VERSION ""

NS_ :

BS_:

BU_: HMI PCU
VAL_TABLE_ uint16_data_max_fault 65535 "Unavailable" ;
VAL_TABLE_ uint8_data_value_fault 255 "Unavailable" ;
VAL_TABLE_ float_data_value_fault 32767 "Unavailable" ;
VAL_TABLE_ uint8_data_value_fault 254 "Invalid" 255 "Unavailable" ;
VAL_TABLE_ uint16_data_value_fault 65535 "Unavailable" 65534 "Invalid" ;
VAL_TABLE_ P00_PCU_S_ActiveNotActive 1 "Not active" 0 "Active" ;
VAL_TABLE_ P00_PCU_S_ready 5 "Ready" 0 "Not ready" ;
VAL_TABLE_ P00_PCU_S_NDR 5 "EV_ndr_fault" 4 "EV_ndr_s" 3 "EV_ndr_p" 2 "EV_ndr_r" 1 "EV_ndr_d" 0 "EV ndr n" ;
VAL_TABLE_ P00_PCU_S_evMode 5 "EV mode slow charge" 4 "EV mode fast charge" 3 "EV mode ready" 2 "EV mode change over" 1 "EV mode precharge" 0 "EV mode off" ;
VAL_TABLE_ P00_PCU_S_systemMode 9 "system_mode_sna_s" 8 "system_mode_safe_s" 7 "system_mode_secure_shutdown_s" 6 "system_mode_degraded_s" 5 "system_mode_obd_s" 4 "system_mode_operational_s" 3 "system_mode_pre_operational_s" 2 "system_mode_warmup_s" 1 "system_mode_configuration_s" 0 "system_mode_initialisation_s" ;

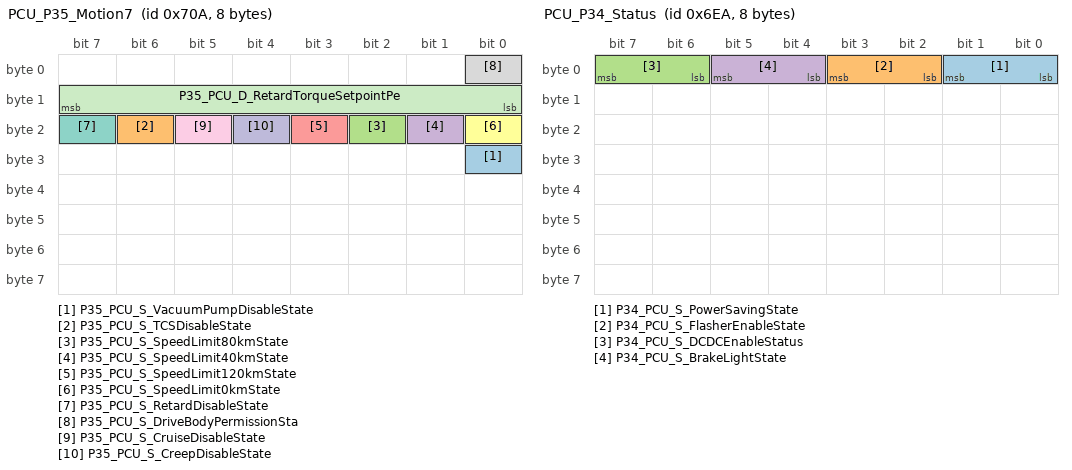
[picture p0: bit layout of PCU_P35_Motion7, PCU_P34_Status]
BO_ 1802 PCU_P35_Motion7: 8 PCU
 SG_ P35_PCU_S_VacuumPumpDisableState : 24|1@0+ (1,0) [0|1] ""  HMI
 SG_ P35_PCU_S_TCSDisableState : 22|1@0+ (1,0) [0|1] ""  HMI
 SG_ P35_PCU_S_SpeedLimit80kmState : 18|1@0+ (1,0) [0|1] ""  HMI
 SG_ P35_PCU_S_SpeedLimit40kmState : 17|1@0+ (1,0) [0|1] ""  HMI
 SG_ P35_PCU_S_SpeedLimit120kmState : 19|1@0+ (1,0) [0|1] ""  HMI
 SG_ P35_PCU_S_SpeedLimit0kmState : 16|1@0+ (1,0) [0|1] ""  HMI
 SG_ P35_PCU_S_RetardDisableState : 23|1@0+ (1,0) [0|1] ""  HMI
 SG_ P35_PCU_S_DriveBodyPermissionSta : 0|1@0+ (1,0) [0|1] ""  HMI
 SG_ P35_PCU_S_CruiseDisableState : 21|1@0+ (1,0) [0|1] ""  HMI
 SG_ P35_PCU_S_CreepDisableState : 20|1@0+ (1,0) [0|1] ""  HMI
 SG_ P35_PCU_D_RetardTorqueSetpointPe : 15|8@0+ (1,0) [0|100] "%"  HMI

BO_ 1770 PCU_P34_Status: 8 PCU
 SG_ P34_PCU_S_PowerSavingState : 1|2@0+ (1,0) [0|1] ""  HMI
 SG_ P34_PCU_S_FlasherEnableState : 3|2@0+ (1,0) [0|3] ""  HMI
 SG_ P34_PCU_S_DCDCEnableStatus : 7|2@0+ (1,0) [0|3] ""  HMI
 SG_ P34_PCU_S_BrakeLightState : 5|2@0+ (1,0) [0|3] ""  HMI

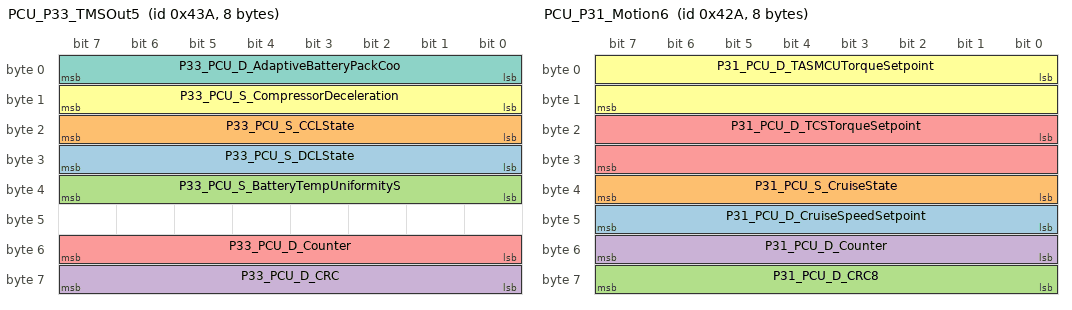
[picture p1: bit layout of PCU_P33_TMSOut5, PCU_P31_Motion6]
BO_ 1082 PCU_P33_TMSOut5: 8 PCU
 SG_ P33_PCU_S_DCLState : 31|8@0+ (1,0) [0|2] "" Vector__XXX
 SG_ P33_PCU_S_CCLState : 23|8@0+ (1,0) [0|2] "" Vector__XXX
 SG_ P33_PCU_S_BatteryTempUniformityS : 39|8@0+ (1,0) [0|2] "" Vector__XXX
 SG_ P33_PCU_D_CRC : 63|8@0+ (1,0) [0|255] ""  HMI
 SG_ P33_PCU_D_Counter : 55|8@0+ (1,0) [0|255] ""  HMI
 SG_ P33_PCU_S_CompressorDeceleration : 15|8@0+ (1,0) [0|1] ""  HMI
 SG_ P33_PCU_D_AdaptiveBatteryPackCoo : 7|8@0+ (1,0) [0|50] "�C"  HMI

BO_ 1066 PCU_P31_Motion6: 8 PCU
 SG_ P31_PCU_D_CruiseSpeedSetpoint : 40|8@1+ (100,0) [0|25300] "rpm"  HMI
 SG_ P31_PCU_S_CruiseState : 32|8@1+ (1,0) [0|2] ""  HMI
 SG_ P31_PCU_D_CRC8 : 63|8@0+ (1,0) [0|255] ""  HMI
 SG_ P31_PCU_D_Counter : 55|8@0+ (1,0) [0|255] ""  HMI
 SG_ P31_PCU_D_TCSTorqueSetpoint : 16|16@1+ (1,-300) [-210|210] "N.m"  HMI
 SG_ P31_PCU_D_TASMCUTorqueSetpoint : 0|16@1+ (1,-300) [-210|210] "N.m"  HMI

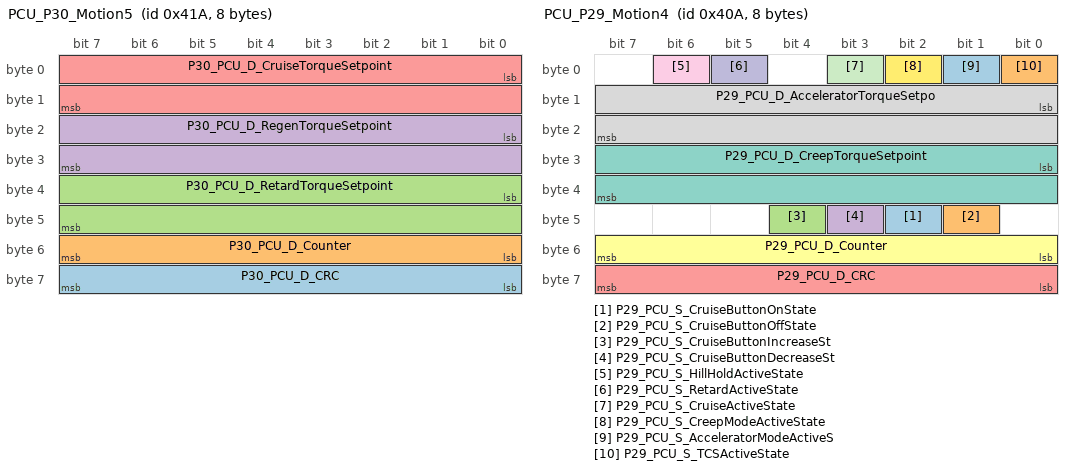
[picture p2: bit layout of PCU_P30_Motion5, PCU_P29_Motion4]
BO_ 1050 PCU_P30_Motion5: 8 PCU
 SG_ P30_PCU_D_CRC : 63|8@0+ (1,0) [0|255] ""  HMI
 SG_ P30_PCU_D_Counter : 55|8@0+ (1,0) [0|255] ""  HMI
 SG_ P30_PCU_D_RetardTorqueSetpoint : 32|16@1+ (1,-300) [0|210] "N.m"  HMI
 SG_ P30_PCU_D_RegenTorqueSetpoint : 16|16@1+ (1,-300) [0|210] "N.m"  HMI
 SG_ P30_PCU_D_CruiseTorqueSetpoint : 0|16@1+ (1,-300) [0|210] "N.m"  HMI

BO_ 1034 PCU_P29_Motion4: 8 PCU
 SG_ P29_PCU_S_CruiseButtonOnState : 42|1@0+ (1,0) [0|1] ""  HMI
 SG_ P29_PCU_S_CruiseButtonOffState : 41|1@0+ (1,0) [0|1] ""  HMI
 SG_ P29_PCU_S_CruiseButtonIncreaseSt : 44|1@0+ (1,0) [0|1] ""  HMI
 SG_ P29_PCU_S_CruiseButtonDecreaseSt : 43|1@0+ (1,0) [0|1] ""  HMI
 SG_ P29_PCU_D_CRC : 63|8@0+ (1,0) [0|255] ""  HMI
 SG_ P29_PCU_D_Counter : 55|8@0+ (1,0) [0|255] ""  HMI
 SG_ P29_PCU_D_CreepTorqueSetpoint : 24|16@1+ (1,-300) [0|210] "N.m"  HMI
 SG_ P29_PCU_D_AcceleratorTorqueSetpo : 8|16@1+ (1,-300) [0|210] "N.m"  HMI
 SG_ P29_PCU_S_HillHoldActiveState : 6|1@0+ (1,0) [0|1] ""  HMI
 SG_ P29_PCU_S_RetardActiveState : 5|1@0+ (1,0) [0|1] ""  HMI
 SG_ P29_PCU_S_CruiseActiveState : 3|1@0+ (1,0) [0|1] ""  HMI
 SG_ P29_PCU_S_CreepModeActiveState : 2|1@0+ (1,0) [0|1] ""  HMI
 SG_ P29_PCU_S_AcceleratorModeActiveS : 1|1@0+ (1,0) [0|1] ""  HMI
 SG_ P29_PCU_S_TCSActiveState : 0|1@0+ (1,0) [0|1] ""  HMI

BO_ 1578 PCU_P32_Fault: 8 PCU
 SG_ P32_PCU_F_EEPROMCellCycleTimeout : 36|1@0+ (1,0) [0|1] "" Vector__XXX
 SG_ P32_PCU_F_EEPROMMCUIDTimeoutFaul : 35|1@0+ (1,0) [0|1] "" Vector__XXX
 SG_ P32_PCU_F_DOLFault : 34|1@0+ (1,0) [0|1] "" Vector__XXX
 SG_ P32_PCU_F_FanLowSpeedAbnormalFau : 23|1@0+ (1,0) [0|1] ""  HMI
 SG_ P32_PCU_F_FanHighSpeedAbnormalFa : 22|1@0+ (1,0) [0|1] ""  HMI
 SG_ P32_PCU_F_CabinCoolerValveOpenWi : 29|1@0+ (1,0) [0|1] ""  HMI
 SG_ P32_PCU_F_BatteryChillerValveOpe : 27|1@0+ (1,0) [0|1] ""  HMI
 SG_ P32_PCU_F_FanHighSpeedAbnormalPr : 21|1@0+ (1,0) [0|1] ""  HMI
 SG_ P32_PCU_F_PressureSwitchAbnormal : 33|1@0+ (1,0) [0|1] ""  HMI
 SG_ P32_PCU_F_PressureSwitchHardware : 32|1@0+ (1,0) [0|1] ""  HMI
 SG_ P32_PCU_F_CabinCoolerValveShortC : 18|1@0+ (1,0) [0|1] ""  HMI
 SG_ P32_PCU_F_BatteryChillerValveSho : 16|1@0+ (1,0) [0|1] ""  HMI
 SG_ P32_PCU_F_FlashTimeoutFault : 12|1@0+ (1,0) [0|1] ""  HMI
 SG_ P32_PCU_F_EEPROMODOTimeoutFault : 11|1@0+ (1,0) [0|1] ""  HMI
 SG_ P32_PCU_F_CANFDTxFIFOFullFault : 10|1@0+ (1,0) [0|1] ""  HMI
 SG_ P32_PCU_F_CANFDTxBusOffFault : 9|1@0+ (1,0) [0|1] ""  HMI
 SG_ P32_PCU_F_CANFDTxBusPassiveFault : 8|1@0+ (1,0) [0|1] ""  HMI
 SG_ P32_PCU_F_CANFDRxBusPassiveFault : 7|1@0+ (1,0) [0|1] ""  HMI
 SG_ P32_PCU_F_DiSpiTemperatureShutDo : 6|1@0+ (1,0) [0|1] ""  HMI
 SG_ P32_PCU_F_DiSpiCheckFault : 2|1@0+ (1,0) [0|1] ""  HMI
 SG_ P32_PCU_F_DiSpiTemperatureWarnin : 5|1@0+ (1,0) [0|1] ""  HMI
 SG_ P32_PCU_F_DiSpiOverVoltageFault : 4|1@0+ (1,0) [0|1] ""  HMI
 SG_ P32_PCU_F_DiSpiUnderVoltageFault : 3|1@0+ (1,0) [0|1] ""  HMI
 SG_ P32_PCU_F_DiSpiParityFault : 1|1@0+ (1,0) [0|1] ""  HMI
 SG_ P32_PCU_F_DiSpiFault : 0|1@0+ (1,0) [0|1] ""  HMI
 SG_ P32_PCU_D_Counter : 55|8@0+ (1,0) [0|255] ""  HMI
 SG_ P32_PCU_D_CRC : 63|8@0+ (1,0) [0|255] ""  HMI

BO_ 1514 PCU_P26_Motion1: 8 PCU
 SG_ P26_PCU_S_RegenState : 9|1@0+ (1,0) [0|1] ""  HMI
 SG_ P26_PCU_S_RegenSOCDerateState : 20|1@0+ (1,0) [0|1] ""  HMI
 SG_ P26_PCU_S_RegenMotorDerateState : 18|1@0+ (1,0) [0|1] ""  HMI
 SG_ P26_PCU_S_RegenMCUDerateState : 17|1@0+ (1,0) [0|1] ""  HMI
 SG_ P26_PCU_S_RegenBatteryDerateStat : 19|1@0+ (1,0) [0|1] ""  HMI
 SG_ P26_PCU_S_HillholdPermissionStat : 8|1@0+ (1,0) [0|1] ""  HMI
 SG_ P26_PCU_D_ESCTorqueLimit : 32|16@1+ (1,0) [0|210] "N.m"  HMI
 SG_ P26_PCU_S_ESCTorqueLimitActiveSt : 10|1@0+ (1,0) [0|1] ""  HMI
 SG_ P26_PCU_S_DriveProcessorTempDera : 12|1@0+ (1,0) [0|1] ""  HMI
 SG_ P26_PCU_S_DriveMotorDerateState : 14|1@0+ (1,0) [0|1] ""  HMI
 SG_ P26_PCU_S_DriveMCUDerateState : 13|1@0+ (1,0) [0|1] ""  HMI
 SG_ P26_PCU_S_DriveLVVoltageDerateSt : 11|1@0+ (1,0) [0|1] ""  HMI
 SG_ P26_PCU_S_DriveBatteryDerateStat : 15|1@0+ (1,0) [0|1] ""  HMI
 SG_ P26_PCU_S_DriveSOCDerateState : 16|1@0+ (1,0) [0|1] ""  HMI
 SG_ P26_PCU_S_TCSPermissionState : 0|1@0+ (1,0) [0|1] ""  HMI
 SG_ P26_PCU_S_DrivePermissionState : 1|1@0+ (1,0) [0|1] ""  HMI
 SG_ P26_PCU_S_CreepPermissionState : 2|1@0+ (1,0) [0|1] ""  HMI
 SG_ P26_PCU_S_CruisePermissionState : 3|1@0+ (1,0) [0|1] ""  HMI
 SG_ P26_PCU_S_RetardPermissionState : 5|1@0+ (1,0) [0|1] ""  HMI
 SG_ P26_PCU_S_DriveDerateState : 6|1@0+ (1,0) [0|1] ""  HMI
 SG_ P26_PCU_S_RegenDerateState : 7|1@0+ (1,0) [0|1] ""  HMI
 SG_ P26_PCU_D_MotorMaxPower : 31|8@0+ (1,0) [0|125] "kW"  HMI
 SG_ P26_PCU_D_Counter : 55|8@0+ (1,0) [0|255] ""  HMI
 SG_ P26_PCU_D_CRC : 63|8@0+ (1,0) [0|255] ""  HMI

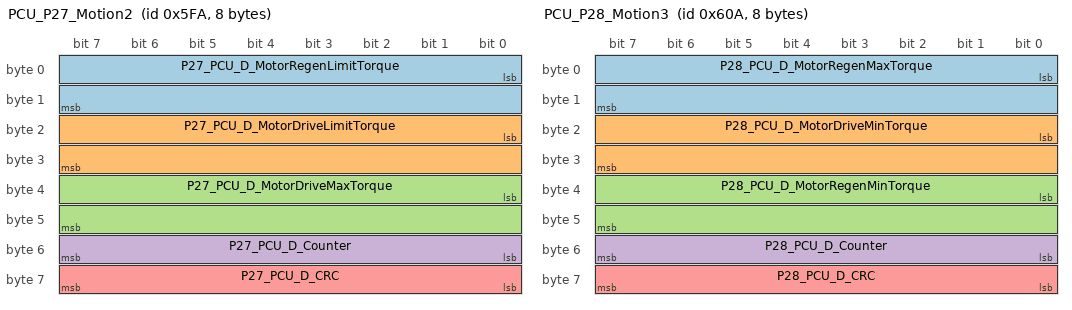
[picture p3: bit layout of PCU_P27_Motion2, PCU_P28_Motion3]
BO_ 1530 PCU_P27_Motion2: 8 PCU
 SG_ P27_PCU_D_MotorRegenLimitTorque : 0|16@1+ (1,0) [0|150] "N.m"  HMI
 SG_ P27_PCU_D_MotorDriveLimitTorque : 16|16@1+ (1,0) [0|210] "N.m"  HMI
 SG_ P27_PCU_D_MotorDriveMaxTorque : 32|16@1+ (1,0) [0|210] "N.m"  HMI
 SG_ P27_PCU_D_Counter : 55|8@0+ (1,0) [0|255] ""  HMI
 SG_ P27_PCU_D_CRC : 63|8@0+ (1,0) [0|255] ""  HMI

BO_ 1546 PCU_P28_Motion3: 8 PCU
 SG_ P28_PCU_D_MotorRegenMaxTorque : 0|16@1+ (1,0) [0|150] "N.m"  HMI
 SG_ P28_PCU_D_MotorDriveMinTorque : 16|16@1+ (1,0) [0|210] "N.m"  HMI
 SG_ P28_PCU_D_MotorRegenMinTorque : 32|16@1+ (1,0) [0|150] "N.m"  HMI
 SG_ P28_PCU_D_Counter : 55|8@0+ (1,0) [0|255] ""  HMI
 SG_ P28_PCU_D_CRC : 63|8@0+ (1,0) [0|255] ""  HMI

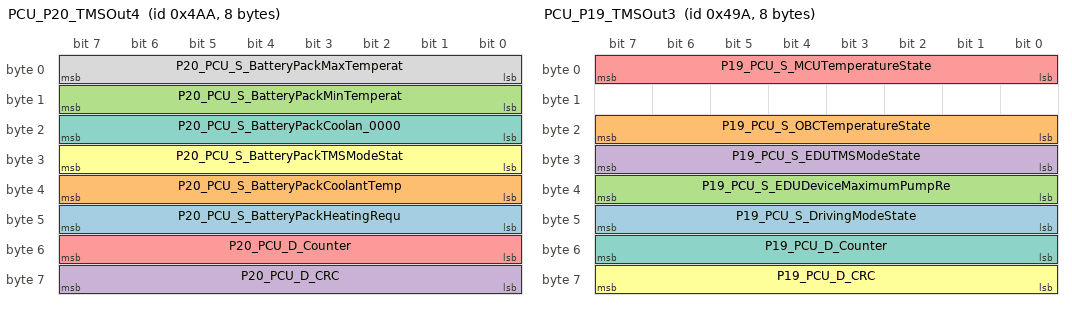
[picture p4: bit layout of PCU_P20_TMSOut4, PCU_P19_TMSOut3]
BO_ 1194 PCU_P20_TMSOut4: 8 PCU
 SG_ P20_PCU_S_BatteryPackHeatingRequ : 47|8@0+ (1,0) [0|1] ""  HMI
 SG_ P20_PCU_S_BatteryPackCoolantTemp : 39|8@0+ (1,0) [0|2] ""  HMI
 SG_ P20_PCU_S_BatteryPackMinTemperat : 15|8@0+ (1,0) [0|11] ""  HMI
 SG_ P20_PCU_D_CRC : 63|8@0+ (1,0) [0|255] ""  HMI
 SG_ P20_PCU_D_Counter : 55|8@0+ (1,0) [0|255] ""  HMI
 SG_ P20_PCU_S_BatteryPackTMSModeStat : 31|8@0+ (1,0) [0|14] ""  HMI
 SG_ P20_PCU_S_BatteryPackCoolan_0000 : 23|8@0+ (1,0) [0|11] ""  HMI
 SG_ P20_PCU_S_BatteryPackMaxTemperat : 7|8@0+ (1,0) [0|11] ""  HMI

BO_ 1178 PCU_P19_TMSOut3: 8 PCU
 SG_ P19_PCU_S_DrivingModeState : 47|8@0+ (1,0) [0|1] ""  HMI
 SG_ P19_PCU_S_OBCTemperatureState : 23|8@0+ (1,0) [0|11] ""  HMI
 SG_ P19_PCU_S_EDUDeviceMaximumPumpRe : 39|8@0+ (1,0) [0|5] ""  HMI
 SG_ P19_PCU_S_EDUTMSModeState : 31|8@0+ (1,0) [0|14] ""  HMI
 SG_ P19_PCU_S_MCUTemperatureState : 7|8@0+ (1,0) [0|11] ""  HMI
 SG_ P19_PCU_D_CRC : 63|8@0+ (1,0) [0|255] ""  HMI
 SG_ P19_PCU_D_Counter : 55|8@0+ (1,0) [0|255] ""  HMI

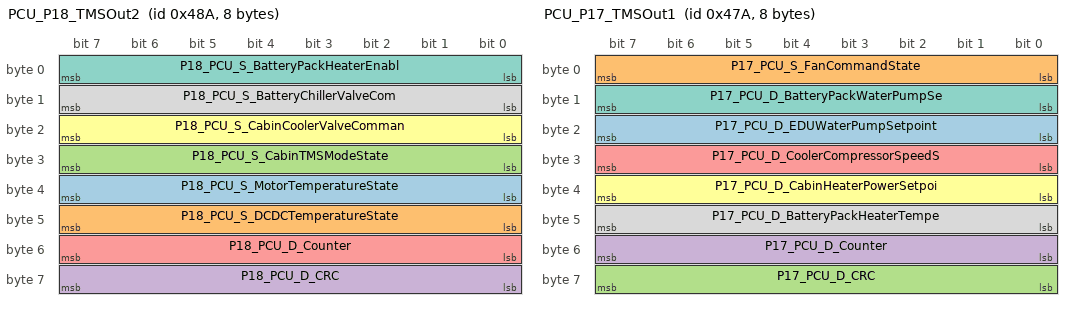
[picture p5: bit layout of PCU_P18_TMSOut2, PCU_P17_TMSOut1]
BO_ 1162 PCU_P18_TMSOut2: 8 PCU
 SG_ P18_PCU_S_MotorTemperatureState : 39|8@0+ (1,0) [0|11] ""  HMI
 SG_ P18_PCU_S_DCDCTemperatureState : 47|8@0+ (1,0) [0|11] ""  HMI
 SG_ P18_PCU_S_CabinTMSModeState : 31|8@0+ (1,0) [0|8] ""  HMI
 SG_ P18_PCU_D_CRC : 63|8@0+ (1,0) [0|255] ""  HMI
 SG_ P18_PCU_D_Counter : 55|8@0+ (1,0) [0|255] ""  HMI
 SG_ P18_PCU_S_CabinCoolerValveComman : 23|8@0+ (1,0) [0|1] ""  HMI
 SG_ P18_PCU_S_BatteryPackHeaterEnabl : 7|8@0+ (1,0) [0|1] ""  HMI
 SG_ P18_PCU_S_BatteryChillerValveCom : 15|8@0+ (1,0) [0|1] ""  HMI

BO_ 1146 PCU_P17_TMSOut1: 8 PCU
 SG_ P17_PCU_D_EDUWaterPumpSetpoint : 23|8@0+ (1,0) [0|100] "%"  HMI
 SG_ P17_PCU_S_FanCommandState : 7|8@0+ (1,0) [0|2] ""  HMI
 SG_ P17_PCU_D_CRC : 63|8@0+ (1,0) [0|255] ""  HMI
 SG_ P17_PCU_D_Counter : 55|8@0+ (1,0) [0|255] ""  HMI
 SG_ P17_PCU_D_CoolerCompressorSpeedS : 31|8@0+ (1,0) [0|100] "%"  HMI
 SG_ P17_PCU_D_CabinHeaterPowerSetpoi : 39|8@0+ (1,0) [0|100] "%"  HMI
 SG_ P17_PCU_D_BatteryPackWaterPumpSe : 15|8@0+ (1,0) [0|100] "%"  HMI
 SG_ P17_PCU_D_BatteryPackHeaterTempe : 47|8@0+ (1,0) [0|80] "�C"  HMI

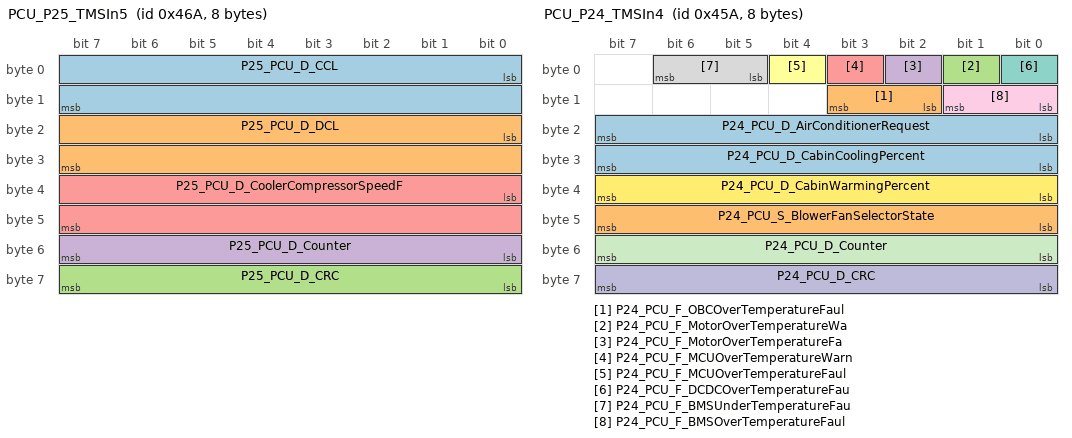
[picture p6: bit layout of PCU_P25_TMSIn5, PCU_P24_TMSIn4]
BO_ 1130 PCU_P25_TMSIn5: 8 PCU
 SG_ P25_PCU_D_CCL : 0|16@1+ (1,0) [0|650] "A"  HMI
 SG_ P25_PCU_D_DCL : 16|16@1+ (1,0) [0|650] "A"  HMI
 SG_ P25_PCU_D_CRC : 63|8@0+ (1,0) [0|255] ""  HMI
 SG_ P25_PCU_D_Counter : 55|8@0+ (1,0) [0|255] ""  HMI
 SG_ P25_PCU_D_CoolerCompressorSpeedF : 32|16@1+ (1,0) [0|16000] "rpm"  HMI

BO_ 1114 PCU_P24_TMSIn4: 8 PCU
 SG_ P24_PCU_D_AirConditionerRequest : 23|8@0+ (1,0) [0|1] ""  HMI
 SG_ P24_PCU_F_OBCOverTemperatureFaul : 11|2@0+ (1,0) [0|3] ""  HMI
 SG_ P24_PCU_F_MotorOverTemperatureWa : 1|1@0+ (1,0) [0|1] ""  HMI
 SG_ P24_PCU_F_MotorOverTemperatureFa : 2|1@0+ (1,0) [0|1] ""  HMI
 SG_ P24_PCU_F_MCUOverTemperatureWarn : 3|1@0+ (1,0) [0|1] ""  HMI
 SG_ P24_PCU_F_MCUOverTemperatureFaul : 4|1@0+ (1,0) [0|1] ""  HMI
 SG_ P24_PCU_F_DCDCOverTemperatureFau : 0|1@0+ (1,0) [0|1] ""  HMI
 SG_ P24_PCU_F_BMSUnderTemperatureFau : 6|2@0+ (1,0) [0|3] ""  HMI
 SG_ P24_PCU_F_BMSOverTemperatureFaul : 9|2@0+ (1,0) [0|3] ""  HMI
 SG_ P24_PCU_D_CRC : 63|8@0+ (1,0) [0|255] ""  HMI
 SG_ P24_PCU_D_Counter : 55|8@0+ (1,0) [0|255] ""  HMI
 SG_ P24_PCU_D_CabinWarmingPercent : 39|8@0+ (1,0) [0|100] "%"  HMI
 SG_ P24_PCU_D_CabinCoolingPercent : 31|8@0+ (1,0) [0|100] "%"  HMI
 SG_ P24_PCU_S_BlowerFanSelectorState : 47|8@0+ (1,0) [0|1] ""  HMI

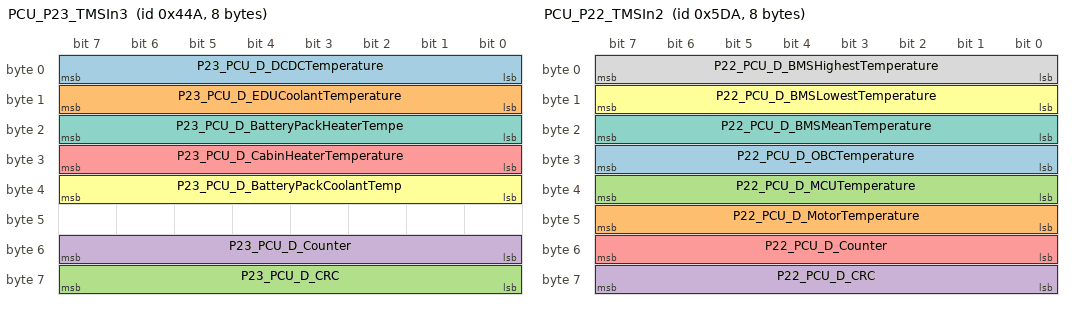
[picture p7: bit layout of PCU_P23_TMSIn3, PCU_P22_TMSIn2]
BO_ 1098 PCU_P23_TMSIn3: 8 PCU
 SG_ P23_PCU_D_DCDCTemperature : 7|8@0+ (1,-40) [-40|210] "�C"  HMI
 SG_ P23_PCU_D_EDUCoolantTemperature : 15|8@0+ (1,-40) [-11|110] "�C"  HMI
 SG_ P23_PCU_D_CRC : 63|8@0+ (1,0) [0|255] ""  HMI
 SG_ P23_PCU_D_Counter : 55|8@0+ (1,0) [0|255] ""  HMI
 SG_ P23_PCU_D_CabinHeaterTemperature : 31|8@0+ (1,-40) [-40|190] "�C"  HMI
 SG_ P23_PCU_D_BatteryPackCoolantTemp : 39|8@0+ (1,-40) [-28|85] "�C"  HMI
 SG_ P23_PCU_D_BatteryPackHeaterTempe : 23|8@0+ (1,-40) [-40|180] "�C"  HMI

BO_ 1498 PCU_P22_TMSIn2: 8 PCU
 SG_ P22_PCU_D_OBCTemperature : 31|8@0+ (1,-40) [-40|210] "�C"  HMI
 SG_ P22_PCU_D_MotorTemperature : 47|8@0+ (1,-40) [-40|210] "�C"  HMI
 SG_ P22_PCU_D_MCUTemperature : 39|8@0+ (1,-40) [-40|210] "�C"  HMI
 SG_ P22_PCU_D_CRC : 63|8@0+ (1,0) [0|255] ""  HMI
 SG_ P22_PCU_D_Counter : 55|8@0+ (1,0) [0|255] ""  HMI
 SG_ P22_PCU_D_BMSLowestTemperature : 15|8@0+ (1,-40) [-40|125] "�C"  HMI
 SG_ P22_PCU_D_BMSMeanTemperature : 23|8@0+ (1,-40) [-40|125] "�C"  HMI
 SG_ P22_PCU_D_BMSHighestTemperature : 7|8@0+ (1,-40) [-40|125] "�C"  HMI

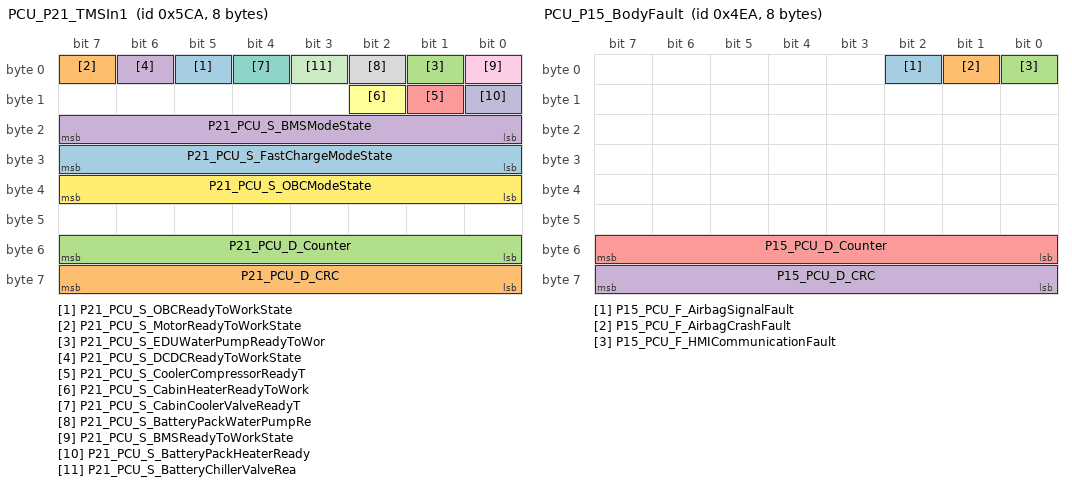
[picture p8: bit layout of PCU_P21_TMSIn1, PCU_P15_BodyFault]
BO_ 1482 PCU_P21_TMSIn1: 8 PCU
 SG_ P21_PCU_S_OBCReadyToWorkState : 5|1@0+ (1,0) [0|1] ""  HMI
 SG_ P21_PCU_S_MotorReadyToWorkState : 7|1@0+ (1,0) [0|1] ""  HMI
 SG_ P21_PCU_S_EDUWaterPumpReadyToWor : 1|1@0+ (1,0) [0|1] ""  HMI
 SG_ P21_PCU_S_DCDCReadyToWorkState : 6|1@0+ (1,0) [0|1] ""  HMI
 SG_ P21_PCU_S_CoolerCompressorReadyT : 9|1@0+ (1,0) [0|1] ""  HMI
 SG_ P21_PCU_S_CabinHeaterReadyToWork : 10|1@0+ (1,0) [0|1] ""  HMI
 SG_ P21_PCU_S_CabinCoolerValveReadyT : 4|1@0+ (1,0) [0|1] ""  HMI
 SG_ P21_PCU_S_BatteryPackWaterPumpRe : 2|1@0+ (1,0) [0|1] ""  HMI
 SG_ P21_PCU_S_BMSReadyToWorkState : 0|1@0+ (1,0) [0|1] ""  HMI
 SG_ P21_PCU_S_BatteryPackHeaterReady : 8|1@0+ (1,0) [0|1] ""  HMI
 SG_ P21_PCU_S_BatteryChillerValveRea : 3|1@0+ (1,0) [0|1] ""  HMI
 SG_ P21_PCU_S_OBCModeState : 39|8@0+ (1,0) [0|5] ""  HMI
 SG_ P21_PCU_S_FastChargeModeState : 31|8@0+ (1,0) [0|7] ""  HMI
 SG_ P21_PCU_D_CRC : 63|8@0+ (1,0) [0|255] ""  HMI
 SG_ P21_PCU_D_Counter : 55|8@0+ (1,0) [0|255] ""  HMI
 SG_ P21_PCU_S_BMSModeState : 23|8@0+ (1,0) [0|7] ""  HMI

BO_ 1274 PCU_P16_TMSFault: 8 PCU
 SG_ P16_PCU_F_TMSBatteryPackTemperat : 36|1@0+ (1,0) [0|1] "" Vector__XXX
 SG_ P16_PCU_F_EDUWaterPumpNoLoadingF : 24|1@0+ (1,0) [0|1] "" Vector__XXX
 SG_ P16_PCU_F_BatteryPackWaterPumpNo : 28|1@0+ (1,0) [0|1] "" Vector__XXX
 SG_ P16_PCU_F_TMSCoolingActuatorPowe : 41|1@0+ (1,0) [0|1] ""  HMI
 SG_ P16_PCU_F_CoolerCompressorHVILFa : 39|1@0+ (1,0) [0|1] ""  HMI
 SG_ P16_PCU_F_BatteryPackHeaterHVILF : 40|1@0+ (1,0) [0|1] ""  HMI
 SG_ P16_PCU_F_BothPumpCommunicationF : 38|1@0+ (1,0) [0|1] ""  HMI
 SG_ P16_PCU_F_BatteryPackHeaterOverC : 37|1@0+ (1,0) [0|1] ""  HMI
 SG_ P16_PCU_F_TMSOBCShutdownFault : 32|1@0+ (1,0) [0|1] ""  HMI
 SG_ P16_PCU_F_TMSMotorShutdownFault : 35|1@0+ (1,0) [0|1] ""  HMI
 SG_ P16_PCU_F_TMSMCUShutdownFault : 34|1@0+ (1,0) [0|1] ""  HMI
 SG_ P16_PCU_F_TMSDCDCShutdownFault : 33|1@0+ (1,0) [0|1] ""  HMI
 SG_ P16_PCU_F_CoolerCompressorOverCu : 6|1@0+ (1,0) [0|1] ""  HMI
 SG_ P16_PCU_F_AirConditionerKeyMisma : 31|1@0+ (1,0) [0|1] ""  HMI
 SG_ P16_PCU_F_EDUCoolantTemperatureS : 30|1@0+ (1,0) [0|1] ""  HMI
 SG_ P16_PCU_F_BatteryPackCoolantTemp : 29|1@0+ (1,0) [0|1] ""  HMI
 SG_ P16_PCU_F_EDUWaterPumpUpdatePara : 23|1@0+ (1,0) [0|1] ""  HMI
 SG_ P16_PCU_F_BatteryPackWaterPumpUp : 27|1@0+ (1,0) [0|1] ""  HMI
 SG_ P16_PCU_F_BatteryPackHeaterHighV : 18|1@0+ (1,0) [0|1] ""  HMI
 SG_ P16_PCU_F_BatteryPackHeaterPower : 17|1@0+ (1,0) [0|1] ""  HMI
 SG_ P16_PCU_F_BatteryPackHeaterShort : 16|1@0+ (1,0) [0|1] ""  HMI
 SG_ P16_PCU_F_CabinHeaterHighVoltage : 12|1@0+ (1,0) [0|1] ""  HMI
 SG_ P16_PCU_F_CabinHeaterPowerUpFaul : 11|1@0+ (1,0) [0|1] ""  HMI
 SG_ P16_PCU_F_CabinHeaterShortCircui : 10|1@0+ (1,0) [0|1] ""  HMI
 SG_ P16_PCU_F_CoolerCompressorHighVo : 5|1@0+ (1,0) [0|1] ""  HMI
 SG_ P16_PCU_F_EDUWaterPumpInternalFa : 22|1@0+ (1,0) [0|1] ""  HMI
 SG_ P16_PCU_F_EDUWaterPumpCommunicat : 21|1@0+ (1,0) [0|1] ""  HMI
 SG_ P16_PCU_F_CoolerCompressorUpdate : 2|1@0+ (1,0) [0|1] ""  HMI
 SG_ P16_PCU_F_CoolerCompressorSpeedF : 4|1@0+ (1,0) [0|1] ""  HMI
 SG_ P16_PCU_F_CoolerCompressorShortC : 3|1@0+ (1,0) [0|1] ""  HMI
 SG_ P16_PCU_F_CoolerCompressorIntern : 0|1@0+ (1,0) [0|1] ""  HMI
 SG_ P16_PCU_F_CoolerCompressorCommun : 1|1@0+ (1,0) [0|1] ""  HMI
 SG_ P16_PCU_F_CabinCoolerValveFault : 19|1@0+ (1,0) [0|1] ""  HMI
 SG_ P16_PCU_F_BatteryPackWaterPumpIn : 26|1@0+ (1,0) [0|1] ""  HMI
 SG_ P16_PCU_F_BatteryPackWaterPumpCo : 25|1@0+ (1,0) [0|1] ""  HMI
 SG_ P16_PCU_F_BatteryPackHeaterUpdat : 15|1@0+ (1,0) [0|1] ""  HMI
 SG_ P16_PCU_F_BatteryPackHeaterInter : 13|1@0+ (1,0) [0|1] ""  HMI
 SG_ P16_PCU_F_BatteryPackHeaterCommu : 14|1@0+ (1,0) [0|1] ""  HMI
 SG_ P16_PCU_F_BatteryChillerValveFau : 20|1@0+ (1,0) [0|1] ""  HMI
 SG_ P16_PCU_F_CabinHeaterUpdateParam : 9|1@0+ (1,0) [0|1] ""  HMI
 SG_ P16_PCU_F_CabinHeaterInternalFau : 7|1@0+ (1,0) [0|1] ""  HMI
 SG_ P16_PCU_F_CabinHeaterCommunicati : 8|1@0+ (1,0) [0|1] ""  HMI
 SG_ P16_PCU_D_CRC : 63|8@0+ (1,0) [0|255] ""  HMI
 SG_ P16_PCU_D_Counter : 55|8@0+ (1,0) [0|255] ""  HMI

BO_ 1258 PCU_P15_BodyFault: 8 PCU
 SG_ P15_PCU_F_AirbagSignalFault : 2|1@0+ (1,0) [0|1] "" Vector__XXX
 SG_ P15_PCU_F_AirbagCrashFault : 1|1@0+ (1,0) [0|1] ""  HMI
 SG_ P15_PCU_F_HMICommunicationFault : 0|1@0+ (1,0) [0|1] ""  HMI
 SG_ P15_PCU_D_CRC : 63|8@0+ (1,0) [0|255] ""  HMI
 SG_ P15_PCU_D_Counter : 55|8@0+ (1,0) [0|255] ""  HMI

BO_ 1242 PCU_P14_EVFault: 8 PCU
 SG_ P14_PCU_F_PCUCANTimeoutFault : 26|1@0+ (1,0) [0|1] "" Vector__XXX
 SG_ P14_PCU_F_EVSOCSlowOverLimitFaul : 22|1@0+ (1,0) [0|1] "" Vector__XXX
 SG_ P14_PCU_F_EVSOCFastOverLimitFaul : 23|1@0+ (1,0) [0|1] "" Vector__XXX
 SG_ P14_PCU_F_EVPluggingFault : 6|1@0+ (1,0) [0|1] ""  HMI
 SG_ P14_PCU_F_EVHVOpenFault : 27|1@0+ (1,0) [0|1] ""  HMI
 SG_ P14_PCU_F_MCUVINMismatchFault : 25|1@0+ (1,0) [0|1] ""  HMI
 SG_ P14_PCU_F_EVAirbagCrashDetectedF : 24|1@0+ (1,0) [0|1] ""  HMI
 SG_ P14_PCU_F_EVInPluggedFault : 21|1@0+ (1,0) [0|1] ""  HMI
 SG_ P14_PCU_F_ProcessorMissingClockD : 5|1@0+ (1,0) [0|1] ""  HMI
 SG_ P14_PCU_F_ProcessorOverTemperatu : 4|1@0+ (1,0) [0|1] ""  HMI
 SG_ P14_PCU_F_5VSupplyUnderVoltageFa : 1|1@0+ (1,0) [0|1] ""  HMI
 SG_ P14_PCU_F_5VSupplyOverVoltageFau : 0|1@0+ (1,0) [0|1] ""  HMI
 SG_ P14_PCU_F_InputUnderVoltageFault : 3|1@0+ (1,0) [0|1] ""  HMI
 SG_ P14_PCU_F_InputOverVoltageFault : 2|1@0+ (1,0) [0|1] ""  HMI
 SG_ P14_PCU_F_EVStartSwitchFault : 17|1@0+ (1,0) [0|1] ""  HMI
 SG_ P14_PCU_F_EVSOCLowFault : 11|1@0+ (1,0) [0|1] ""  HMI
 SG_ P14_PCU_F_EVSOCLimitFault : 12|1@0+ (1,0) [0|1] ""  HMI
 SG_ P14_PCU_F_EVPrechargeTimeoutFaul : 14|1@0+ (1,0) [0|1] ""  HMI
 SG_ P14_PCU_F_EVDCUNotReadyFault : 9|1@0+ (1,0) [0|1] ""  HMI
 SG_ P14_PCU_F_EVDCDCNotReadyFault : 10|1@0+ (1,0) [0|1] ""  HMI
 SG_ P14_PCU_F_EVBMSOpenContactorFaul : 18|1@0+ (1,0) [0|1] ""  HMI
 SG_ P14_PCU_F_EVChargeStopFault : 16|1@0+ (1,0) [0|1] ""  HMI
 SG_ P14_PCU_F_EVBMSNotReadyFault : 8|1@0+ (1,0) [0|1] ""  HMI
 SG_ P14_PCU_D_CRC : 63|8@0+ (1,0) [0|255] ""  HMI
 SG_ P14_PCU_D_Counter : 55|8@0+ (1,0) [0|255] ""  HMI

BO_ 1226 PCU_P13_HVLVFault: 8 PCU
 SG_ P13_PCU_F_OBCOverCurrentFault : 28|1@0+ (1,0) [0|1] ""  HMI
 SG_ P13_PCU_F_BMSModeFault : 27|1@0+ (1,0) [0|1] ""  HMI
 SG_ P13_PCU_F_OBCHighVoltageFault : 26|1@0+ (1,0) [0|1] ""  HMI
 SG_ P13_PCU_F_OBCShortCircuitFault : 25|1@0+ (1,0) [0|1] ""  HMI
 SG_ P13_PCU_F_MCUHighVoltageFault : 21|1@0+ (1,0) [0|1] ""  HMI
 SG_ P13_PCU_F_OBCUpdateParameterFaul : 24|1@0+ (1,0) [0|1] ""  HMI
 SG_ P13_PCU_F_OBCInternalFault : 22|1@0+ (1,0) [0|1] ""  HMI
 SG_ P13_PCU_F_OBCCommunicationFault : 23|1@0+ (1,0) [0|1] ""  HMI
 SG_ P13_PCU_F_MCUUpdateParameterFaul : 20|1@0+ (1,0) [0|1] ""  HMI
 SG_ P13_PCU_F_MCUInternalFault : 18|1@0+ (1,0) [0|1] ""  HMI
 SG_ P13_PCU_F_MCUCommunicationFault : 19|1@0+ (1,0) [0|1] ""  HMI
 SG_ P13_PCU_F_DCDCUpdateParameterFau : 14|1@0+ (1,0) [0|1] ""  HMI
 SG_ P13_PCU_F_DCDCOverTemperatureFau : 16|1@0+ (1,0) [0|1] ""  HMI
 SG_ P13_PCU_F_DCDCLVUnderVoltageFaul : 17|1@0+ (1,0) [0|1] ""  HMI
 SG_ P13_PCU_F_DCDCInternalFault : 12|1@0+ (1,0) [0|1] ""  HMI
 SG_ P13_PCU_F_DCDCHighVoltageFault : 15|1@0+ (1,0) [0|1] ""  HMI
 SG_ P13_PCU_F_DCDCCommunicationFault : 13|1@0+ (1,0) [0|1] ""  HMI
 SG_ P13_PCU_F_BMSUpdateParameterFaul : 2|1@0+ (1,0) [0|1] ""  HMI
 SG_ P13_PCU_F_BMSInternalFault : 0|1@0+ (1,0) [0|1] ""  HMI
 SG_ P13_PCU_F_BMSCommunicationFault : 1|1@0+ (1,0) [0|1] ""  HMI
 SG_ P13_PCU_D_CRC : 63|8@0+ (1,0) [0|255] ""  HMI
 SG_ P13_PCU_D_Counter : 55|8@0+ (1,0) [0|255] ""  HMI
 SG_ P13_PCU_F_NegativeContactorWeldi : 11|1@0+ (1,0) [0|1] ""  HMI
 SG_ P13_PCU_F_NegativeContactorMatch : 9|1@0+ (1,0) [0|1] ""  HMI
 SG_ P13_PCU_F_PositiveContactorWeldi : 8|1@0+ (1,0) [0|1] ""  HMI
 SG_ P13_PCU_F_PositiveContactorMatch : 6|1@0+ (1,0) [0|1] ""  HMI
 SG_ P13_PCU_F_PrechargeContactorWeld : 5|1@0+ (1,0) [0|1] ""  HMI
 SG_ P13_PCU_F_PrechargeContactorMatc : 3|1@0+ (1,0) [0|1] ""  HMI

BO_ 1210 PCU_P12_MotionFault: 8 PCU
 SG_ P12_PCU_F_VacuumPumpPowerFault : 39|1@0+ (1,0) [0|1] ""  HMI
 SG_ P12_PCU_F_EPSInternalFault : 38|1@0+ (1,0) [0|1] ""  HMI
 SG_ P12_PCU_F_BrakePressureInvalidFa : 34|1@0+ (1,0) [0|1] ""  HMI
 SG_ P12_PCU_F_AcceleratorPedalPositi : 33|1@0+ (1,0) [0|1] ""  HMI
 SG_ P12_PCU_F_ESCCommunicationFault : 36|1@0+ (1,0) [0|1] ""  HMI
 SG_ P12_PCU_F_EPSCommunicationFault : 37|1@0+ (1,0) [0|1] ""  HMI
 SG_ P12_PCU_F_BrakeStopLightFault : 35|1@0+ (1,0) [0|1] ""  HMI
 SG_ P12_PCU_F_SASUpdateParameterFaul : 31|1@0+ (1,0) [0|1] ""  HMI
 SG_ P12_PCU_F_SASInternalFault : 29|1@0+ (1,0) [0|1] ""  HMI
 SG_ P12_PCU_F_SASCommunicationFault : 30|1@0+ (1,0) [0|1] ""  HMI
 SG_ P12_PCU_F_CruiseKeyOpenWireFault : 32|1@0+ (1,0) [0|1] ""  HMI
 SG_ P12_PCU_F_ABSRearRightSpeedFault : 28|1@0+ (1,0) [0|1] ""  HMI
 SG_ P12_PCU_F_ABSRearLeftSpeedFault : 27|1@0+ (1,0) [0|1] ""  HMI
 SG_ P12_PCU_F_ABSFrontRightSpeedFaul : 26|1@0+ (1,0) [0|1] ""  HMI
 SG_ P12_PCU_F_ABSFrontLeftSpeedFault : 25|1@0+ (1,0) [0|1] ""  HMI
 SG_ P12_PCU_F_ABSCommunicationFault : 24|1@0+ (1,0) [0|1] ""  HMI
 SG_ P12_PCU_F_BrakePedalMicroSwitchF : 16|1@0+ (1,0) [0|1] ""  HMI
 SG_ P12_PCU_F_AcceleratorPedalP_0000 : 5|1@0+ (1,0) [0|1] ""  HMI
 SG_ P12_PCU_F_AcceleratorPedalP_0001 : 4|1@0+ (1,0) [0|1] ""  HMI
 SG_ P12_PCU_F_AcceleratorPedalP_0002 : 6|1@0+ (1,0) [0|1] ""  HMI
 SG_ P12_PCU_F_AcceleratorPedalP_0003 : 3|1@0+ (1,0) [0|1] ""  HMI
 SG_ P12_PCU_F_AcceleratorPedalP_0004 : 1|1@0+ (1,0) [0|1] ""  HMI
 SG_ P12_PCU_F_VacuumPumpSensorMalfun : 21|1@0+ (1,0) [0|1] ""  HMI
 SG_ P12_PCU_F_VacuumPumpCurrentAbnor : 22|1@0+ (1,0) [0|1] ""  HMI
 SG_ P12_PCU_F_VacuumPumpPowerAbnorma : 23|1@0+ (1,0) [0|1] ""  HMI
 SG_ P12_PCU_F_VacuumPumpMajorFault : 20|1@0+ (1,0) [0|1] ""  HMI
 SG_ P12_PCU_F_AcceleratorPedalP_0005 : 7|1@0+ (1,0) [0|1] ""  HMI
 SG_ P12_PCU_F_AcceleratorPedalP_0006 : 2|1@0+ (1,0) [0|1] ""  HMI
 SG_ P12_PCU_F_AcceleratorPedalP_0007 : 0|1@0+ (1,0) [0|1] ""  HMI
 SG_ P12_PCU_F_NDRUpdateParameterFaul : 18|1@0+ (1,0) [0|1] ""  HMI
 SG_ P12_PCU_F_NDRInternalFault : 17|1@0+ (1,0) [0|1] ""  HMI
 SG_ P12_PCU_F_NDRCommunicationFault : 19|1@0+ (1,0) [0|1] ""  HMI
 SG_ P12_PCU_D_CRC : 63|8@0+ (1,0) [0|255] ""  HMI
 SG_ P12_PCU_D_Counter : 55|8@0+ (1,0) [0|255] ""  HMI

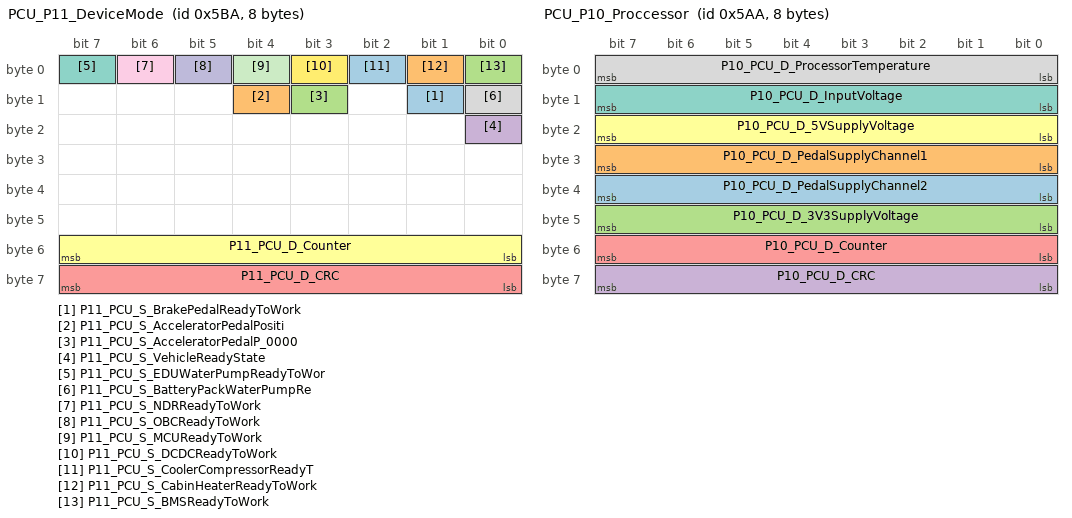
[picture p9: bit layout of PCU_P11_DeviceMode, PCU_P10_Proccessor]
BO_ 1466 PCU_P11_DeviceMode: 8 PCU
 SG_ P11_PCU_S_BrakePedalReadyToWork : 9|1@0+ (1,0) [0|1] ""  HMI
 SG_ P11_PCU_S_AcceleratorPedalPositi : 12|1@0+ (1,0) [0|1] ""  HMI
 SG_ P11_PCU_S_AcceleratorPedalP_0000 : 11|1@0+ (1,0) [0|1] ""  HMI
 SG_ P11_PCU_S_VehicleReadyState : 16|1@0+ (1,0) [0|1] ""  HMI
 SG_ P11_PCU_D_CRC : 63|8@0+ (1,0) [0|255] ""  HMI
 SG_ P11_PCU_D_Counter : 55|8@0+ (1,0) [0|255] ""  HMI
 SG_ P11_PCU_S_EDUWaterPumpReadyToWor : 7|1@0+ (1,0) [0|1] ""  HMI
 SG_ P11_PCU_S_BatteryPackWaterPumpRe : 8|1@0+ (1,0) [0|1] ""  HMI
 SG_ P11_PCU_S_NDRReadyToWork : 6|1@0+ (1,0) [0|1] ""  HMI
 SG_ P11_PCU_S_OBCReadyToWork : 5|1@0+ (1,0) [0|1] ""  HMI
 SG_ P11_PCU_S_MCUReadyToWork : 4|1@0+ (1,0) [0|1] ""  HMI
 SG_ P11_PCU_S_DCDCReadyToWork : 3|1@0+ (1,0) [0|1] ""  HMI
 SG_ P11_PCU_S_CoolerCompressorReadyT : 2|1@0+ (1,0) [0|1] ""  HMI
 SG_ P11_PCU_S_CabinHeaterReadyToWork : 1|1@0+ (1,0) [0|1] ""  HMI
 SG_ P11_PCU_S_BMSReadyToWork : 0|1@0+ (1,0) [0|1] ""  HMI

BO_ 1450 PCU_P10_Proccessor: 8 PCU
 SG_ P10_PCU_D_PedalSupplyChannel2 : 32|8@1+ (0.1,0) [0|7.2] "V"  HMI
 SG_ P10_PCU_D_PedalSupplyChannel1 : 24|8@1+ (0.1,0) [0|7.2] "V"  HMI
 SG_ P10_PCU_D_3V3SupplyVoltage : 40|8@1+ (0.1,0) [0|4.9] "V"  HMI
 SG_ P10_PCU_D_CRC : 63|8@0+ (1,0) [0|255] ""  HMI
 SG_ P10_PCU_D_Counter : 55|8@0+ (1,0) [0|255] ""  HMI
 SG_ P10_PCU_D_5VSupplyVoltage : 16|8@1+ (0.1,0) [0|7.7] "V"  HMI
 SG_ P10_PCU_D_InputVoltage : 8|8@1+ (0.1,0) [0|19.3] "V"  HMI
 SG_ P10_PCU_D_ProcessorTemperature : 0|8@1+ (1,-40) [-40|175] "�C"  HMI

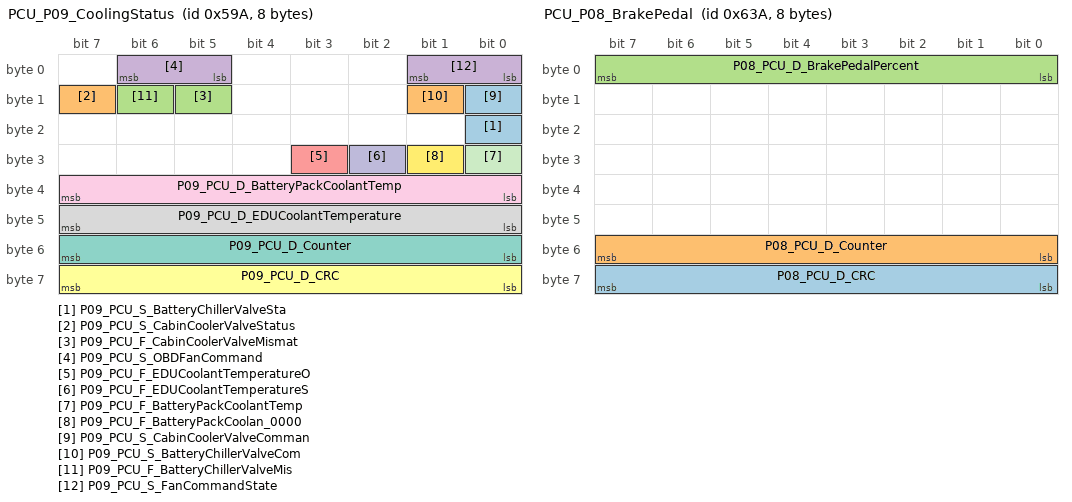
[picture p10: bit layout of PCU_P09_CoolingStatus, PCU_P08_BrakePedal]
BO_ 1434 PCU_P09_CoolingStatus: 8 PCU
 SG_ P09_PCU_S_BatteryChillerValveSta : 16|1@0+ (1,0) [0|1] "" Vector__XXX
 SG_ P09_PCU_S_CabinCoolerValveStatus : 15|1@0+ (1,0) [0|1] "" Vector__XXX
 SG_ P09_PCU_F_CabinCoolerValveMismat : 13|1@0+ (1,0) [0|1] "" Vector__XXX
 SG_ P09_PCU_S_OBDFanCommand : 6|2@0+ (1,0) [0|3] "" Vector__XXX
 SG_ P09_PCU_F_EDUCoolantTemperatureO : 27|1@0+ (1,0) [0|1] ""  HMI
 SG_ P09_PCU_D_CRC : 63|8@0+ (1,0) [0|255] ""  HMI
 SG_ P09_PCU_D_Counter : 55|8@0+ (1,0) [0|255] ""  HMI
 SG_ P09_PCU_D_EDUCoolantTemperature : 40|8@1+ (1,-40) [-11|110] "�C"  HMI
 SG_ P09_PCU_D_BatteryPackCoolantTemp : 32|8@1+ (1,-40) [-28|85] "�C"  HMI
 SG_ P09_PCU_F_EDUCoolantTemperatureS : 26|1@0+ (1,0) [0|1] ""  HMI
 SG_ P09_PCU_F_BatteryPackCoolantTemp : 24|1@0+ (1,0) [0|1] ""  HMI
 SG_ P09_PCU_F_BatteryPackCoolan_0000 : 25|1@0+ (1,0) [0|1] ""  HMI
 SG_ P09_PCU_S_CabinCoolerValveComman : 8|1@0+ (1,0) [0|1] ""  HMI
 SG_ P09_PCU_S_BatteryChillerValveCom : 9|1@0+ (1,0) [0|1] ""  HMI
 SG_ P09_PCU_F_BatteryChillerValveMis : 14|1@0+ (1,0) [0|1] ""  HMI
 SG_ P09_PCU_S_FanCommandState : 1|2@0+ (1,0) [0|3] ""  HMI

BO_ 1594 PCU_P08_BrakePedal: 8 PCU
 SG_ P08_PCU_D_CRC : 63|8@0+ (1,0) [0|255] ""  HMI
 SG_ P08_PCU_D_Counter : 55|8@0+ (1,0) [0|255] ""  HMI
 SG_ P08_PCU_D_BrakePedalPercent : 0|8@1+ (1,0) [0|100] "%"  HMI

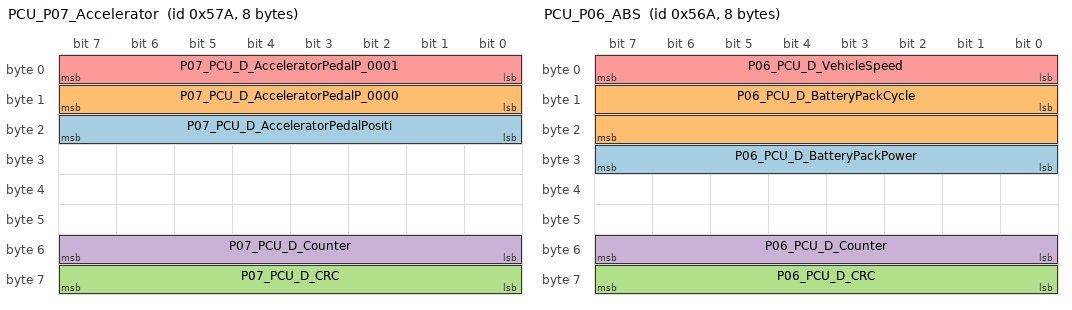
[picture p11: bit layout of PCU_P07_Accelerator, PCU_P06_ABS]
BO_ 1402 PCU_P07_Accelerator: 8 PCU
 SG_ P07_PCU_D_AcceleratorPedalPositi : 16|8@1+ (1,0) [0|100] "%"  HMI
 SG_ P07_PCU_D_AcceleratorPedalP_0000 : 8|8@1+ (1,0) [0|100] "%"  HMI
 SG_ P07_PCU_D_CRC : 63|8@0+ (1,0) [0|255] ""  HMI
 SG_ P07_PCU_D_Counter : 55|8@0+ (1,0) [0|255] ""  HMI
 SG_ P07_PCU_D_AcceleratorPedalP_0001 : 0|8@1+ (1,0) [0|100] "%"  HMI

BO_ 1386 PCU_P06_ABS: 8 PCU
 SG_ P06_PCU_D_BatteryPackPower : 24|8@1+ (1,-100) [-40|153] "kW" Vector__XXX
 SG_ P06_PCU_D_BatteryPackCycle : 8|16@1+ (1,0) [0|65533] "cycles" Vector__XXX
 SG_ P06_PCU_D_CRC : 63|8@0+ (1,0) [0|255] ""  HMI
 SG_ P06_PCU_D_Counter : 55|8@0+ (1,0) [0|255] ""  HMI
 SG_ P06_PCU_D_VehicleSpeed : 0|8@1+ (1,0) [0|253] "km/h"  HMI

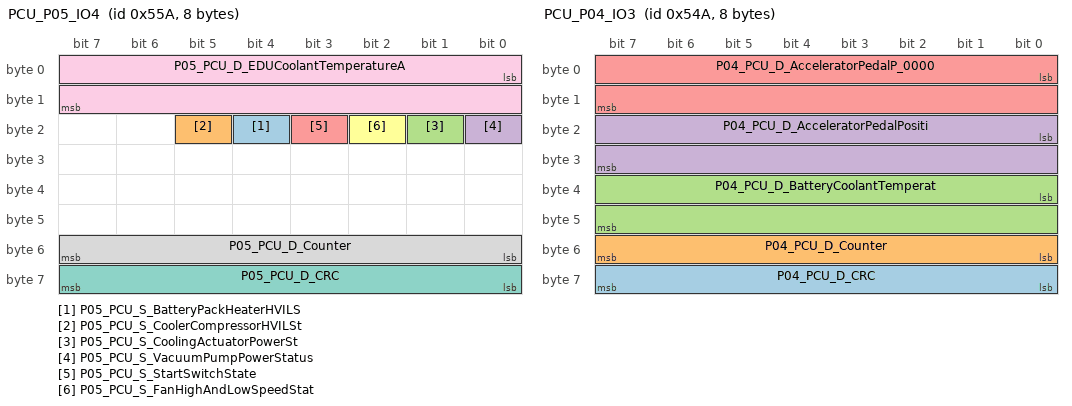
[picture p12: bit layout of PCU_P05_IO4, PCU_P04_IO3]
BO_ 1370 PCU_P05_IO4: 8 PCU
 SG_ P05_PCU_S_BatteryPackHeaterHVILS : 20|1@1+ (1,0) [0|1] ""  HMI
 SG_ P05_PCU_S_CoolerCompressorHVILSt : 21|1@1+ (1,0) [0|1] ""  HMI
 SG_ P05_PCU_S_CoolingActuatorPowerSt : 17|1@1+ (1,0) [0|1] ""  HMI
 SG_ P05_PCU_S_VacuumPumpPowerStatus : 16|1@1+ (1,0) [0|1] ""  HMI
 SG_ P05_PCU_S_StartSwitchState : 19|1@1+ (1,0) [0|1] ""  HMI
 SG_ P05_PCU_S_FanHighAndLowSpeedStat : 18|1@1+ (1,0) [0|1] ""  HMI
 SG_ P05_PCU_D_CRC : 63|8@0+ (1,0) [0|255] ""  HMI
 SG_ P05_PCU_D_Counter : 55|8@0+ (1,0) [0|255] ""  HMI
 SG_ P05_PCU_D_EDUCoolantTemperatureA : 0|16@1+ (1,0) [0|4095] ""  HMI

BO_ 1354 PCU_P04_IO3: 8 PCU
 SG_ P04_PCU_D_CRC : 63|8@0+ (1,0) [0|255] ""  HMI
 SG_ P04_PCU_D_Counter : 55|8@0+ (1,0) [0|255] ""  HMI
 SG_ P04_PCU_D_BatteryCoolantTemperat : 32|16@1+ (1,0) [0|4095] ""  HMI
 SG_ P04_PCU_D_AcceleratorPedalPositi : 16|16@1+ (1,0) [0|4095] ""  HMI
 SG_ P04_PCU_D_AcceleratorPedalP_0000 : 0|16@1+ (1,0) [0|4095] ""  HMI

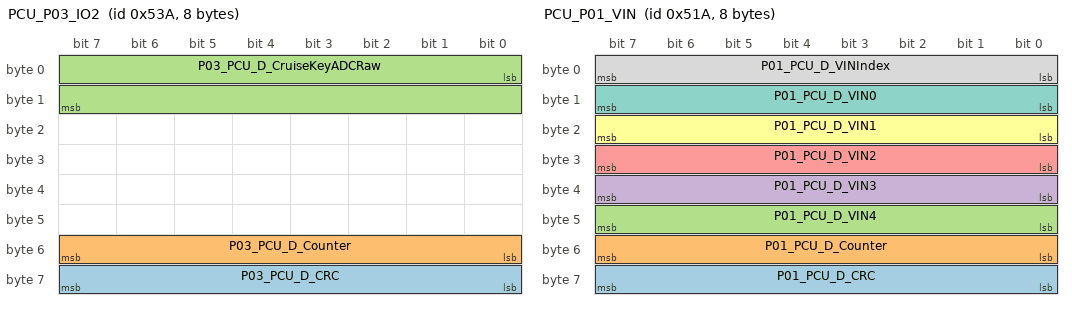
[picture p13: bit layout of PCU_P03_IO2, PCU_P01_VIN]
BO_ 1338 PCU_P03_IO2: 8 PCU
 SG_ P03_PCU_D_CRC : 63|8@0+ (1,0) [0|255] ""  HMI
 SG_ P03_PCU_D_Counter : 55|8@0+ (1,0) [0|255] ""  HMI
 SG_ P03_PCU_D_CruiseKeyADCRaw : 0|16@1+ (1,0) [0|4095] ""  HMI

BO_ 1322 PCU_P02_IO1: 8 PCU
 SG_ P02_PCU_S_PressureSwitchFanHighS : 31|1@0+ (1,0) [0|1] ""  HMI
 SG_ P02_PCU_S_VehiclePowerUpRelaySta : 30|1@0+ (1,0) [0|1] ""  HMI
 SG_ P02_PCU_D_CRC : 63|8@0+ (1,0) [0|255] ""  HMI
 SG_ P02_PCU_D_Counter : 55|8@0+ (1,0) [0|255] ""  HMI
 SG_ P02_PCU_D_AirConditionerTemperat : 32|16@1+ (1,0) [0|4095] ""  HMI
 SG_ P02_PCU_S_VacuumPumpPWMState : 17|1@0+ (1,0) [0|1] ""  HMI
 SG_ P02_PCU_S_BlowerFanSelectorState : 18|1@0+ (1,0) [0|1] ""  HMI
 SG_ P02_PCU_S_FastChargeRelayStatus : 19|1@0+ (1,0) [0|1] ""  HMI
 SG_ P02_PCU_S_ESCKeyState : 20|1@0+ (1,0) [0|1] ""  HMI
 SG_ P02_PCU_S_BrakeMicroSwitchState : 21|1@0+ (1,0) [0|1] ""  HMI
 SG_ P02_PCU_S_BrakeStopPedalState : 22|1@0+ (1,0) [0|1] ""  HMI
 SG_ P02_PCU_S_ACCState : 23|1@0+ (1,0) [0|1] ""  HMI
 SG_ P02_PCU_S_IgnitionState : 24|1@0+ (1,0) [0|1] ""  HMI
 SG_ P02_PCU_S_OBCPlugState : 25|1@0+ (1,0) [0|1] ""  HMI
 SG_ P02_PCU_S_CabinCoolerValveStatus : 26|1@0+ (1,0) [0|1] ""  HMI
 SG_ P02_PCU_S_BatteryChillerValveSta : 27|1@0+ (1,0) [0|1] ""  HMI
 SG_ P02_PCU_S_PressureSwitchState : 28|1@0+ (1,0) [0|1] ""  HMI
 SG_ P02_PCU_S_AirConditionerKeyState : 16|1@0+ (1,0) [0|1] ""  HMI
 SG_ P02_PCU_S_BatteryPackSlowChargeW : 15|1@0+ (1,0) [0|1] ""  HMI
 SG_ P02_PCU_S_BatteryPackQuickCharge : 14|1@0+ (1,0) [0|1] ""  HMI
 SG_ P02_PCU_S_BatteryPackKeyOnStatus : 13|1@0+ (1,0) [0|1] ""  HMI
 SG_ P02_PCU_S_ReverseLightCommand : 12|1@0+ (1,0) [0|1] ""  HMI
 SG_ P02_PCU_S_BatteryChillerValveCom : 11|1@0+ (1,0) [0|1] ""  HMI
 SG_ P02_PCU_S_BlowerFanRelayPowerCom : 10|1@0+ (1,0) [0|1] ""  HMI
 SG_ P02_PCU_S_FanHighSpeedRelayComma : 9|1@0+ (1,0) [0|1] ""  HMI
 SG_ P02_PCU_S_HMIPowerCommand : 8|1@0+ (1,0) [0|1] ""  HMI
 SG_ P02_PCU_S_CabinCoolerValvePowerC : 7|1@0+ (1,0) [0|1] ""  HMI
 SG_ P02_PCU_S_EDUPumpCommand : 6|1@0+ (1,0) [0|1] ""  HMI
 SG_ P02_PCU_S_BatteryPackWaterPumpPo : 5|1@0+ (1,0) [0|1] ""  HMI
 SG_ P02_PCU_S_VacuumPumpCommand : 4|1@0+ (1,0) [0|1] ""  HMI
 SG_ P02_PCU_S_FanLowSpeedRelayComman : 3|1@0+ (1,0) [0|1] ""  HMI
 SG_ P02_PCU_S_KL15DCDCCommand : 2|1@0+ (1,0) [0|1] ""  HMI
 SG_ P02_PCU_S_KL15FastChargeCommand : 1|1@0+ (1,0) [0|1] ""  HMI
 SG_ P02_PCU_S_KL15MCUCommand : 0|1@0+ (1,0) [0|1] ""  HMI

BO_ 1306 PCU_P01_VIN: 8 PCU
 SG_ P01_PCU_D_CRC : 63|8@0+ (1,0) [0|255] ""  HMI
 SG_ P01_PCU_D_Counter : 55|8@0+ (1,0) [0|255] ""  HMI
 SG_ P01_PCU_D_VIN4 : 47|8@0+ (1,0) [0|255] ""  HMI
 SG_ P01_PCU_D_VIN3 : 39|8@0+ (1,0) [0|255] ""  HMI
 SG_ P01_PCU_D_VIN2 : 31|8@0+ (1,0) [0|255] ""  HMI
 SG_ P01_PCU_D_VIN1 : 23|8@0+ (1,0) [0|255] ""  HMI
 SG_ P01_PCU_D_VIN0 : 15|8@0+ (1,0) [0|255] ""  HMI
 SG_ P01_PCU_D_VINIndex : 7|8@0+ (1,0) [0|255] ""  HMI

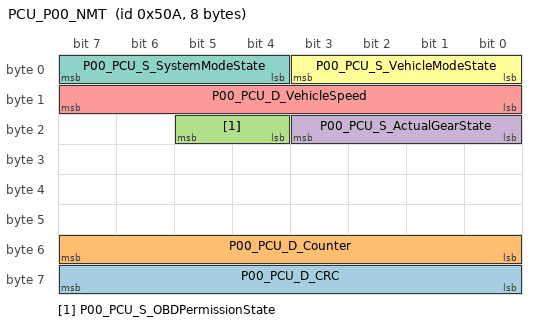
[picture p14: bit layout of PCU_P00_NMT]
BO_ 1290 PCU_P00_NMT: 8 PCU
 SG_ P00_PCU_D_CRC : 63|8@0+ (1,0) [0|255] ""  HMI
 SG_ P00_PCU_D_Counter : 55|8@0+ (1,0) [0|255] ""  HMI
 SG_ P00_PCU_S_OBDPermissionState : 21|2@0+ (1,0) [0|3] ""  HMI
 SG_ P00_PCU_S_ActualGearState : 19|4@0+ (1,0) [0|15] ""  HMI
 SG_ P00_PCU_D_VehicleSpeed : 15|8@0+ (1,0) [0|253] "km/h"  HMI
 SG_ P00_PCU_S_VehicleModeState : 3|4@0+ (1,0) [0|5] ""  HMI
 SG_ P00_PCU_S_SystemModeState : 7|4@0+ (1,0) [0|9] ""  HMI

CM_ SG_ 1802 P35_PCU_S_VacuumPumpDisableState "Vacuum pump disable state (input to motion module)";
CM_ SG_ 1802 P35_PCU_S_TCSDisableState "Traction Control System (TCS) disable state (input to motion module)";
CM_ SG_ 1802 P35_PCU_S_SpeedLimit80kmState "Speed limit state (80 km/h) (input to motion module)";
CM_ SG_ 1802 P35_PCU_S_SpeedLimit40kmState "Speed limit state (40 km/h) (input to motion module)";
CM_ SG_ 1802 P35_PCU_S_SpeedLimit120kmState "Speed limit state (120 km/h) (input to motion module)";
CM_ SG_ 1802 P35_PCU_S_SpeedLimit0kmState "Speed limit state (0 km/h) (input to motion module)";
CM_ SG_ 1802 P35_PCU_S_RetardDisableState "Retard disable state (input to motion module)";
CM_ SG_ 1802 P35_PCU_S_DriveBodyPermissionSta "Drive permission with body fault state (input to motion module)";
CM_ SG_ 1802 P35_PCU_S_CruiseDisableState "Cruise disable state (input to motion module)";
CM_ SG_ 1802 P35_PCU_S_CreepDisableState "Creep disable state (input to motion module)";
CM_ SG_ 1802 P35_PCU_D_RetardTorqueSetpointPe "Retard torque set point percent (input to motion module)";
CM_ SG_ 1770 P34_PCU_S_PowerSavingState "Power saving state";
CM_ SG_ 1770 P34_PCU_S_FlasherEnableState "Flasher enable state";
CM_ SG_ 1770 P34_PCU_S_DCDCEnableStatus "DCDC enable status";
CM_ SG_ 1770 P34_PCU_S_BrakeLightState "Brake light state";
CM_ SG_ 1082 P33_PCU_S_DCLState "Discharge current limit (DCL) state";
CM_ SG_ 1082 P33_PCU_S_CCLState "Charge current limit (CCL) state";
CM_ SG_ 1082 P33_PCU_S_BatteryTempUniformityS "Battery temperature uniformity state";
CM_ SG_ 1082 P33_PCU_D_CRC "8 bit CRC";
CM_ SG_ 1082 P33_PCU_D_Counter "8 bit up counter";
CM_ SG_ 1082 P33_PCU_S_CompressorDeceleration "Compressor deceleration request state";
CM_ SG_ 1082 P33_PCU_D_AdaptiveBatteryPackCoo "Adaptive battery pack coolant warm threshold temperature";
CM_ SG_ 1066 P31_PCU_D_CruiseSpeedSetpoint "Cruise speed set point used in control system";
CM_ SG_ 1066 P31_PCU_S_CruiseState "Cruise state";
CM_ SG_ 1066 P31_PCU_D_CRC8 "CRC8";
CM_ SG_ 1066 P31_PCU_D_Counter "8 bit up counter";
CM_ SG_ 1066 P31_PCU_D_TCSTorqueSetpoint "Traction Control System (TCS) torque set point for Motor Control Unit (MCU)";
CM_ SG_ 1066 P31_PCU_D_TASMCUTorqueSetpoint "Torque Allocation System (TAS) torque set point for Motor Control Unit (MCU)";
CM_ SG_ 1050 P30_PCU_D_CRC "8 bit CRC";
CM_ SG_ 1050 P30_PCU_D_Counter "8 bit up counter";
CM_ SG_ 1050 P30_PCU_D_RetardTorqueSetpoint "Retard torque set point";
CM_ SG_ 1050 P30_PCU_D_RegenTorqueSetpoint "Regenerative braking torque set point";
CM_ SG_ 1050 P30_PCU_D_CruiseTorqueSetpoint "Cruise torque set point";
CM_ SG_ 1034 P29_PCU_S_CruiseButtonOnState "Cruise on button state";
CM_ SG_ 1034 P29_PCU_S_CruiseButtonOffState "Cruise off button state";
CM_ SG_ 1034 P29_PCU_S_CruiseButtonIncreaseSt "Cruise speed increase button state";
CM_ SG_ 1034 P29_PCU_S_CruiseButtonDecreaseSt "Cruise speed decrease button state";
CM_ SG_ 1034 P29_PCU_D_CRC "8 bit CRC";
CM_ SG_ 1034 P29_PCU_D_Counter "8 bit up counter";
CM_ SG_ 1034 P29_PCU_D_CreepTorqueSetpoint "Creep torque set point";
CM_ SG_ 1034 P29_PCU_D_AcceleratorTorqueSetpo "Calculated torque set point";
CM_ SG_ 1034 P29_PCU_S_HillHoldActiveState "Hillhold activation state";
CM_ SG_ 1034 P29_PCU_S_RetardActiveState "Retard activation state";
CM_ SG_ 1034 P29_PCU_S_CruiseActiveState "Cruise activation state";
CM_ SG_ 1034 P29_PCU_S_CreepModeActiveState "Creep mode activation state";
CM_ SG_ 1034 P29_PCU_S_AcceleratorModeActiveS "Accelerator mode activation state";
CM_ SG_ 1034 P29_PCU_S_TCSActiveState "Traction Control System (TCS) activation state";
CM_ SG_ 1578 P32_PCU_F_EEPROMCellCycleTimeout "EEPROM timeout fault";
CM_ SG_ 1578 P32_PCU_F_EEPROMMCUIDTimeoutFaul "EEPROM timeout fault";
CM_ SG_ 1578 P32_PCU_F_DOLFault "Digital output low side (DOL) fault";
CM_ SG_ 1578 P32_PCU_F_FanLowSpeedAbnormalFau "Low speed cooling fan operation fault";
CM_ SG_ 1578 P32_PCU_F_FanHighSpeedAbnormalFa "High speed cooling fan operation fault";
CM_ SG_ 1578 P32_PCU_F_CabinCoolerValveOpenWi "Cabin cooler valve open wire fault";
CM_ SG_ 1578 P32_PCU_F_BatteryChillerValveOpe "Battery chiller valve open wire fault";
CM_ SG_ 1578 P32_PCU_F_FanHighSpeedAbnormalPr "High speed cooling fan operation fault (pressure switch triggered)";
CM_ SG_ 1578 P32_PCU_F_PressureSwitchAbnormal "Pressure switch abnormal fault";
CM_ SG_ 1578 P32_PCU_F_PressureSwitchHardware "Pressure switch hardware fault";
CM_ SG_ 1578 P32_PCU_F_CabinCoolerValveShortC "Cabin cooler valve short circuit fault";
CM_ SG_ 1578 P32_PCU_F_BatteryChillerValveSho "Battery chiller valve short circuit fault";
CM_ SG_ 1578 P32_PCU_F_FlashTimeoutFault "Flash timeout fault";
CM_ SG_ 1578 P32_PCU_F_EEPROMODOTimeoutFault "EEPROM timeout fault";
CM_ SG_ 1578 P32_PCU_F_CANFDTxFIFOFullFault "CAN FD Tx FIFO full fault";
CM_ SG_ 1578 P32_PCU_F_CANFDTxBusOffFault "CAN FD bus off fault";
CM_ SG_ 1578 P32_PCU_F_CANFDTxBusPassiveFault "CAN FD Tx passive fault";
CM_ SG_ 1578 P32_PCU_F_CANFDRxBusPassiveFault "CAN FD Rx passive fault";
CM_ SG_ 1578 P32_PCU_F_DiSpiTemperatureShutDo "Digital Input (DI) SPI temperature shut down fault";
CM_ SG_ 1578 P32_PCU_F_DiSpiCheckFault "Digital Input (DI) SPI check fault";
CM_ SG_ 1578 P32_PCU_F_DiSpiTemperatureWarnin "Digital Input (DI) SPI over temperature warning";
CM_ SG_ 1578 P32_PCU_F_DiSpiOverVoltageFault "Digital Input (DI) SPI over voltage fault";
CM_ SG_ 1578 P32_PCU_F_DiSpiUnderVoltageFault "Digital Input (DI) SPI under voltage fault";
CM_ SG_ 1578 P32_PCU_F_DiSpiParityFault "Digital Input (DI) SPI parity fault";
CM_ SG_ 1578 P32_PCU_F_DiSpiFault "Digital Input (DI) SPI sends data fault";
CM_ SG_ 1578 P32_PCU_D_Counter "8 bit up counter";
CM_ SG_ 1578 P32_PCU_D_CRC "8 bit CRC";
CM_ SG_ 1514 P26_PCU_S_RegenState "Regenerative braking state";
CM_ SG_ 1514 P26_PCU_S_RegenSOCDerateState "Regenerative brake derating state (due to SOC limitation)";
CM_ SG_ 1514 P26_PCU_S_RegenMotorDerateState "Regenerative brake derating state (due to motor limitation)";
CM_ SG_ 1514 P26_PCU_S_RegenMCUDerateState "Regenerative brake derating state (due to Motor Control Unit (MCU) limitation)";
CM_ SG_ 1514 P26_PCU_S_RegenBatteryDerateStat "Regenerative brake derating state (due to battery pack limitation)";
CM_ SG_ 1514 P26_PCU_S_HillholdPermissionStat "Hillhold permission state";
CM_ SG_ 1514 P26_PCU_D_ESCTorqueLimit "Electronic Stability Control (ESC) torque limit";
CM_ SG_ 1514 P26_PCU_S_ESCTorqueLimitActiveSt "Electronic Stability Control (ESC) torque limit activation state";
CM_ SG_ 1514 P26_PCU_S_DriveProcessorTempDera "Driving torque derating state (due to processor temperature limitation)";
CM_ SG_ 1514 P26_PCU_S_DriveMotorDerateState "Driving torque derating state (due to motor limitation)";
CM_ SG_ 1514 P26_PCU_S_DriveMCUDerateState "Driving torque derating state (due to Motor Control Unit (MCU) limitation)";
CM_ SG_ 1514 P26_PCU_S_DriveLVVoltageDerateSt "Driving torque derating state (due to 12V battery limitation)";
CM_ SG_ 1514 P26_PCU_S_DriveBatteryDerateStat "Driving torque derating state (due to battery pack limitation)";
CM_ SG_ 1514 P26_PCU_S_DriveSOCDerateState "Driving torque derating state (due to State of Charge (SOC) limitation)";
CM_ SG_ 1514 P26_PCU_S_TCSPermissionState "Traction Control System (TCS) permission state";
CM_ SG_ 1514 P26_PCU_S_DrivePermissionState "Drive permission state";
CM_ SG_ 1514 P26_PCU_S_CreepPermissionState "Creep permission state";
CM_ SG_ 1514 P26_PCU_S_CruisePermissionState "Cruise control permission state";
CM_ SG_ 1514 P26_PCU_S_RetardPermissionState "Retardation permission state";
CM_ SG_ 1514 P26_PCU_S_DriveDerateState "Driving torque derating state";
CM_ SG_ 1514 P26_PCU_S_RegenDerateState "Regenerative brake derating state";
CM_ SG_ 1514 P26_PCU_D_MotorMaxPower "Motor maximum power";
CM_ SG_ 1514 P26_PCU_D_Counter "8 bit up counter";
CM_ SG_ 1514 P26_PCU_D_CRC "8 bit CRC";
CM_ SG_ 1530 P27_PCU_D_MotorRegenLimitTorque "Motor torque limit in regenerative brake mode";
CM_ SG_ 1530 P27_PCU_D_MotorDriveLimitTorque "Motor Torque limit in drive mode";
CM_ SG_ 1530 P27_PCU_D_MotorDriveMaxTorque "Maximum motor torque in drive mode";
CM_ SG_ 1530 P27_PCU_D_Counter "8 bit up counter";
CM_ SG_ 1530 P27_PCU_D_CRC "8 bit CRC";
CM_ SG_ 1546 P28_PCU_D_MotorRegenMaxTorque "Maximum motor torque in regenerative brake mode";
CM_ SG_ 1546 P28_PCU_D_MotorDriveMinTorque "Minimum motor torque in drive mode";
CM_ SG_ 1546 P28_PCU_D_MotorRegenMinTorque "Minimum motor torque in regenerative brake mode";
CM_ SG_ 1546 P28_PCU_D_Counter "8 bit up counter";
CM_ SG_ 1546 P28_PCU_D_CRC "8 bit CRC";
CM_ SG_ 1194 P20_PCU_S_BatteryPackHeatingRequ "Battery pack heating request state";
CM_ SG_ 1194 P20_PCU_S_BatteryPackCoolantTemp "Battery pack coolant temperature sensor select state";
CM_ SG_ 1194 P20_PCU_S_BatteryPackMinTemperat "Battery pack minimum cell temperature state";
CM_ SG_ 1194 P20_PCU_D_CRC "8 bit CRC";
CM_ SG_ 1194 P20_PCU_D_Counter "8 bit up counter";
CM_ SG_ 1194 P20_PCU_S_BatteryPackTMSModeStat "Battery pack Thermal Management System (TMS) mode state";
CM_ SG_ 1194 P20_PCU_S_BatteryPackCoolan_0000 "Battery pack coolant temperature state";
CM_ SG_ 1194 P20_PCU_S_BatteryPackMaxTemperat "Battery pack maximum cell temperature state";
CM_ SG_ 1178 P19_PCU_S_DrivingModeState "Driving mode state";
CM_ SG_ 1178 P19_PCU_S_OBCTemperatureState "On Board Charger (OBC) temperature state";
CM_ SG_ 1178 P19_PCU_S_EDUDeviceMaximumPumpRe "Electric Drive Unit (EDU) device with maximum pump request";
CM_ SG_ 1178 P19_PCU_S_EDUTMSModeState "Electric Drive Unit (EDU) Thermal Management System (TMS) mode state";
CM_ SG_ 1178 P19_PCU_S_MCUTemperatureState "Motor Control Unit (MCU) temperature state";
CM_ SG_ 1178 P19_PCU_D_CRC "8 bit CRC";
CM_ SG_ 1178 P19_PCU_D_Counter "8 bit up counter";
CM_ SG_ 1162 P18_PCU_S_MotorTemperatureState "Motor temperature state";
CM_ SG_ 1162 P18_PCU_S_DCDCTemperatureState "DC-DC temperature state";
CM_ SG_ 1162 P18_PCU_S_CabinTMSModeState "Cabin Thermal Management System (TMS) mode state";
CM_ SG_ 1162 P18_PCU_D_CRC "8 bit CRC";
CM_ SG_ 1162 P18_PCU_D_Counter "8 bit up counter";
CM_ SG_ 1162 P18_PCU_S_CabinCoolerValveComman "Cabin cooler valve command";
CM_ SG_ 1162 P18_PCU_S_BatteryPackHeaterEnabl "Battery pack heater enable command";
CM_ SG_ 1162 P18_PCU_S_BatteryChillerValveCom "Battery chiller valve command";
CM_ SG_ 1146 P17_PCU_D_EDUWaterPumpSetpoint "Electric Drive Unit (EDU) water pump speed set point";
CM_ SG_ 1146 P17_PCU_S_FanCommandState "Cooling fan command state";
CM_ SG_ 1146 P17_PCU_D_CRC "8 bit CRC";
CM_ SG_ 1146 P17_PCU_D_Counter "8 bit up counter";
CM_ SG_ 1146 P17_PCU_D_CoolerCompressorSpeedS "Cooler compressor speed set point";
CM_ SG_ 1146 P17_PCU_D_CabinHeaterPowerSetpoi "Cabin heater power set point";
CM_ SG_ 1146 P17_PCU_D_BatteryPackWaterPumpSe "Battery pack water pump speed set point";
CM_ SG_ 1146 P17_PCU_D_BatteryPackHeaterTempe "Battery pack heater temperature set point";
CM_ SG_ 1130 P25_PCU_D_CCL "Charge Current Limit (CCL)";
CM_ SG_ 1130 P25_PCU_D_DCL "Discharge Current Limit (DCL)";
CM_ SG_ 1130 P25_PCU_D_CRC "8 bit CRC";
CM_ SG_ 1130 P25_PCU_D_Counter "8 bit up counter";
CM_ SG_ 1130 P25_PCU_D_CoolerCompressorSpeedF "Cooler compressor speed feedback";
CM_ SG_ 1114 P24_PCU_D_AirConditionerRequest "Air condition request level (knob)";
CM_ SG_ 1114 P24_PCU_F_OBCOverTemperatureFaul "On Board Charger (OBC) over temperature fault";
CM_ SG_ 1114 P24_PCU_F_MotorOverTemperatureWa "Motor over temperature warning";
CM_ SG_ 1114 P24_PCU_F_MotorOverTemperatureFa "Motor over temperature fault";
CM_ SG_ 1114 P24_PCU_F_MCUOverTemperatureWarn "Motor Control Unit (MCU) over temperature warning";
CM_ SG_ 1114 P24_PCU_F_MCUOverTemperatureFaul "Motor Control Unit (MCU) over temperature fault";
CM_ SG_ 1114 P24_PCU_F_DCDCOverTemperatureFau "DC-DC over temperature fault";
CM_ SG_ 1114 P24_PCU_F_BMSUnderTemperatureFau "Battery Management System (BMS) under temperature fault";
CM_ SG_ 1114 P24_PCU_F_BMSOverTemperatureFaul "Battery Management System (BMS) over temperature fault";
CM_ SG_ 1114 P24_PCU_D_CRC "8 bit CRC";
CM_ SG_ 1114 P24_PCU_D_Counter "8 bit up counter";
CM_ SG_ 1114 P24_PCU_D_CabinWarmingPercent "Cabin warming request percent level (knob)";
CM_ SG_ 1114 P24_PCU_D_CabinCoolingPercent "Cabin cooling request percent level (knob)";
CM_ SG_ 1114 P24_PCU_S_BlowerFanSelectorState "Blower fan selector state";
CM_ SG_ 1098 P23_PCU_D_DCDCTemperature "DC-DC temperature";
CM_ SG_ 1098 P23_PCU_D_EDUCoolantTemperature "Electric Drive Unit (EDU) coolant temperature";
CM_ SG_ 1098 P23_PCU_D_CRC "8 bit CRC";
CM_ SG_ 1098 P23_PCU_D_Counter "8 bit up counter";
CM_ SG_ 1098 P23_PCU_D_CabinHeaterTemperature "Cabin heater temperature";
CM_ SG_ 1098 P23_PCU_D_BatteryPackCoolantTemp "Battery pack coolant temperature";
CM_ SG_ 1098 P23_PCU_D_BatteryPackHeaterTempe "Battery pack heater temperature";
CM_ SG_ 1498 P22_PCU_D_OBCTemperature "On Board Charger (OBC) temperature";
CM_ SG_ 1498 P22_PCU_D_MotorTemperature "Motor temperature";
CM_ SG_ 1498 P22_PCU_D_MCUTemperature "Motor Control Unit (MCU) temperature";
CM_ SG_ 1498 P22_PCU_D_CRC "8 bit CRC";
CM_ SG_ 1498 P22_PCU_D_Counter "8 bit up counter";
CM_ SG_ 1498 P22_PCU_D_BMSLowestTemperature "Battery Management System (BMS) lowest temperature";
CM_ SG_ 1498 P22_PCU_D_BMSMeanTemperature "Battery Management System (BMS) mean temperature";
CM_ SG_ 1498 P22_PCU_D_BMSHighestTemperature "Battery Management System (BMS) highest temperature";
CM_ SG_ 1482 P21_PCU_S_OBCReadyToWorkState "On Board Charger (OBC) ready to work state";
CM_ SG_ 1482 P21_PCU_S_MotorReadyToWorkState "Motor ready to work state";
CM_ SG_ 1482 P21_PCU_S_EDUWaterPumpReadyToWor "Electric Drive Unit (EDU) water pump ready to work state";
CM_ SG_ 1482 P21_PCU_S_DCDCReadyToWorkState "DC-DC ready to work state";
CM_ SG_ 1482 P21_PCU_S_CoolerCompressorReadyT "Cooler compressor ready to work state";
CM_ SG_ 1482 P21_PCU_S_CabinHeaterReadyToWork "Cabin heater ready to work state";
CM_ SG_ 1482 P21_PCU_S_CabinCoolerValveReadyT "Cabin cooler valve ready to work state";
CM_ SG_ 1482 P21_PCU_S_BatteryPackWaterPumpRe "Battery pack water pump ready to work state";
CM_ SG_ 1482 P21_PCU_S_BMSReadyToWorkState "Battery Management System (BMS) ready to work state";
CM_ SG_ 1482 P21_PCU_S_BatteryPackHeaterReady "Battery pack heater ready to work state";
CM_ SG_ 1482 P21_PCU_S_BatteryChillerValveRea "Battery chiller valve ready to work state";
CM_ SG_ 1482 P21_PCU_S_OBCModeState "On Board Charger (OBC) mode state";
CM_ SG_ 1482 P21_PCU_S_FastChargeModeState "Fast charge mode state";
CM_ SG_ 1482 P21_PCU_D_CRC "8 bit CRC";
CM_ SG_ 1482 P21_PCU_D_Counter "8 bit up counter";
CM_ SG_ 1482 P21_PCU_S_BMSModeState "Battery Management System (BMS) operating mode state";
CM_ SG_ 1274 P16_PCU_F_TMSBatteryPackTemperat "Battery pack temperature sensor fault";
CM_ SG_ 1274 P16_PCU_F_EDUWaterPumpNoLoadingF "Electric Drive Unit (EDU) water pump no loading fault";
CM_ SG_ 1274 P16_PCU_F_BatteryPackWaterPumpNo "Battery pack water pump no loading fault";
CM_ SG_ 1274 P16_PCU_F_TMSCoolingActuatorPowe "Cooling actuator (fan and pump) power fault";
CM_ SG_ 1274 P16_PCU_F_CoolerCompressorHVILFa "Cooler compressor HV Interlock (HVIL) fault";
CM_ SG_ 1274 P16_PCU_F_BatteryPackHeaterHVILF "Battery Pack heater HV Interlock (HVIL) fault";
CM_ SG_ 1274 P16_PCU_F_BothPumpCommunicationF "Both pump communication fault (battery pack and Electric Drive Unit (EDU))";
CM_ SG_ 1274 P16_PCU_F_BatteryPackHeaterOverC "Battery pack heater over current fault";
CM_ SG_ 1274 P16_PCU_F_TMSOBCShutdownFault "On Board Charger (OBC) shutdown due to over temperature fault";
CM_ SG_ 1274 P16_PCU_F_TMSMotorShutdownFault "Motor shutdown due to over temperature fault";
CM_ SG_ 1274 P16_PCU_F_TMSMCUShutdownFault "Motor Control Unit (MCU) shutdown due to over temperature fault";
CM_ SG_ 1274 P16_PCU_F_TMSDCDCShutdownFault "DC-DC shutdown due to over temperature fault";
CM_ SG_ 1274 P16_PCU_F_CoolerCompressorOverCu "Cooler compressor over current fault";
CM_ SG_ 1274 P16_PCU_F_AirConditionerKeyMisma "Air conditioner key mismatch fault (HVAC key panel)";
CM_ SG_ 1274 P16_PCU_F_EDUCoolantTemperatureS "EDU coolant temperature sensor fault (Open or short circuited)";
CM_ SG_ 1274 P16_PCU_F_BatteryPackCoolantTemp "Battery pack coolant temperature sensor fault (Open or short circuited)";
CM_ SG_ 1274 P16_PCU_F_EDUWaterPumpUpdatePara "Electric Drive Unit (EDU) water pump invalid parameter fault";
CM_ SG_ 1274 P16_PCU_F_BatteryPackWaterPumpUp "Battery pack water pump invalid parameter fault";
CM_ SG_ 1274 P16_PCU_F_BatteryPackHeaterHighV "Battery pack heater and battery pack high voltage difference fault";
CM_ SG_ 1274 P16_PCU_F_BatteryPackHeaterPower "Battery pack heater power up Fault";
CM_ SG_ 1274 P16_PCU_F_BatteryPackHeaterShort "Battery pack heater short circuit fault";
CM_ SG_ 1274 P16_PCU_F_CabinHeaterHighVoltage "Cabin heater and battery pack high voltage difference fault";
CM_ SG_ 1274 P16_PCU_F_CabinHeaterPowerUpFaul "Cabin heater power up fault";
CM_ SG_ 1274 P16_PCU_F_CabinHeaterShortCircui "Cabin heater short circuit fault";
CM_ SG_ 1274 P16_PCU_F_CoolerCompressorHighVo "Cooler compressor and battery pack high voltage difference fault";
CM_ SG_ 1274 P16_PCU_F_EDUWaterPumpInternalFa "Electric Drive Unit (EDU) water pump internal fault";
CM_ SG_ 1274 P16_PCU_F_EDUWaterPumpCommunicat "Electric Drive Unit (EDU) water pump communication fault";
CM_ SG_ 1274 P16_PCU_F_CoolerCompressorUpdate "Cooler compressor invalid parameter fault";
CM_ SG_ 1274 P16_PCU_F_CoolerCompressorSpeedF "Cooler compressor speed fault";
CM_ SG_ 1274 P16_PCU_F_CoolerCompressorShortC "Cooler compressor short circuit fault";
CM_ SG_ 1274 P16_PCU_F_CoolerCompressorIntern "Cooler compressor internal fault";
CM_ SG_ 1274 P16_PCU_F_CoolerCompressorCommun "Cooler compressor communication fault";
CM_ SG_ 1274 P16_PCU_F_CabinCoolerValveFault "Cabin cooler valve fault";
CM_ SG_ 1274 P16_PCU_F_BatteryPackWaterPumpIn "Battery pack water pump internal fault";
CM_ SG_ 1274 P16_PCU_F_BatteryPackWaterPumpCo "Battery pack water pump communication fault";
CM_ SG_ 1274 P16_PCU_F_BatteryPackHeaterUpdat "Battery pack heater invalid parameter fault";
CM_ SG_ 1274 P16_PCU_F_BatteryPackHeaterInter "Battery pack heater internal fault";
CM_ SG_ 1274 P16_PCU_F_BatteryPackHeaterCommu "Battery pack heater communication fault";
CM_ SG_ 1274 P16_PCU_F_BatteryChillerValveFau "Battery chiller valve fault";
CM_ SG_ 1274 P16_PCU_F_CabinHeaterUpdateParam "Cabin heater invalid parameter fault";
CM_ SG_ 1274 P16_PCU_F_CabinHeaterInternalFau "Cabin heater internal fault";
CM_ SG_ 1274 P16_PCU_F_CabinHeaterCommunicati "Cabin heater communication fault";
CM_ SG_ 1274 P16_PCU_D_CRC "8 bit CRC";
CM_ SG_ 1274 P16_PCU_D_Counter "8 bit up counter";
CM_ SG_ 1258 P15_PCU_F_AirbagSignalFault "Airbag signal fault (signal invalid)";
CM_ SG_ 1258 P15_PCU_F_AirbagCrashFault "Airbag crash fault (crash detected)";
CM_ SG_ 1258 P15_PCU_F_HMICommunicationFault "Human Machine Interface (HMI) communication fault";
CM_ SG_ 1258 P15_PCU_D_CRC "8 bit CRC";
CM_ SG_ 1258 P15_PCU_D_Counter "8 bit up counter";
CM_ SG_ 1242 P14_PCU_F_PCUCANTimeoutFault "Proportional Control Unit (PCU) CAN timeout fault (CAN bus disabled)";
CM_ SG_ 1242 P14_PCU_F_EVSOCSlowOverLimitFaul "State Of Charge (SOC) over limit fault (slow charge) (don�t charge vehicle)";
CM_ SG_ 1242 P14_PCU_F_EVSOCFastOverLimitFaul "State Of Charge (SOC) over limit fault (fast charge) (don�t charge vehicle)";
CM_ SG_ 1242 P14_PCU_F_EVPluggingFault "Charge plug fault (don�t  power up vehicle)";
CM_ SG_ 1242 P14_PCU_F_EVHVOpenFault "High voltage open fault (don�t  power up vehicle)";
CM_ SG_ 1242 P14_PCU_F_MCUVINMismatchFault "Motor Control Unit (MCU) VIN mismatch fault";
CM_ SG_ 1242 P14_PCU_F_EVAirbagCrashDetectedF "Airbag crash detected fault (the car is powered off)";
CM_ SG_ 1242 P14_PCU_F_EVInPluggedFault "Charge plug fault (don�t  power up vehicle)";
CM_ SG_ 1242 P14_PCU_F_ProcessorMissingClockD "Propulsion Control Unit (PCU) processor Missing Clock Detection (MCD) fault";
CM_ SG_ 1242 P14_PCU_F_ProcessorOverTemperatu "Propulsion Control Unit (PCU) processor over temperature fault";
CM_ SG_ 1242 P14_PCU_F_5VSupplyUnderVoltageFa "5V supply under voltage fault";
CM_ SG_ 1242 P14_PCU_F_5VSupplyOverVoltageFau "5V supply over voltage fault";
CM_ SG_ 1242 P14_PCU_F_InputUnderVoltageFault "Input battery 12V under voltage fault";
CM_ SG_ 1242 P14_PCU_F_InputOverVoltageFault "Input battery 12V over voltage fault";
CM_ SG_ 1242 P14_PCU_F_EVStartSwitchFault "Start switch fault (don�t  power up vehicle)";
CM_ SG_ 1242 P14_PCU_F_EVSOCLowFault "State Of Charge (SOC) min fault (under 2%) (don�t  power up vehicle)";
CM_ SG_ 1242 P14_PCU_F_EVSOCLimitFault "State Of Charge (SOC) exceeds set value fault (don�t charge vehicle)";
CM_ SG_ 1242 P14_PCU_F_EVPrechargeTimeoutFaul "Precharge timeout fault (don�t  power up vehicle)";
CM_ SG_ 1242 P14_PCU_F_EVDCUNotReadyFault "Differential Control Unit (DCU) not ready fault (don�t  power up vehicle)";
CM_ SG_ 1242 P14_PCU_F_EVDCDCNotReadyFault "DC-DC not ready fault (don�t  power up vehicle)";
CM_ SG_ 1242 P14_PCU_F_EVBMSOpenContactorFaul "Battery Management System (BMS) contactor fault";
CM_ SG_ 1242 P14_PCU_F_EVChargeStopFault "Charge stop fault (charging stopped)";
CM_ SG_ 1242 P14_PCU_F_EVBMSNotReadyFault "Battery Management System (BMS) not ready fault (don�t  power up vehicle)";
CM_ SG_ 1242 P14_PCU_D_CRC "8 bit CRC";
CM_ SG_ 1242 P14_PCU_D_Counter "8 bit up counter";
CM_ SG_ 1226 P13_PCU_F_OBCOverCurrentFault "On Board Charger (OBC) over current fault";
CM_ SG_ 1226 P13_PCU_F_BMSModeFault "Propulsion Control Unit (PCU) mode command not executed by Battery Management System (BMS)";
CM_ SG_ 1226 P13_PCU_F_OBCHighVoltageFault "On Board Charger (OBC) output and battery pack high voltage difference fault";
CM_ SG_ 1226 P13_PCU_F_OBCShortCircuitFault "On Board Charger (OBC) short circuit fault";
CM_ SG_ 1226 P13_PCU_F_MCUHighVoltageFault "Motor Control Unit (MCU) and battery pack high voltage difference fault";
CM_ SG_ 1226 P13_PCU_F_OBCUpdateParameterFaul "On Board Charger (OBC) invalid parameter fault";
CM_ SG_ 1226 P13_PCU_F_OBCInternalFault "On Board Charger (OBC) internal fault";
CM_ SG_ 1226 P13_PCU_F_OBCCommunicationFault "On Board Charger (OBC) communication fault";
CM_ SG_ 1226 P13_PCU_F_MCUUpdateParameterFaul "Motor Control Unit (MCU) invalid parameter fault";
CM_ SG_ 1226 P13_PCU_F_MCUInternalFault "Motor Control Unit (MCU) internal fault";
CM_ SG_ 1226 P13_PCU_F_MCUCommunicationFault "Motor Control Unit (MCU) communication fault";
CM_ SG_ 1226 P13_PCU_F_DCDCUpdateParameterFau "DC-DC invalid parameter fault";
CM_ SG_ 1226 P13_PCU_F_DCDCOverTemperatureFau "DC-DC over temperature fault";
CM_ SG_ 1226 P13_PCU_F_DCDCLVUnderVoltageFaul "DC-DC output under voltage fault";
CM_ SG_ 1226 P13_PCU_F_DCDCInternalFault "DC-DC Internal fault";
CM_ SG_ 1226 P13_PCU_F_DCDCHighVoltageFault "DC-DC and battery pack high voltage difference fault";
CM_ SG_ 1226 P13_PCU_F_DCDCCommunicationFault "DC-DC communication fault";
CM_ SG_ 1226 P13_PCU_F_BMSUpdateParameterFaul "Battery Management System (BMS) invalid Parameter fault";
CM_ SG_ 1226 P13_PCU_F_BMSInternalFault "Battery Management System (BMS) internal fault";
CM_ SG_ 1226 P13_PCU_F_BMSCommunicationFault "Battery Management System (BMS) communication fault";
CM_ SG_ 1226 P13_PCU_D_CRC "8 bit CRC";
CM_ SG_ 1226 P13_PCU_D_Counter "Counter";
CM_ SG_ 1226 P13_PCU_F_NegativeContactorWeldi "Battery pack negative contactor welding fault";
CM_ SG_ 1226 P13_PCU_F_NegativeContactorMatch "Battery pack negative contactor command-status mismatch fault";
CM_ SG_ 1226 P13_PCU_F_PositiveContactorWeldi "Battery pack positive contactor welding fault";
CM_ SG_ 1226 P13_PCU_F_PositiveContactorMatch "Battery pack positive contactor command-status mismatch fault";
CM_ SG_ 1226 P13_PCU_F_PrechargeContactorWeld "Battery pack precharge contactor welding fault";
CM_ SG_ 1226 P13_PCU_F_PrechargeContactorMatc "Battery pack precharge contactor command-status mismatch fault";
CM_ SG_ 1210 P12_PCU_F_VacuumPumpPowerFault "Vacuum pump power relay fault";
CM_ SG_ 1210 P12_PCU_F_EPSInternalFault "Electric Power Steering (EPS) Internal fault";
CM_ SG_ 1210 P12_PCU_F_BrakePressureInvalidFa "Brake pressure invalid fault";
CM_ SG_ 1210 P12_PCU_F_AcceleratorPedalPositi "Accelerator pedal position both channels fault (Max, Min, short circuit or mismatch)";
CM_ SG_ 1210 P12_PCU_F_ESCCommunicationFault "Electronic Stability Control (ESC) communication fault";
CM_ SG_ 1210 P12_PCU_F_EPSCommunicationFault "Electric Power Steering (EPS) communication fault";
CM_ SG_ 1210 P12_PCU_F_BrakeStopLightFault "Brake stop light operation fault";
CM_ SG_ 1210 P12_PCU_F_SASUpdateParameterFaul "Steering Angle Sensor (SAS) invalid Parameter fault";
CM_ SG_ 1210 P12_PCU_F_SASInternalFault "Steering Angle Sensor (SAS) internal fault";
CM_ SG_ 1210 P12_PCU_F_SASCommunicationFault "Steering Angle Sensor (SAS) communication fault";
CM_ SG_ 1210 P12_PCU_F_CruiseKeyOpenWireFault "Cruise key open wire fault";
CM_ SG_ 1210 P12_PCU_F_ABSRearRightSpeedFault "Anti lock Braking System (ABS) rear right wheel speed fault";
CM_ SG_ 1210 P12_PCU_F_ABSRearLeftSpeedFault "Anti lock Braking System (ABS) rear left wheel speed fault";
CM_ SG_ 1210 P12_PCU_F_ABSFrontRightSpeedFaul "Anti lock Braking System (ABS) front right wheel speed fault";
CM_ SG_ 1210 P12_PCU_F_ABSFrontLeftSpeedFault "Anti lock Braking System (ABS) front left wheel speed fault";
CM_ SG_ 1210 P12_PCU_F_ABSCommunicationFault "Anti lock Braking System (ABS) communication fault";
CM_ SG_ 1210 P12_PCU_F_BrakePedalMicroSwitchF "Brake pedal micro switch fault";
CM_ SG_ 1210 P12_PCU_F_AcceleratorPedalP_0000 "Accelerator pedal position supply (VCC2) out of range";
CM_ SG_ 1210 P12_PCU_F_AcceleratorPedalP_0001 "Accelerator pedal position supply (VCC1) out of range";
CM_ SG_ 1210 P12_PCU_F_AcceleratorPedalP_0002 "Accelerator pedal position channel 1 and channel 2 shorted together fault";
CM_ SG_ 1210 P12_PCU_F_AcceleratorPedalP_0003 "Accelerator pedal position channel 2 over range fault";
CM_ SG_ 1210 P12_PCU_F_AcceleratorPedalP_0004 "Accelerator pedal position channel 1 over range fault";
CM_ SG_ 1210 P12_PCU_F_VacuumPumpSensorMalfun "Vacuum pump sensor malfunction fault";
CM_ SG_ 1210 P12_PCU_F_VacuumPumpCurrentAbnor "Vacuum pump current abnormal fault";
CM_ SG_ 1210 P12_PCU_F_VacuumPumpPowerAbnorma "Vacuum pump power supply abnormal fault";
CM_ SG_ 1210 P12_PCU_F_VacuumPumpMajorFault "Vacuum pump major fault";
CM_ SG_ 1210 P12_PCU_F_AcceleratorPedalP_0005 "Accelerator pedal position channel 1 and channel 2 mismatch fault";
CM_ SG_ 1210 P12_PCU_F_AcceleratorPedalP_0006 "Accelerator pedal position channel 2 under range fault";
CM_ SG_ 1210 P12_PCU_F_AcceleratorPedalP_0007 "Accelerator pedal position channel 1 under range fault";
CM_ SG_ 1210 P12_PCU_F_NDRUpdateParameterFaul "NDR invalid Parameter fault";
CM_ SG_ 1210 P12_PCU_F_NDRInternalFault "NDR internal fault";
CM_ SG_ 1210 P12_PCU_F_NDRCommunicationFault "NDR communication fault";
CM_ SG_ 1210 P12_PCU_D_CRC "8 bit CRC";
CM_ SG_ 1210 P12_PCU_D_Counter "8 bit up counter";
CM_ BO_ 1466 "ready To Work";
CM_ SG_ 1466 P11_PCU_S_BrakePedalReadyToWork "Brake pedal ready to work";
CM_ SG_ 1466 P11_PCU_S_AcceleratorPedalPositi "Accelerator pedal position channel 2 ready to work";
CM_ SG_ 1466 P11_PCU_S_AcceleratorPedalP_0000 "Accelerator pedal position channel 1 ready to work";
CM_ SG_ 1466 P11_PCU_S_VehicleReadyState "Vehicle ready state";
CM_ SG_ 1466 P11_PCU_D_CRC "8 bit CRC";
CM_ SG_ 1466 P11_PCU_D_Counter "8 bit up counter";
CM_ SG_ 1466 P11_PCU_S_EDUWaterPumpReadyToWor "Electric Drive Unit (EDU) pump ready to work";
CM_ SG_ 1466 P11_PCU_S_BatteryPackWaterPumpRe "Battery pack water pump ready to work";
CM_ SG_ 1466 P11_PCU_S_NDRReadyToWork "NDR ready to work";
CM_ SG_ 1466 P11_PCU_S_OBCReadyToWork "On Board Charger (OBC) ready to work";
CM_ SG_ 1466 P11_PCU_S_MCUReadyToWork "Motor Control Unit (MCU) ready to work";
CM_ SG_ 1466 P11_PCU_S_DCDCReadyToWork "DC-DC ready to work";
CM_ SG_ 1466 P11_PCU_S_CoolerCompressorReadyT "Cooler compressor ready to work";
CM_ SG_ 1466 P11_PCU_S_CabinHeaterReadyToWork "Cabin heater ready to work";
CM_ SG_ 1466 P11_PCU_S_BMSReadyToWork "Battery Management System (BMS) ready to work";
CM_ BO_ 1450 "MCU";
CM_ SG_ 1450 P10_PCU_D_PedalSupplyChannel2 "Pedal supply voltage channel 2 (5V)";
CM_ SG_ 1450 P10_PCU_D_PedalSupplyChannel1 "Pedal supply voltage channel 1 (5V)";
CM_ SG_ 1450 P10_PCU_D_3V3SupplyVoltage "3.3V supply voltage";
CM_ SG_ 1450 P10_PCU_D_CRC "8 bit CRC";
CM_ SG_ 1450 P10_PCU_D_Counter "8 bit up counter";
CM_ SG_ 1450 P10_PCU_D_5VSupplyVoltage "5V supply voltage";
CM_ SG_ 1450 P10_PCU_D_InputVoltage "Input battery 12V voltage";
CM_ SG_ 1450 P10_PCU_D_ProcessorTemperature "Precessor temperature";
CM_ BO_ 1434 "fan valve waterTemperature";
CM_ SG_ 1434 P09_PCU_S_BatteryChillerValveSta "Battery chiller valve status";
CM_ SG_ 1434 P09_PCU_S_CabinCoolerValveStatus "Cabin cooler valve status";
CM_ SG_ 1434 P09_PCU_F_CabinCoolerValveMismat "Cabin cooler valve command-status mismatch fault";
CM_ SG_ 1434 P09_PCU_S_OBDFanCommand "OBD cooling fan Command";
CM_ SG_ 1434 P09_PCU_F_EDUCoolantTemperatureO "Electric Drive Unit (EDU) coolant temperature sensor open circuit fault";
CM_ SG_ 1434 P09_PCU_D_CRC "8 bit CRC";
CM_ SG_ 1434 P09_PCU_D_Counter "8 bit up counter";
CM_ SG_ 1434 P09_PCU_D_EDUCoolantTemperature "Electric Drive Unit (EDU) coolant temperature";
CM_ SG_ 1434 P09_PCU_D_BatteryPackCoolantTemp "Battery pack coolant temperature";
CM_ SG_ 1434 P09_PCU_F_EDUCoolantTemperatureS "Electric Drive Unit (EDU) coolant temperature sensor short circuit fault";
CM_ SG_ 1434 P09_PCU_F_BatteryPackCoolantTemp "Battery pack coolant temperature sensor open circuit fault";
CM_ SG_ 1434 P09_PCU_F_BatteryPackCoolan_0000 "Battery pack coolant temperature sensor short circuit fault";
CM_ SG_ 1434 P09_PCU_S_CabinCoolerValveComman "Cabin cooler valve command";
CM_ SG_ 1434 P09_PCU_S_BatteryChillerValveCom "Battery chiller valve command";
CM_ SG_ 1434 P09_PCU_F_BatteryChillerValveMis "Battery chiller valve command-status mismatch fault";
CM_ SG_ 1434 P09_PCU_S_FanCommandState "Cooling fan command state";
CM_ BO_ 1594 "Break_1";
CM_ SG_ 1594 P08_PCU_D_CRC "8 bit CRC";
CM_ SG_ 1594 P08_PCU_D_Counter "8 bit up counter";
CM_ SG_ 1594 P08_PCU_D_BrakePedalPercent "Brake pedal percent";
CM_ BO_ 1402 "throttle_1";
CM_ SG_ 1402 P07_PCU_D_AcceleratorPedalPositi "Accelerator pedal position channel 2 percent";
CM_ SG_ 1402 P07_PCU_D_AcceleratorPedalP_0000 "Accelerator pedal position channel 1 percent";
CM_ SG_ 1402 P07_PCU_D_CRC "8 bit CRC";
CM_ SG_ 1402 P07_PCU_D_Counter "8 bit up counter";
CM_ SG_ 1402 P07_PCU_D_AcceleratorPedalP_0001 "Accelerator pedal position percent";
CM_ BO_ 1386 "ABS";
CM_ SG_ 1386 P06_PCU_D_BatteryPackPower "Battery pack power";
CM_ SG_ 1386 P06_PCU_D_BatteryPackCycle "Battery pack cycles";
CM_ SG_ 1386 P06_PCU_D_CRC "8 bit CRC";
CM_ SG_ 1386 P06_PCU_D_Counter "8 bit up counter";
CM_ SG_ 1386 P06_PCU_D_VehicleSpeed "Vehicle speed";
CM_ BO_ 1370 "EDU_temperature";
CM_ SG_ 1370 P05_PCU_S_BatteryPackHeaterHVILS "Battery pack heater HV Interlock (HVIL) state";
CM_ SG_ 1370 P05_PCU_S_CoolerCompressorHVILSt "Cooler Compressor HV Interlock (HVIL) state";
CM_ SG_ 1370 P05_PCU_S_CoolingActuatorPowerSt "Cooling actuator (fan and pump) power status";
CM_ SG_ 1370 P05_PCU_S_VacuumPumpPowerStatus "Vacuum pump power status";
CM_ SG_ 1370 P05_PCU_S_StartSwitchState "Vehicle start switch state";
CM_ SG_ 1370 P05_PCU_S_FanHighAndLowSpeedStat "High and low speed cooling fan status";
CM_ SG_ 1370 P05_PCU_D_CRC "8 bit CRC";
CM_ SG_ 1370 P05_PCU_D_Counter "8 bit up counter";
CM_ SG_ 1370 P05_PCU_D_EDUCoolantTemperatureA "Electric Drive Unit (EDU) coolant temperature (ADC Raw)";
CM_ BO_ 1354 "throttle_2 - throttle_1 - bp_temperature";
CM_ SG_ 1354 P04_PCU_D_CRC "8 bit CRC";
CM_ SG_ 1354 P04_PCU_D_Counter "8 bit up counter";
CM_ SG_ 1354 P04_PCU_D_BatteryCoolantTemperat "Battery coolant temperature (ADC Raw)";
CM_ SG_ 1354 P04_PCU_D_AcceleratorPedalPositi "Accelerator pedal position channel 1 (ADC Raw)";
CM_ SG_ 1354 P04_PCU_D_AcceleratorPedalP_0000 "Accelerator pedal position channel 2 (ADC Raw)";
CM_ BO_ 1338 "cruise - brake_1 - brake_2";
CM_ SG_ 1338 P03_PCU_D_CRC "8 bit CRC";
CM_ SG_ 1338 P03_PCU_D_Counter "8 bit up counter";
CM_ SG_ 1338 P03_PCU_D_CruiseKeyADCRaw "Cruise control key (ADC Raw)";
CM_ BO_ 1322 "Io App Pack 1";
CM_ SG_ 1322 P02_PCU_S_PressureSwitchFanHighS "High speed cooling fan state triggered by the pressure switch";
CM_ SG_ 1322 P02_PCU_S_VehiclePowerUpRelaySta "Vehicle power up relay status";
CM_ SG_ 1322 P02_PCU_D_CRC "8 bit CRC";
CM_ SG_ 1322 P02_PCU_D_Counter "8 bit up counter";
CM_ SG_ 1322 P02_PCU_D_AirConditionerTemperat "Air conditioner temperature knob (ADC Raw)";
CM_ SG_ 1322 P02_PCU_S_VacuumPumpPWMState "Vacuum pump PWM state";
CM_ SG_ 1322 P02_PCU_S_BlowerFanSelectorState "Blower fan selector state";
CM_ SG_ 1322 P02_PCU_S_FastChargeRelayStatus "Fast charge relay status";
CM_ SG_ 1322 P02_PCU_S_ESCKeyState "Electronic Stability Control (ESC) key state";
CM_ SG_ 1322 P02_PCU_S_BrakeMicroSwitchState "Brake pedal micro switch state";
CM_ SG_ 1322 P02_PCU_S_BrakeStopPedalState "Brake stop pedal state";
CM_ SG_ 1322 P02_PCU_S_ACCState "Accessory switch state (Peps stage 1)";
CM_ SG_ 1322 P02_PCU_S_IgnitionState "Ignition state (peps stage 2)";
CM_ SG_ 1322 P02_PCU_S_OBCPlugState "AC charge plug state";
CM_ SG_ 1322 P02_PCU_S_CabinCoolerValveStatus "Cabin A/C cooler valve status";
CM_ SG_ 1322 P02_PCU_S_BatteryChillerValveSta "Battery chiller valve status";
CM_ SG_ 1322 P02_PCU_S_PressureSwitchState "Pressure switch state";
CM_ SG_ 1322 P02_PCU_S_AirConditionerKeyState "Air conditioner key state";
CM_ SG_ 1322 P02_PCU_S_BatteryPackSlowChargeW "Battery pack slow charge wake up command";
CM_ SG_ 1322 P02_PCU_S_BatteryPackQuickCharge "Battery pack quick charge wake up command";
CM_ SG_ 1322 P02_PCU_S_BatteryPackKeyOnStatus "Battery pack key on status";
CM_ SG_ 1322 P02_PCU_S_ReverseLightCommand "Reverse light command";
CM_ SG_ 1322 P02_PCU_S_BatteryChillerValveCom "Battery chiller valve  command";
CM_ SG_ 1322 P02_PCU_S_BlowerFanRelayPowerCom "Blower fan relay power command";
CM_ SG_ 1322 P02_PCU_S_FanHighSpeedRelayComma "High speed cooling fan relay command";
CM_ SG_ 1322 P02_PCU_S_HMIPowerCommand "Human Machine Interface (HMI) power command";
CM_ SG_ 1322 P02_PCU_S_CabinCoolerValvePowerC "Cabin A/C cooler valve command";
CM_ SG_ 1322 P02_PCU_S_EDUPumpCommand "Electric Drive Unit (EDU) pump command";
CM_ SG_ 1322 P02_PCU_S_BatteryPackWaterPumpPo "Battery pack water pump power command";
CM_ SG_ 1322 P02_PCU_S_VacuumPumpCommand "Vacuum pump command";
CM_ SG_ 1322 P02_PCU_S_FanLowSpeedRelayComman "Low speed cooling fan relay command";
CM_ SG_ 1322 P02_PCU_S_KL15DCDCCommand "DC-DC enable command";
CM_ SG_ 1322 P02_PCU_S_KL15FastChargeCommand "Fast charge enable command";
CM_ SG_ 1322 P02_PCU_S_KL15MCUCommand "Motor Control Unit (MCU) enable command";
CM_ SG_ 1306 P01_PCU_D_CRC "8 bit CRC";
CM_ SG_ 1306 P01_PCU_D_Counter "8 bit up counter";
CM_ SG_ 1306 P01_PCU_D_VIN4 "VIN code 4";
CM_ SG_ 1306 P01_PCU_D_VIN3 "VIN code 3";
CM_ SG_ 1306 P01_PCU_D_VIN2 "VIN code 2";
CM_ SG_ 1306 P01_PCU_D_VIN1 "VIN code 1";
CM_ SG_ 1306 P01_PCU_D_VIN0 "VIN code 0";
CM_ SG_ 1306 P01_PCU_D_VINIndex "VIN Index number";
CM_ SG_ 1290 P00_PCU_D_CRC "8 bit CRC";
CM_ SG_ 1290 P00_PCU_D_Counter "8 bit up counter";
CM_ SG_ 1290 P00_PCU_S_OBDPermissionState "On Board Diagnostics(OBD) permission state based on vehicle mode";
CM_ SG_ 1290 P00_PCU_S_ActualGearState "Vehicle NDR state";
CM_ SG_ 1290 P00_PCU_D_VehicleSpeed "Vehicle speed";
CM_ SG_ 1290 P00_PCU_S_VehicleModeState "Vehicle mode state";
CM_ SG_ 1290 P00_PCU_S_SystemModeState "System mode state";
BA_DEF_ SG_  "Priority" INT 0 4;
BA_DEF_ SG_  "FaultZone" STRING ;
BA_DEF_ SG_  "FaultTrigger" STRING ;
BA_DEF_ SG_  "FaultEffect" STRING ;
BA_DEF_ SG_  "FaultAction" STRING ;
BA_DEF_ BO_  "TXRX" ENUM  "TX","RX";
BA_DEF_ BO_  "J1939PgAppearanceOnBus" ENUM  "Default","CAN_Extended","CANFD_Extended";
BA_DEF_ SG_  "SigType" ENUM  "Default","Range","RangeSigned","ASCII","Discrete","Control","ReferencePGN","DTC","StringDelimiter","StringLength","StringLengthControl";
BA_DEF_ SG_  "GenSigEVName" STRING ;
BA_DEF_ SG_  "GenSigILSupport" ENUM  "No","Yes";
BA_DEF_ SG_  "GenSigSendType" ENUM  "Cyclic","OnWrite","OnWriteWithRepetition","OnChange","OnChangeWithRepetition","IfActive","IfActiveWithRepetition","NoSigSendType";
BA_DEF_ SG_  "GenSigStartValue" INT 0 2147483647;
BA_DEF_ BO_  "GenMsgILSupport" ENUM  "No","Yes";
BA_DEF_ BU_  "NmStationAddress" INT 0 255;
BA_DEF_ BO_  "GenMsgSendType" ENUM  "cyclic","NotUsed","IfActive","NotUsed","NotUsed","NotUsed","NotUsed","NotUsed","noMsgSendType";
BA_DEF_ BO_  "GenMsgRequestable" INT 0 1;
BA_DEF_ BO_  "GenMsgCycleTime" INT 0 3600000;
BA_DEF_ SG_  "SPN" INT 0 524287;
BA_DEF_  "DBName" STRING ;
BA_DEF_  "BusType" STRING ;
BA_DEF_  "ProtocolType" STRING ;
BA_DEF_ BO_  "VFrameFormat" ENUM  "StandardCAN","ExtendedCAN","reserved","J1939PG","reserved","reserved","reserved","reserved","reserved","reserved","reserved","reserved","reserved","reserved","StandardCAN_FD","ExtendedCAN_FD";
BA_DEF_ SG_  "SystemSignalLongSymbol" STRING ;
BA_DEF_DEF_  "Priority" 0;
BA_DEF_DEF_  "FaultZone" "";
BA_DEF_DEF_  "FaultTrigger" "";
BA_DEF_DEF_  "FaultEffect" "";
BA_DEF_DEF_  "FaultAction" "";
BA_DEF_DEF_  "TXRX" "TX";
BA_DEF_DEF_  "J1939PgAppearanceOnBus" "Default";
BA_DEF_DEF_  "SigType" "Default";
BA_DEF_DEF_  "GenSigEVName" "Env@Nodename_@Signame";
BA_DEF_DEF_  "GenSigILSupport" "Yes";
BA_DEF_DEF_  "GenSigSendType" "NoSigSendType";
BA_DEF_DEF_  "GenSigStartValue" 0;
BA_DEF_DEF_  "GenMsgILSupport" "Yes";
BA_DEF_DEF_  "NmStationAddress" 254;
BA_DEF_DEF_  "GenMsgSendType" "noMsgSendType";
BA_DEF_DEF_  "GenMsgRequestable" 1;
BA_DEF_DEF_  "GenMsgCycleTime" 0;
BA_DEF_DEF_  "SPN" 0;
BA_DEF_DEF_  "DBName" "";
BA_DEF_DEF_  "BusType" "CAN";
BA_DEF_DEF_  "ProtocolType" "J1939";
BA_DEF_DEF_  "VFrameFormat" "J1939PG";
BA_DEF_DEF_  "SystemSignalLongSymbol" "";
BA_ "ProtocolType" "CAN";
BA_ "DBName" "PCU";
BA_ "GenMsgCycleTime" BO_ 1802 100;
BA_ "VFrameFormat" BO_ 1802 0;
BA_ "GenMsgCycleTime" BO_ 1770 100;
BA_ "VFrameFormat" BO_ 1770 0;
BA_ "VFrameFormat" BO_ 1082 0;
BA_ "GenMsgCycleTime" BO_ 1082 100;
BA_ "GenMsgCycleTime" BO_ 1066 100;
BA_ "VFrameFormat" BO_ 1066 0;
BA_ "GenMsgCycleTime" BO_ 1050 100;
BA_ "VFrameFormat" BO_ 1050 0;
BA_ "GenMsgCycleTime" BO_ 1034 100;
BA_ "VFrameFormat" BO_ 1034 0;
BA_ "GenMsgCycleTime" BO_ 1578 100;
BA_ "VFrameFormat" BO_ 1578 0;
BA_ "GenMsgCycleTime" BO_ 1514 100;
BA_ "VFrameFormat" BO_ 1514 0;
BA_ "GenMsgCycleTime" BO_ 1530 100;
BA_ "VFrameFormat" BO_ 1530 0;
BA_ "GenMsgCycleTime" BO_ 1546 100;
BA_ "VFrameFormat" BO_ 1546 0;
BA_ "VFrameFormat" BO_ 1194 0;
BA_ "GenMsgCycleTime" BO_ 1194 100;
BA_ "VFrameFormat" BO_ 1178 0;
BA_ "GenMsgCycleTime" BO_ 1178 100;
BA_ "VFrameFormat" BO_ 1162 0;
BA_ "GenMsgCycleTime" BO_ 1162 100;
BA_ "VFrameFormat" BO_ 1146 0;
BA_ "GenMsgCycleTime" BO_ 1146 100;
BA_ "VFrameFormat" BO_ 1130 0;
BA_ "GenMsgCycleTime" BO_ 1130 100;
BA_ "VFrameFormat" BO_ 1114 0;
BA_ "GenMsgCycleTime" BO_ 1114 100;
BA_ "VFrameFormat" BO_ 1098 0;
BA_ "GenMsgCycleTime" BO_ 1098 100;
BA_ "VFrameFormat" BO_ 1498 0;
BA_ "GenMsgCycleTime" BO_ 1498 100;
BA_ "VFrameFormat" BO_ 1482 0;
BA_ "GenMsgCycleTime" BO_ 1482 100;
BA_ "GenMsgCycleTime" BO_ 1274 100;
BA_ "VFrameFormat" BO_ 1274 0;
BA_ "GenMsgCycleTime" BO_ 1258 100;
BA_ "VFrameFormat" BO_ 1258 0;
BA_ "GenMsgCycleTime" BO_ 1242 100;
BA_ "VFrameFormat" BO_ 1242 0;
BA_ "GenMsgCycleTime" BO_ 1226 100;
BA_ "VFrameFormat" BO_ 1226 0;
BA_ "VFrameFormat" BO_ 1210 0;
BA_ "GenMsgCycleTime" BO_ 1210 100;
BA_ "VFrameFormat" BO_ 1466 0;
BA_ "GenMsgCycleTime" BO_ 1466 100;
BA_ "VFrameFormat" BO_ 1450 0;
BA_ "GenMsgCycleTime" BO_ 1450 100;
BA_ "VFrameFormat" BO_ 1434 0;
BA_ "GenMsgCycleTime" BO_ 1434 100;
BA_ "VFrameFormat" BO_ 1594 0;
BA_ "GenMsgCycleTime" BO_ 1594 100;
BA_ "VFrameFormat" BO_ 1402 0;
BA_ "GenMsgCycleTime" BO_ 1402 100;
BA_ "VFrameFormat" BO_ 1386 0;
BA_ "GenMsgCycleTime" BO_ 1386 100;
BA_ "VFrameFormat" BO_ 1370 0;
BA_ "GenMsgCycleTime" BO_ 1370 100;
BA_ "VFrameFormat" BO_ 1354 0;
BA_ "GenMsgCycleTime" BO_ 1354 100;
BA_ "VFrameFormat" BO_ 1338 0;
BA_ "GenMsgCycleTime" BO_ 1338 100;
BA_ "VFrameFormat" BO_ 1322 0;
BA_ "GenMsgCycleTime" BO_ 1322 100;
BA_ "VFrameFormat" BO_ 1306 0;
BA_ "GenMsgCycleTime" BO_ 1306 100;
BA_ "VFrameFormat" BO_ 1290 0;
BA_ "GenMsgCycleTime" BO_ 1290 100;
BA_ "Priority" SG_ 1802 P35_PCU_S_VacuumPumpDisableState 4;
BA_ "SPN" SG_ 1802 P35_PCU_S_VacuumPumpDisableState 2402;
BA_ "Priority" SG_ 1802 P35_PCU_S_TCSDisableState 4;
BA_ "SPN" SG_ 1802 P35_PCU_S_TCSDisableState 2400;
BA_ "Priority" SG_ 1802 P35_PCU_S_SpeedLimit80kmState 3;
BA_ "SPN" SG_ 1802 P35_PCU_S_SpeedLimit80kmState 2396;
BA_ "Priority" SG_ 1802 P35_PCU_S_SpeedLimit40kmState 3;
BA_ "SPN" SG_ 1802 P35_PCU_S_SpeedLimit40kmState 2395;
BA_ "Priority" SG_ 1802 P35_PCU_S_SpeedLimit120kmState 3;
BA_ "SPN" SG_ 1802 P35_PCU_S_SpeedLimit120kmState 2397;
BA_ "SPN" SG_ 1802 P35_PCU_S_SpeedLimit0kmState 2394;
BA_ "Priority" SG_ 1802 P35_PCU_S_RetardDisableState 4;
BA_ "SPN" SG_ 1802 P35_PCU_S_RetardDisableState 2401;
BA_ "SPN" SG_ 1802 P35_PCU_S_DriveBodyPermissionSta 2392;
BA_ "SystemSignalLongSymbol" SG_ 1802 P35_PCU_S_DriveBodyPermissionSta "P35_PCU_S_DriveBodyPermissionState";
BA_ "Priority" SG_ 1802 P35_PCU_S_CruiseDisableState 4;
BA_ "SPN" SG_ 1802 P35_PCU_S_CruiseDisableState 2399;
BA_ "Priority" SG_ 1802 P35_PCU_S_CreepDisableState 3;
BA_ "SPN" SG_ 1802 P35_PCU_S_CreepDisableState 2398;
BA_ "SPN" SG_ 1802 P35_PCU_D_RetardTorqueSetpointPe 2393;
BA_ "SystemSignalLongSymbol" SG_ 1802 P35_PCU_D_RetardTorqueSetpointPe "P35_PCU_D_RetardTorqueSetpointPercent";
BA_ "SPN" SG_ 1770 P34_PCU_S_PowerSavingState 2986;
BA_ "SPN" SG_ 1770 P34_PCU_S_FlasherEnableState 2987;
BA_ "SPN" SG_ 1770 P34_PCU_S_DCDCEnableStatus 2989;
BA_ "SPN" SG_ 1770 P34_PCU_S_BrakeLightState 2988;
BA_ "SPN" SG_ 1082 P33_PCU_S_DCLState 2984;
BA_ "SPN" SG_ 1082 P33_PCU_S_CCLState 2983;
BA_ "SPN" SG_ 1082 P33_PCU_S_BatteryTempUniformityS 2985;
BA_ "SystemSignalLongSymbol" SG_ 1082 P33_PCU_S_BatteryTempUniformityS "P33_PCU_S_BatteryTempUniformityState";
BA_ "SPN" SG_ 1082 P33_PCU_S_CompressorDeceleration 2942;
BA_ "SystemSignalLongSymbol" SG_ 1082 P33_PCU_S_CompressorDeceleration "P33_PCU_S_CompressorDecelerationRequestState";
BA_ "SPN" SG_ 1082 P33_PCU_D_AdaptiveBatteryPackCoo 2941;
BA_ "SystemSignalLongSymbol" SG_ 1082 P33_PCU_D_AdaptiveBatteryPackCoo "P33_PCU_D_AdaptiveBatteryPackCoolantWarmThreshold";
BA_ "GenSigSendType" SG_ 1066 P31_PCU_D_CruiseSpeedSetpoint 0;
BA_ "SPN" SG_ 1066 P31_PCU_D_CruiseSpeedSetpoint 2940;
BA_ "GenSigSendType" SG_ 1066 P31_PCU_S_CruiseState 0;
BA_ "SPN" SG_ 1066 P31_PCU_S_CruiseState 2939;
BA_ "GenSigSendType" SG_ 1066 P31_PCU_D_CRC8 0;
BA_ "GenSigSendType" SG_ 1066 P31_PCU_D_Counter 0;
BA_ "GenSigSendType" SG_ 1066 P31_PCU_D_TCSTorqueSetpoint 0;
BA_ "GenSigStartValue" SG_ 1066 P31_PCU_D_TCSTorqueSetpoint 300;
BA_ "SPN" SG_ 1066 P31_PCU_D_TCSTorqueSetpoint 2523;
BA_ "GenSigSendType" SG_ 1066 P31_PCU_D_TASMCUTorqueSetpoint 0;
BA_ "GenSigStartValue" SG_ 1066 P31_PCU_D_TASMCUTorqueSetpoint 300;
BA_ "SPN" SG_ 1066 P31_PCU_D_TASMCUTorqueSetpoint 2522;
BA_ "GenSigSendType" SG_ 1050 P30_PCU_D_CRC 0;
BA_ "GenSigSendType" SG_ 1050 P30_PCU_D_Counter 0;
BA_ "GenSigSendType" SG_ 1050 P30_PCU_D_RetardTorqueSetpoint 0;
BA_ "GenSigStartValue" SG_ 1050 P30_PCU_D_RetardTorqueSetpoint 300;
BA_ "SPN" SG_ 1050 P30_PCU_D_RetardTorqueSetpoint 2521;
BA_ "GenSigSendType" SG_ 1050 P30_PCU_D_RegenTorqueSetpoint 0;
BA_ "GenSigStartValue" SG_ 1050 P30_PCU_D_RegenTorqueSetpoint 300;
BA_ "SPN" SG_ 1050 P30_PCU_D_RegenTorqueSetpoint 2520;
BA_ "GenSigSendType" SG_ 1050 P30_PCU_D_CruiseTorqueSetpoint 0;
BA_ "GenSigStartValue" SG_ 1050 P30_PCU_D_CruiseTorqueSetpoint 300;
BA_ "SPN" SG_ 1050 P30_PCU_D_CruiseTorqueSetpoint 2519;
BA_ "GenSigSendType" SG_ 1034 P29_PCU_S_CruiseButtonOnState 0;
BA_ "SPN" SG_ 1034 P29_PCU_S_CruiseButtonOnState 2936;
BA_ "GenSigSendType" SG_ 1034 P29_PCU_S_CruiseButtonOffState 0;
BA_ "SPN" SG_ 1034 P29_PCU_S_CruiseButtonOffState 2935;
BA_ "GenSigSendType" SG_ 1034 P29_PCU_S_CruiseButtonIncreaseSt 0;
BA_ "SPN" SG_ 1034 P29_PCU_S_CruiseButtonIncreaseSt 2938;
BA_ "SystemSignalLongSymbol" SG_ 1034 P29_PCU_S_CruiseButtonIncreaseSt "P29_PCU_S_CruiseButtonIncreaseState";
BA_ "GenSigSendType" SG_ 1034 P29_PCU_S_CruiseButtonDecreaseSt 0;
BA_ "SPN" SG_ 1034 P29_PCU_S_CruiseButtonDecreaseSt 2937;
BA_ "SystemSignalLongSymbol" SG_ 1034 P29_PCU_S_CruiseButtonDecreaseSt "P29_PCU_S_CruiseButtonDecreaseState";
BA_ "GenSigSendType" SG_ 1034 P29_PCU_D_CRC 0;
BA_ "GenSigSendType" SG_ 1034 P29_PCU_D_Counter 0;
BA_ "SPN" SG_ 1034 P29_PCU_D_CreepTorqueSetpoint 2518;
BA_ "GenSigStartValue" SG_ 1034 P29_PCU_D_CreepTorqueSetpoint 300;
BA_ "GenSigSendType" SG_ 1034 P29_PCU_D_CreepTorqueSetpoint 0;
BA_ "GenSigStartValue" SG_ 1034 P29_PCU_D_AcceleratorTorqueSetpo 300;
BA_ "SPN" SG_ 1034 P29_PCU_D_AcceleratorTorqueSetpo 2517;
BA_ "GenSigSendType" SG_ 1034 P29_PCU_D_AcceleratorTorqueSetpo 0;
BA_ "SystemSignalLongSymbol" SG_ 1034 P29_PCU_D_AcceleratorTorqueSetpo "P29_PCU_D_AcceleratorTorqueSetpoint";
BA_ "SPN" SG_ 1034 P29_PCU_S_HillHoldActiveState 2516;
BA_ "GenSigSendType" SG_ 1034 P29_PCU_S_HillHoldActiveState 0;
BA_ "SPN" SG_ 1034 P29_PCU_S_RetardActiveState 2515;
BA_ "GenSigSendType" SG_ 1034 P29_PCU_S_RetardActiveState 0;
BA_ "SPN" SG_ 1034 P29_PCU_S_CruiseActiveState 2513;
BA_ "GenSigSendType" SG_ 1034 P29_PCU_S_CruiseActiveState 0;
BA_ "SPN" SG_ 1034 P29_PCU_S_CreepModeActiveState 2512;
BA_ "GenSigSendType" SG_ 1034 P29_PCU_S_CreepModeActiveState 0;
BA_ "SPN" SG_ 1034 P29_PCU_S_AcceleratorModeActiveS 2511;
BA_ "GenSigSendType" SG_ 1034 P29_PCU_S_AcceleratorModeActiveS 0;
BA_ "SystemSignalLongSymbol" SG_ 1034 P29_PCU_S_AcceleratorModeActiveS "P29_PCU_S_AcceleratorModeActiveState";
BA_ "Priority" SG_ 1034 P29_PCU_S_TCSActiveState 3;
BA_ "SPN" SG_ 1034 P29_PCU_S_TCSActiveState 2510;
BA_ "GenSigSendType" SG_ 1034 P29_PCU_S_TCSActiveState 0;
BA_ "Priority" SG_ 1578 P32_PCU_F_EEPROMCellCycleTimeout 1;
BA_ "SPN" SG_ 1578 P32_PCU_F_EEPROMCellCycleTimeout 2991;
BA_ "GenSigSendType" SG_ 1578 P32_PCU_F_EEPROMCellCycleTimeout 0;
BA_ "FaultAction" SG_ 1578 P32_PCU_F_EEPROMCellCycleTimeout "check eeprom chip in pcu pcb";
BA_ "FaultEffect" SG_ 1578 P32_PCU_F_EEPROMCellCycleTimeout "Publish on CAN";
BA_ "FaultTrigger" SG_ 1578 P32_PCU_F_EEPROMCellCycleTimeout "data restore time elapse";
BA_ "FaultZone" SG_ 1578 P32_PCU_F_EEPROMCellCycleTimeout "eeprom memory";
BA_ "SystemSignalLongSymbol" SG_ 1578 P32_PCU_F_EEPROMCellCycleTimeout "P32_PCU_F_EEPROMCellCycleTimeoutFault";
BA_ "Priority" SG_ 1578 P32_PCU_F_EEPROMMCUIDTimeoutFaul 1;
BA_ "SPN" SG_ 1578 P32_PCU_F_EEPROMMCUIDTimeoutFaul 2990;
BA_ "GenSigSendType" SG_ 1578 P32_PCU_F_EEPROMMCUIDTimeoutFaul 0;
BA_ "FaultAction" SG_ 1578 P32_PCU_F_EEPROMMCUIDTimeoutFaul "check eeprom chip in pcu pcb";
BA_ "FaultEffect" SG_ 1578 P32_PCU_F_EEPROMMCUIDTimeoutFaul "Publish on CAN";
BA_ "FaultTrigger" SG_ 1578 P32_PCU_F_EEPROMMCUIDTimeoutFaul "data restore time elapse";
BA_ "FaultZone" SG_ 1578 P32_PCU_F_EEPROMMCUIDTimeoutFaul "eeprom memory";
BA_ "SystemSignalLongSymbol" SG_ 1578 P32_PCU_F_EEPROMMCUIDTimeoutFaul "P32_PCU_F_EEPROMMCUIDTimeoutFault";
BA_ "Priority" SG_ 1578 P32_PCU_F_DOLFault 1;
BA_ "SPN" SG_ 1578 P32_PCU_F_DOLFault 2977;
BA_ "GenSigSendType" SG_ 1578 P32_PCU_F_DOLFault 0;
BA_ "GenSigSendType" SG_ 1578 P32_PCU_F_FanLowSpeedAbnormalFau 0;
BA_ "Priority" SG_ 1578 P32_PCU_F_FanLowSpeedAbnormalFau 1;
BA_ "SPN" SG_ 1578 P32_PCU_F_FanLowSpeedAbnormalFau 2957;
BA_ "SystemSignalLongSymbol" SG_ 1578 P32_PCU_F_FanLowSpeedAbnormalFau "P32_PCU_F_FanLowSpeedAbnormalFault";
BA_ "Priority" SG_ 1578 P32_PCU_F_FanHighSpeedAbnormalFa 1;
BA_ "SPN" SG_ 1578 P32_PCU_F_FanHighSpeedAbnormalFa 2955;
BA_ "GenSigSendType" SG_ 1578 P32_PCU_F_FanHighSpeedAbnormalFa 0;
BA_ "SystemSignalLongSymbol" SG_ 1578 P32_PCU_F_FanHighSpeedAbnormalFa "P32_PCU_F_FanHighSpeedAbnormalFault";
BA_ "Priority" SG_ 1578 P32_PCU_F_CabinCoolerValveOpenWi 1;
BA_ "SPN" SG_ 1578 P32_PCU_F_CabinCoolerValveOpenWi 2917;
BA_ "GenSigSendType" SG_ 1578 P32_PCU_F_CabinCoolerValveOpenWi 0;
BA_ "SystemSignalLongSymbol" SG_ 1578 P32_PCU_F_CabinCoolerValveOpenWi "P32_PCU_F_CabinCoolerValveOpenWireFault";
BA_ "Priority" SG_ 1578 P32_PCU_F_BatteryChillerValveOpe 1;
BA_ "SPN" SG_ 1578 P32_PCU_F_BatteryChillerValveOpe 2915;
BA_ "GenSigSendType" SG_ 1578 P32_PCU_F_BatteryChillerValveOpe 0;
BA_ "SystemSignalLongSymbol" SG_ 1578 P32_PCU_F_BatteryChillerValveOpe "P32_PCU_F_BatteryChillerValveOpenWireFault";
BA_ "Priority" SG_ 1578 P32_PCU_F_FanHighSpeedAbnormalPr 1;
BA_ "SPN" SG_ 1578 P32_PCU_F_FanHighSpeedAbnormalPr 2494;
BA_ "GenSigSendType" SG_ 1578 P32_PCU_F_FanHighSpeedAbnormalPr 0;
BA_ "FaultZone" SG_ 1578 P32_PCU_F_FanHighSpeedAbnormalPr "compressor";
BA_ "FaultEffect" SG_ 1578 P32_PCU_F_FanHighSpeedAbnormalPr "No action";
BA_ "FaultAction" SG_ 1578 P32_PCU_F_FanHighSpeedAbnormalPr "1- check fan



2- check compressor";
BA_ "FaultTrigger" SG_ 1578 P32_PCU_F_FanHighSpeedAbnormalPr "FAN command high, real FAN status low";
BA_ "SystemSignalLongSymbol" SG_ 1578 P32_PCU_F_FanHighSpeedAbnormalPr "P32_PCU_F_FanHighSpeedAbnormalPressureSwitchFault";
BA_ "Priority" SG_ 1578 P32_PCU_F_PressureSwitchAbnormal 2;
BA_ "SPN" SG_ 1578 P32_PCU_F_PressureSwitchAbnormal 2493;
BA_ "GenSigSendType" SG_ 1578 P32_PCU_F_PressureSwitchAbnormal 0;
BA_ "FaultZone" SG_ 1578 P32_PCU_F_PressureSwitchAbnormal "compressor";
BA_ "FaultEffect" SG_ 1578 P32_PCU_F_PressureSwitchAbnormal "No action";
BA_ "FaultAction" SG_ 1578 P32_PCU_F_PressureSwitchAbnormal "1- check presuure switch



2- check compressor";
BA_ "FaultTrigger" SG_ 1578 P32_PCU_F_PressureSwitchAbnormal "Compressor is defected and pressure switch is activated";
BA_ "SystemSignalLongSymbol" SG_ 1578 P32_PCU_F_PressureSwitchAbnormal "P32_PCU_F_PressureSwitchAbnormalFault";
BA_ "Priority" SG_ 1578 P32_PCU_F_PressureSwitchHardware 2;
BA_ "SPN" SG_ 1578 P32_PCU_F_PressureSwitchHardware 2492;
BA_ "GenSigSendType" SG_ 1578 P32_PCU_F_PressureSwitchHardware 0;
BA_ "FaultZone" SG_ 1578 P32_PCU_F_PressureSwitchHardware "compressor";
BA_ "FaultEffect" SG_ 1578 P32_PCU_F_PressureSwitchHardware "No action";
BA_ "FaultAction" SG_ 1578 P32_PCU_F_PressureSwitchHardware "1- check presuure switch



2- check compressor";
BA_ "FaultTrigger" SG_ 1578 P32_PCU_F_PressureSwitchHardware "Compressor is defected and pressure switch is activated";
BA_ "SystemSignalLongSymbol" SG_ 1578 P32_PCU_F_PressureSwitchHardware "P32_PCU_F_PressureSwitchHardwareFault";
BA_ "Priority" SG_ 1578 P32_PCU_F_CabinCoolerValveShortC 1;
BA_ "SPN" SG_ 1578 P32_PCU_F_CabinCoolerValveShortC 2478;
BA_ "GenSigSendType" SG_ 1578 P32_PCU_F_CabinCoolerValveShortC 0;
BA_ "FaultZone" SG_ 1578 P32_PCU_F_CabinCoolerValveShortC "High side Switch";
BA_ "FaultEffect" SG_ 1578 P32_PCU_F_CabinCoolerValveShortC "Publish on CAN";
BA_ "FaultAction" SG_ 1578 P32_PCU_F_CabinCoolerValveShortC "Check device connected to high side switch6";
BA_ "FaultTrigger" SG_ 1578 P32_PCU_F_CabinCoolerValveShortC "Check return value from high side switch when switch is turned on";
BA_ "SystemSignalLongSymbol" SG_ 1578 P32_PCU_F_CabinCoolerValveShortC "P32_PCU_F_CabinCoolerValveShortCircuitFault";
BA_ "Priority" SG_ 1578 P32_PCU_F_BatteryChillerValveSho 1;
BA_ "SPN" SG_ 1578 P32_PCU_F_BatteryChillerValveSho 2476;
BA_ "GenSigSendType" SG_ 1578 P32_PCU_F_BatteryChillerValveSho 0;
BA_ "FaultZone" SG_ 1578 P32_PCU_F_BatteryChillerValveSho "High side Switch";
BA_ "FaultEffect" SG_ 1578 P32_PCU_F_BatteryChillerValveSho "Publish on CAN";
BA_ "FaultAction" SG_ 1578 P32_PCU_F_BatteryChillerValveSho "Check device connected to high side switch4";
BA_ "FaultTrigger" SG_ 1578 P32_PCU_F_BatteryChillerValveSho "Check return value from high side switch when switch is turned on";
BA_ "SystemSignalLongSymbol" SG_ 1578 P32_PCU_F_BatteryChillerValveSho "P32_PCU_F_BatteryChillerValveShortCircuitFault";
BA_ "Priority" SG_ 1578 P32_PCU_F_FlashTimeoutFault 1;
BA_ "SPN" SG_ 1578 P32_PCU_F_FlashTimeoutFault 2472;
BA_ "GenSigSendType" SG_ 1578 P32_PCU_F_FlashTimeoutFault 0;
BA_ "FaultZone" SG_ 1578 P32_PCU_F_FlashTimeoutFault "flash memory";
BA_ "FaultEffect" SG_ 1578 P32_PCU_F_FlashTimeoutFault "Publish on CAN";
BA_ "FaultAction" SG_ 1578 P32_PCU_F_FlashTimeoutFault "check flash chip in pcu pcb";
BA_ "FaultTrigger" SG_ 1578 P32_PCU_F_FlashTimeoutFault "data restore time elapse";
BA_ "Priority" SG_ 1578 P32_PCU_F_EEPROMODOTimeoutFault 1;
BA_ "SPN" SG_ 1578 P32_PCU_F_EEPROMODOTimeoutFault 2471;
BA_ "GenSigSendType" SG_ 1578 P32_PCU_F_EEPROMODOTimeoutFault 0;
BA_ "FaultZone" SG_ 1578 P32_PCU_F_EEPROMODOTimeoutFault "eeprom memory";
BA_ "FaultEffect" SG_ 1578 P32_PCU_F_EEPROMODOTimeoutFault "Publish on CAN";
BA_ "FaultAction" SG_ 1578 P32_PCU_F_EEPROMODOTimeoutFault "check eeprom chip in pcu pcb";
BA_ "FaultTrigger" SG_ 1578 P32_PCU_F_EEPROMODOTimeoutFault "data restore time elapse";
BA_ "Priority" SG_ 1578 P32_PCU_F_CANFDTxFIFOFullFault 1;
BA_ "SPN" SG_ 1578 P32_PCU_F_CANFDTxFIFOFullFault 2470;
BA_ "GenSigSendType" SG_ 1578 P32_PCU_F_CANFDTxFIFOFullFault 0;
BA_ "Priority" SG_ 1578 P32_PCU_F_CANFDTxBusOffFault 1;
BA_ "SPN" SG_ 1578 P32_PCU_F_CANFDTxBusOffFault 2469;
BA_ "GenSigSendType" SG_ 1578 P32_PCU_F_CANFDTxBusOffFault 0;
BA_ "FaultZone" SG_ 1578 P32_PCU_F_CANFDTxBusOffFault "CAN FD";
BA_ "FaultEffect" SG_ 1578 P32_PCU_F_CANFDTxBusOffFault "Publish on CAN";
BA_ "FaultAction" SG_ 1578 P32_PCU_F_CANFDTxBusOffFault "Check CAN FD Chip";
BA_ "FaultTrigger" SG_ 1578 P32_PCU_F_CANFDTxBusOffFault "Internal Fault";
BA_ "Priority" SG_ 1578 P32_PCU_F_CANFDTxBusPassiveFault 1;
BA_ "SPN" SG_ 1578 P32_PCU_F_CANFDTxBusPassiveFault 2468;
BA_ "GenSigSendType" SG_ 1578 P32_PCU_F_CANFDTxBusPassiveFault 0;
BA_ "FaultZone" SG_ 1578 P32_PCU_F_CANFDTxBusPassiveFault "CAN FD";
BA_ "FaultEffect" SG_ 1578 P32_PCU_F_CANFDTxBusPassiveFault "Publish on CAN";
BA_ "FaultAction" SG_ 1578 P32_PCU_F_CANFDTxBusPassiveFault "Check CAN FD Chip";
BA_ "FaultTrigger" SG_ 1578 P32_PCU_F_CANFDTxBusPassiveFault "Internal Fault";
BA_ "Priority" SG_ 1578 P32_PCU_F_CANFDRxBusPassiveFault 1;
BA_ "SPN" SG_ 1578 P32_PCU_F_CANFDRxBusPassiveFault 2467;
BA_ "GenSigSendType" SG_ 1578 P32_PCU_F_CANFDRxBusPassiveFault 0;
BA_ "FaultTrigger" SG_ 1578 P32_PCU_F_DiSpiTemperatureShutDo "check flag bits in spi data received from di spi module.";
BA_ "FaultAction" SG_ 1578 P32_PCU_F_DiSpiTemperatureShutDo "Check PCU board (DI SPI IC)";
BA_ "FaultEffect" SG_ 1578 P32_PCU_F_DiSpiTemperatureShutDo "No action";
BA_ "FaultZone" SG_ 1578 P32_PCU_F_DiSpiTemperatureShutDo "digital input spi module";
BA_ "Priority" SG_ 1578 P32_PCU_F_DiSpiTemperatureShutDo 1;
BA_ "SPN" SG_ 1578 P32_PCU_F_DiSpiTemperatureShutDo 2466;
BA_ "GenSigSendType" SG_ 1578 P32_PCU_F_DiSpiTemperatureShutDo 0;
BA_ "SystemSignalLongSymbol" SG_ 1578 P32_PCU_F_DiSpiTemperatureShutDo "P32_PCU_F_DiSpiTemperatureShutDownFault";
BA_ "FaultTrigger" SG_ 1578 P32_PCU_F_DiSpiCheckFault "check flag bits in spi data received from di spi module.";
BA_ "FaultAction" SG_ 1578 P32_PCU_F_DiSpiCheckFault "Check PCU board (DI SPI IC)";
BA_ "FaultEffect" SG_ 1578 P32_PCU_F_DiSpiCheckFault "No action";
BA_ "FaultZone" SG_ 1578 P32_PCU_F_DiSpiCheckFault "digital input spi module";
BA_ "Priority" SG_ 1578 P32_PCU_F_DiSpiCheckFault 1;
BA_ "SPN" SG_ 1578 P32_PCU_F_DiSpiCheckFault 2462;
BA_ "GenSigSendType" SG_ 1578 P32_PCU_F_DiSpiCheckFault 0;
BA_ "FaultTrigger" SG_ 1578 P32_PCU_F_DiSpiTemperatureWarnin "check flag bits in spi data received from di spi module.";
BA_ "FaultAction" SG_ 1578 P32_PCU_F_DiSpiTemperatureWarnin "Check PCU board (DI SPI IC)";
BA_ "FaultEffect" SG_ 1578 P32_PCU_F_DiSpiTemperatureWarnin "No action";
BA_ "FaultZone" SG_ 1578 P32_PCU_F_DiSpiTemperatureWarnin "digital input spi module";
BA_ "Priority" SG_ 1578 P32_PCU_F_DiSpiTemperatureWarnin 1;
BA_ "SPN" SG_ 1578 P32_PCU_F_DiSpiTemperatureWarnin 2465;
BA_ "GenSigSendType" SG_ 1578 P32_PCU_F_DiSpiTemperatureWarnin 0;
BA_ "SystemSignalLongSymbol" SG_ 1578 P32_PCU_F_DiSpiTemperatureWarnin "P32_PCU_F_DiSpiTemperatureWarning";
BA_ "FaultTrigger" SG_ 1578 P32_PCU_F_DiSpiOverVoltageFault "check flag bits in spi data received from di spi module.";
BA_ "FaultAction" SG_ 1578 P32_PCU_F_DiSpiOverVoltageFault "Check PCU board (DI SPI IC)";
BA_ "FaultEffect" SG_ 1578 P32_PCU_F_DiSpiOverVoltageFault "No action";
BA_ "FaultZone" SG_ 1578 P32_PCU_F_DiSpiOverVoltageFault "digital input spi module";
BA_ "Priority" SG_ 1578 P32_PCU_F_DiSpiOverVoltageFault 1;
BA_ "SPN" SG_ 1578 P32_PCU_F_DiSpiOverVoltageFault 2464;
BA_ "GenSigSendType" SG_ 1578 P32_PCU_F_DiSpiOverVoltageFault 0;
BA_ "FaultTrigger" SG_ 1578 P32_PCU_F_DiSpiUnderVoltageFault "check flag bits in spi data received from di spi module.";
BA_ "FaultAction" SG_ 1578 P32_PCU_F_DiSpiUnderVoltageFault "Check PCU board (DI SPI IC)";
BA_ "FaultEffect" SG_ 1578 P32_PCU_F_DiSpiUnderVoltageFault "No action";
BA_ "FaultZone" SG_ 1578 P32_PCU_F_DiSpiUnderVoltageFault "digital input spi module";
BA_ "Priority" SG_ 1578 P32_PCU_F_DiSpiUnderVoltageFault 1;
BA_ "SPN" SG_ 1578 P32_PCU_F_DiSpiUnderVoltageFault 2463;
BA_ "GenSigSendType" SG_ 1578 P32_PCU_F_DiSpiUnderVoltageFault 0;
BA_ "FaultTrigger" SG_ 1578 P32_PCU_F_DiSpiParityFault "check flag bits in spi data received from di spi module.";
BA_ "FaultAction" SG_ 1578 P32_PCU_F_DiSpiParityFault "Check PCU board (DI SPI IC)";
BA_ "FaultEffect" SG_ 1578 P32_PCU_F_DiSpiParityFault "No action";
BA_ "FaultZone" SG_ 1578 P32_PCU_F_DiSpiParityFault "digital input spi module";
BA_ "Priority" SG_ 1578 P32_PCU_F_DiSpiParityFault 1;
BA_ "SPN" SG_ 1578 P32_PCU_F_DiSpiParityFault 2461;
BA_ "GenSigSendType" SG_ 1578 P32_PCU_F_DiSpiParityFault 0;
BA_ "FaultTrigger" SG_ 1578 P32_PCU_F_DiSpiFault "check flag bits in spi data received from di spi module.";
BA_ "FaultAction" SG_ 1578 P32_PCU_F_DiSpiFault "Check PCU board (DI SPI IC)";
BA_ "FaultEffect" SG_ 1578 P32_PCU_F_DiSpiFault "No action";
BA_ "FaultZone" SG_ 1578 P32_PCU_F_DiSpiFault "digital input spi module";
BA_ "SPN" SG_ 1578 P32_PCU_F_DiSpiFault 2460;
BA_ "GenSigSendType" SG_ 1578 P32_PCU_F_DiSpiFault 0;
BA_ "GenSigSendType" SG_ 1578 P32_PCU_D_Counter 0;
BA_ "GenSigSendType" SG_ 1578 P32_PCU_D_CRC 0;
BA_ "SPN" SG_ 1514 P26_PCU_S_RegenState 2921;
BA_ "SPN" SG_ 1514 P26_PCU_S_RegenSOCDerateState 2932;
BA_ "SPN" SG_ 1514 P26_PCU_S_RegenMotorDerateState 2930;
BA_ "SPN" SG_ 1514 P26_PCU_S_RegenMCUDerateState 2929;
BA_ "SPN" SG_ 1514 P26_PCU_S_RegenBatteryDerateStat 2931;
BA_ "SystemSignalLongSymbol" SG_ 1514 P26_PCU_S_RegenBatteryDerateStat "P26_PCU_S_RegenBatteryDerateState";
BA_ "SPN" SG_ 1514 P26_PCU_S_HillholdPermissionStat 2920;
BA_ "SystemSignalLongSymbol" SG_ 1514 P26_PCU_S_HillholdPermissionStat "P26_PCU_S_HillholdPermissionState";
BA_ "SPN" SG_ 1514 P26_PCU_D_ESCTorqueLimit 2933;
BA_ "SPN" SG_ 1514 P26_PCU_S_ESCTorqueLimitActiveSt 2922;
BA_ "SystemSignalLongSymbol" SG_ 1514 P26_PCU_S_ESCTorqueLimitActiveSt "P26_PCU_S_ESCTorqueLimitActiveState";
BA_ "SPN" SG_ 1514 P26_PCU_S_DriveProcessorTempDera 2924;
BA_ "SystemSignalLongSymbol" SG_ 1514 P26_PCU_S_DriveProcessorTempDera "P26_PCU_S_DriveProcessorTempDerateState";
BA_ "SPN" SG_ 1514 P26_PCU_S_DriveMotorDerateState 2926;
BA_ "SPN" SG_ 1514 P26_PCU_S_DriveMCUDerateState 2925;
BA_ "SPN" SG_ 1514 P26_PCU_S_DriveLVVoltageDerateSt 2923;
BA_ "SystemSignalLongSymbol" SG_ 1514 P26_PCU_S_DriveLVVoltageDerateSt "P26_PCU_S_DriveLVVoltageDerateState";
BA_ "SPN" SG_ 1514 P26_PCU_S_DriveBatteryDerateStat 2927;
BA_ "SystemSignalLongSymbol" SG_ 1514 P26_PCU_S_DriveBatteryDerateStat "P26_PCU_S_DriveBatteryDerateState";
BA_ "SPN" SG_ 1514 P26_PCU_S_DriveSOCDerateState 2928;
BA_ "SPN" SG_ 1514 P26_PCU_S_TCSPermissionState 2432;
BA_ "SPN" SG_ 1514 P26_PCU_S_DrivePermissionState 2433;
BA_ "SPN" SG_ 1514 P26_PCU_S_CreepPermissionState 2434;
BA_ "SPN" SG_ 1514 P26_PCU_S_CruisePermissionState 2435;
BA_ "SPN" SG_ 1514 P26_PCU_S_RetardPermissionState 2437;
BA_ "SPN" SG_ 1514 P26_PCU_S_DriveDerateState 2438;
BA_ "SPN" SG_ 1514 P26_PCU_S_RegenDerateState 2439;
BA_ "SPN" SG_ 1514 P26_PCU_D_MotorMaxPower 2441;
BA_ "SPN" SG_ 1530 P27_PCU_D_MotorRegenLimitTorque 2442;
BA_ "SPN" SG_ 1530 P27_PCU_D_MotorDriveLimitTorque 2443;
BA_ "SPN" SG_ 1530 P27_PCU_D_MotorDriveMaxTorque 2444;
BA_ "SPN" SG_ 1546 P28_PCU_D_MotorRegenMaxTorque 2445;
BA_ "GenSigSendType" SG_ 1546 P28_PCU_D_MotorRegenMaxTorque 0;
BA_ "SPN" SG_ 1546 P28_PCU_D_MotorDriveMinTorque 2446;
BA_ "GenSigSendType" SG_ 1546 P28_PCU_D_MotorDriveMinTorque 0;
BA_ "SPN" SG_ 1546 P28_PCU_D_MotorRegenMinTorque 2447;
BA_ "GenSigSendType" SG_ 1546 P28_PCU_D_MotorRegenMinTorque 0;
BA_ "GenSigSendType" SG_ 1546 P28_PCU_D_Counter 0;
BA_ "GenSigSendType" SG_ 1546 P28_PCU_D_CRC 0;
BA_ "SPN" SG_ 1194 P20_PCU_S_BatteryPackHeatingRequ 2491;
BA_ "SystemSignalLongSymbol" SG_ 1194 P20_PCU_S_BatteryPackHeatingRequ "P20_PCU_S_BatteryPackHeatingRequestState";
BA_ "SPN" SG_ 1194 P20_PCU_S_BatteryPackCoolantTemp 2490;
BA_ "SystemSignalLongSymbol" SG_ 1194 P20_PCU_S_BatteryPackCoolantTemp "P20_PCU_S_BatteryPackCoolantTemperatureSensorSelectState";
BA_ "SPN" SG_ 1194 P20_PCU_S_BatteryPackMinTemperat 2349;
BA_ "SystemSignalLongSymbol" SG_ 1194 P20_PCU_S_BatteryPackMinTemperat "P20_PCU_S_BatteryPackMinTemperatureState";
BA_ "SPN" SG_ 1194 P20_PCU_S_BatteryPackTMSModeStat 2351;
BA_ "SystemSignalLongSymbol" SG_ 1194 P20_PCU_S_BatteryPackTMSModeStat "P20_PCU_S_BatteryPackTMSModeState";
BA_ "SPN" SG_ 1194 P20_PCU_S_BatteryPackCoolan_0000 2350;
BA_ "SystemSignalLongSymbol" SG_ 1194 P20_PCU_S_BatteryPackCoolan_0000 "P20_PCU_S_BatteryPackCoolantTemperatureState";
BA_ "SPN" SG_ 1194 P20_PCU_S_BatteryPackMaxTemperat 2348;
BA_ "SystemSignalLongSymbol" SG_ 1194 P20_PCU_S_BatteryPackMaxTemperat "P20_PCU_S_BatteryPackMaxTemperatureState";
BA_ "SPN" SG_ 1178 P19_PCU_S_DrivingModeState 2489;
BA_ "SPN" SG_ 1178 P19_PCU_S_OBCTemperatureState 2345;
BA_ "SPN" SG_ 1178 P19_PCU_S_EDUDeviceMaximumPumpRe 2347;
BA_ "SystemSignalLongSymbol" SG_ 1178 P19_PCU_S_EDUDeviceMaximumPumpRe "P19_PCU_S_EDUDeviceMaximumPumpRequest";
BA_ "SPN" SG_ 1178 P19_PCU_S_EDUTMSModeState 2346;
BA_ "SPN" SG_ 1178 P19_PCU_S_MCUTemperatureState 2343;
BA_ "SPN" SG_ 1162 P18_PCU_S_MotorTemperatureState 2341;
BA_ "SPN" SG_ 1162 P18_PCU_S_DCDCTemperatureState 2342;
BA_ "SPN" SG_ 1162 P18_PCU_S_CabinTMSModeState 2340;
BA_ "SPN" SG_ 1162 P18_PCU_S_CabinCoolerValveComman 2339;
BA_ "SystemSignalLongSymbol" SG_ 1162 P18_PCU_S_CabinCoolerValveComman "P18_PCU_S_CabinCoolerValveCommand";
BA_ "SPN" SG_ 1162 P18_PCU_S_BatteryPackHeaterEnabl 2337;
BA_ "SystemSignalLongSymbol" SG_ 1162 P18_PCU_S_BatteryPackHeaterEnabl "P18_PCU_S_BatteryPackHeaterEnableCommand";
BA_ "SPN" SG_ 1162 P18_PCU_S_BatteryChillerValveCom 2338;
BA_ "SystemSignalLongSymbol" SG_ 1162 P18_PCU_S_BatteryChillerValveCom "P18_PCU_S_BatteryChillerValveCommand";
BA_ "SPN" SG_ 1146 P17_PCU_D_EDUWaterPumpSetpoint 2333;
BA_ "SPN" SG_ 1146 P17_PCU_S_FanCommandState 2331;
BA_ "SPN" SG_ 1146 P17_PCU_D_CoolerCompressorSpeedS 2334;
BA_ "SystemSignalLongSymbol" SG_ 1146 P17_PCU_D_CoolerCompressorSpeedS "P17_PCU_D_CoolerCompressorSpeedSetpoint";
BA_ "SPN" SG_ 1146 P17_PCU_D_CabinHeaterPowerSetpoi 2335;
BA_ "SystemSignalLongSymbol" SG_ 1146 P17_PCU_D_CabinHeaterPowerSetpoi "P17_PCU_D_CabinHeaterPowerSetpoint";
BA_ "SPN" SG_ 1146 P17_PCU_D_BatteryPackWaterPumpSe 2332;
BA_ "SystemSignalLongSymbol" SG_ 1146 P17_PCU_D_BatteryPackWaterPumpSe "P17_PCU_D_BatteryPackWaterPumpSetpoint";
BA_ "SPN" SG_ 1146 P17_PCU_D_BatteryPackHeaterTempe 2336;
BA_ "SystemSignalLongSymbol" SG_ 1146 P17_PCU_D_BatteryPackHeaterTempe "P17_PCU_D_BatteryPackHeaterTemperatureSetpoint";
BA_ "SPN" SG_ 1130 P25_PCU_D_CCL 2389;
BA_ "SPN" SG_ 1130 P25_PCU_D_DCL 2390;
BA_ "SPN" SG_ 1130 P25_PCU_D_CoolerCompressorSpeedF 2391;
BA_ "SystemSignalLongSymbol" SG_ 1130 P25_PCU_D_CoolerCompressorSpeedF "P25_PCU_D_CoolerCompressorSpeedFeedback";
BA_ "SPN" SG_ 1114 P24_PCU_D_AirConditionerRequest 2385;
BA_ "SPN" SG_ 1114 P24_PCU_F_OBCOverTemperatureFaul 2384;
BA_ "SystemSignalLongSymbol" SG_ 1114 P24_PCU_F_OBCOverTemperatureFaul "P24_PCU_F_OBCOverTemperatureFault";
BA_ "SPN" SG_ 1114 P24_PCU_F_MotorOverTemperatureWa 2378;
BA_ "SystemSignalLongSymbol" SG_ 1114 P24_PCU_F_MotorOverTemperatureWa "P24_PCU_F_MotorOverTemperatureWarning";
BA_ "SPN" SG_ 1114 P24_PCU_F_MotorOverTemperatureFa 2379;
BA_ "SystemSignalLongSymbol" SG_ 1114 P24_PCU_F_MotorOverTemperatureFa "P24_PCU_F_MotorOverTemperatureFault";
BA_ "SPN" SG_ 1114 P24_PCU_F_MCUOverTemperatureWarn 2380;
BA_ "SystemSignalLongSymbol" SG_ 1114 P24_PCU_F_MCUOverTemperatureWarn "P24_PCU_F_MCUOverTemperatureWarning";
BA_ "SPN" SG_ 1114 P24_PCU_F_MCUOverTemperatureFaul 2381;
BA_ "SystemSignalLongSymbol" SG_ 1114 P24_PCU_F_MCUOverTemperatureFaul "P24_PCU_F_MCUOverTemperatureFault";
BA_ "SPN" SG_ 1114 P24_PCU_F_DCDCOverTemperatureFau 2377;
BA_ "SystemSignalLongSymbol" SG_ 1114 P24_PCU_F_DCDCOverTemperatureFau "P24_PCU_F_DCDCOverTemperatureFault";
BA_ "SPN" SG_ 1114 P24_PCU_F_BMSUnderTemperatureFau 2382;
BA_ "SystemSignalLongSymbol" SG_ 1114 P24_PCU_F_BMSUnderTemperatureFau "P24_PCU_F_BMSUnderTemperatureFault";
BA_ "SPN" SG_ 1114 P24_PCU_F_BMSOverTemperatureFaul 2383;
BA_ "SystemSignalLongSymbol" SG_ 1114 P24_PCU_F_BMSOverTemperatureFaul "P24_PCU_F_BMSOverTemperatureFault";
BA_ "SPN" SG_ 1114 P24_PCU_D_CabinWarmingPercent 2387;
BA_ "SPN" SG_ 1114 P24_PCU_D_CabinCoolingPercent 2386;
BA_ "SPN" SG_ 1114 P24_PCU_S_BlowerFanSelectorState 2388;
BA_ "GenSigStartValue" SG_ 1098 P23_PCU_D_DCDCTemperature 40;
BA_ "SPN" SG_ 1098 P23_PCU_D_DCDCTemperature 2372;
BA_ "GenSigStartValue" SG_ 1098 P23_PCU_D_EDUCoolantTemperature 40;
BA_ "SPN" SG_ 1098 P23_PCU_D_EDUCoolantTemperature 2373;
BA_ "GenSigStartValue" SG_ 1098 P23_PCU_D_CabinHeaterTemperature 40;
BA_ "SPN" SG_ 1098 P23_PCU_D_CabinHeaterTemperature 2375;
BA_ "GenSigStartValue" SG_ 1098 P23_PCU_D_BatteryPackCoolantTemp 40;
BA_ "SPN" SG_ 1098 P23_PCU_D_BatteryPackCoolantTemp 2376;
BA_ "SystemSignalLongSymbol" SG_ 1098 P23_PCU_D_BatteryPackCoolantTemp "P23_PCU_D_BatteryPackCoolantTemperature";
BA_ "GenSigStartValue" SG_ 1098 P23_PCU_D_BatteryPackHeaterTempe 40;
BA_ "SPN" SG_ 1098 P23_PCU_D_BatteryPackHeaterTempe 2374;
BA_ "SystemSignalLongSymbol" SG_ 1098 P23_PCU_D_BatteryPackHeaterTempe "P23_PCU_D_BatteryPackHeaterTemperature";
BA_ "GenSigStartValue" SG_ 1498 P22_PCU_D_OBCTemperature 40;
BA_ "SPN" SG_ 1498 P22_PCU_D_OBCTemperature 2369;
BA_ "GenSigStartValue" SG_ 1498 P22_PCU_D_MotorTemperature 40;
BA_ "SPN" SG_ 1498 P22_PCU_D_MotorTemperature 2371;
BA_ "GenSigStartValue" SG_ 1498 P22_PCU_D_MCUTemperature 40;
BA_ "SPN" SG_ 1498 P22_PCU_D_MCUTemperature 2370;
BA_ "GenSigStartValue" SG_ 1498 P22_PCU_D_BMSLowestTemperature 40;
BA_ "SPN" SG_ 1498 P22_PCU_D_BMSLowestTemperature 2367;
BA_ "GenSigStartValue" SG_ 1498 P22_PCU_D_BMSMeanTemperature 40;
BA_ "SPN" SG_ 1498 P22_PCU_D_BMSMeanTemperature 2368;
BA_ "GenSigStartValue" SG_ 1498 P22_PCU_D_BMSHighestTemperature 40;
BA_ "SPN" SG_ 1498 P22_PCU_D_BMSHighestTemperature 2366;
BA_ "SPN" SG_ 1482 P21_PCU_S_OBCReadyToWorkState 2357;
BA_ "SPN" SG_ 1482 P21_PCU_S_MotorReadyToWorkState 2359;
BA_ "SPN" SG_ 1482 P21_PCU_S_EDUWaterPumpReadyToWor 2353;
BA_ "SystemSignalLongSymbol" SG_ 1482 P21_PCU_S_EDUWaterPumpReadyToWor "P21_PCU_S_EDUWaterPumpReadyToWorkState";
BA_ "SPN" SG_ 1482 P21_PCU_S_DCDCReadyToWorkState 2358;
BA_ "SPN" SG_ 1482 P21_PCU_S_CoolerCompressorReadyT 2361;
BA_ "SystemSignalLongSymbol" SG_ 1482 P21_PCU_S_CoolerCompressorReadyT "P21_PCU_S_CoolerCompressorReadyToWorkState";
BA_ "SPN" SG_ 1482 P21_PCU_S_CabinHeaterReadyToWork 2362;
BA_ "SystemSignalLongSymbol" SG_ 1482 P21_PCU_S_CabinHeaterReadyToWork "P21_PCU_S_CabinHeaterReadyToWorkState";
BA_ "SPN" SG_ 1482 P21_PCU_S_CabinCoolerValveReadyT 2356;
BA_ "SystemSignalLongSymbol" SG_ 1482 P21_PCU_S_CabinCoolerValveReadyT "P21_PCU_S_CabinCoolerValveReadyToWorkState";
BA_ "SPN" SG_ 1482 P21_PCU_S_BatteryPackWaterPumpRe 2354;
BA_ "SystemSignalLongSymbol" SG_ 1482 P21_PCU_S_BatteryPackWaterPumpRe "P21_PCU_S_BatteryPackWaterPumpReadyToWorkState";
BA_ "SPN" SG_ 1482 P21_PCU_S_BMSReadyToWorkState 2352;
BA_ "SPN" SG_ 1482 P21_PCU_S_BatteryPackHeaterReady 2360;
BA_ "SystemSignalLongSymbol" SG_ 1482 P21_PCU_S_BatteryPackHeaterReady "P21_PCU_S_BatteryPackHeaterReadyToWork";
BA_ "SPN" SG_ 1482 P21_PCU_S_BatteryChillerValveRea 2355;
BA_ "SystemSignalLongSymbol" SG_ 1482 P21_PCU_S_BatteryChillerValveRea "P21_PCU_S_BatteryChillerValveReadyToWorkState";
BA_ "SPN" SG_ 1482 P21_PCU_S_OBCModeState 2365;
BA_ "SPN" SG_ 1482 P21_PCU_S_FastChargeModeState 2364;
BA_ "SPN" SG_ 1482 P21_PCU_S_BMSModeState 2363;
BA_ "Priority" SG_ 1274 P16_PCU_F_TMSBatteryPackTemperat 1;
BA_ "SPN" SG_ 1274 P16_PCU_F_TMSBatteryPackTemperat 2981;
BA_ "FaultAction" SG_ 1274 P16_PCU_F_TMSBatteryPackTemperat "Check cooling system";
BA_ "FaultEffect" SG_ 1274 P16_PCU_F_TMSBatteryPackTemperat "vehicle stop";
BA_ "FaultTrigger" SG_ 1274 P16_PCU_F_TMSBatteryPackTemperat "Temperature Increases above 150C";
BA_ "FaultZone" SG_ 1274 P16_PCU_F_TMSBatteryPackTemperat "thermal management system";
BA_ "SystemSignalLongSymbol" SG_ 1274 P16_PCU_F_TMSBatteryPackTemperat "P16_PCU_F_TMSBatteryPackTemperatureSensorFault";
BA_ "Priority" SG_ 1274 P16_PCU_F_EDUWaterPumpNoLoadingF 2;
BA_ "SPN" SG_ 1274 P16_PCU_F_EDUWaterPumpNoLoadingF 2966;
BA_ "SystemSignalLongSymbol" SG_ 1274 P16_PCU_F_EDUWaterPumpNoLoadingF "P16_PCU_F_EDUWaterPumpNoLoadingFault";
BA_ "Priority" SG_ 1274 P16_PCU_F_BatteryPackWaterPumpNo 2;
BA_ "SPN" SG_ 1274 P16_PCU_F_BatteryPackWaterPumpNo 2967;
BA_ "SystemSignalLongSymbol" SG_ 1274 P16_PCU_F_BatteryPackWaterPumpNo "P16_PCU_F_BatteryPackWaterPumpNoLoadingFault";
BA_ "Priority" SG_ 1274 P16_PCU_F_TMSCoolingActuatorPowe 2;
BA_ "SPN" SG_ 1274 P16_PCU_F_TMSCoolingActuatorPowe 2950;
BA_ "SystemSignalLongSymbol" SG_ 1274 P16_PCU_F_TMSCoolingActuatorPowe "P16_PCU_F_TMSCoolingActuatorPowerFault";
BA_ "Priority" SG_ 1274 P16_PCU_F_CoolerCompressorHVILFa 1;
BA_ "SPN" SG_ 1274 P16_PCU_F_CoolerCompressorHVILFa 2948;
BA_ "SystemSignalLongSymbol" SG_ 1274 P16_PCU_F_CoolerCompressorHVILFa "P16_PCU_F_CoolerCompressorHVILFault";
BA_ "Priority" SG_ 1274 P16_PCU_F_BatteryPackHeaterHVILF 4;
BA_ "SPN" SG_ 1274 P16_PCU_F_BatteryPackHeaterHVILF 2949;
BA_ "SystemSignalLongSymbol" SG_ 1274 P16_PCU_F_BatteryPackHeaterHVILF "P16_PCU_F_BatteryPackHeaterHVILFault";
BA_ "Priority" SG_ 1274 P16_PCU_F_BothPumpCommunicationF 1;
BA_ "SPN" SG_ 1274 P16_PCU_F_BothPumpCommunicationF 2905;
BA_ "SystemSignalLongSymbol" SG_ 1274 P16_PCU_F_BothPumpCommunicationF "P16_PCU_F_BothPumpCommunicationFault";
BA_ "FaultZone" SG_ 1274 P16_PCU_F_BatteryPackHeaterOverC "battery heater";
BA_ "FaultAction" SG_ 1274 P16_PCU_F_BatteryPackHeaterOverC "Check heater module";
BA_ "Priority" SG_ 1274 P16_PCU_F_BatteryPackHeaterOverC 2;
BA_ "SPN" SG_ 1274 P16_PCU_F_BatteryPackHeaterOverC 2903;
BA_ "SystemSignalLongSymbol" SG_ 1274 P16_PCU_F_BatteryPackHeaterOverC "P16_PCU_F_BatteryPackHeaterOverCurrentFault";
BA_ "Priority" SG_ 1274 P16_PCU_F_TMSOBCShutdownFault 2;
BA_ "SPN" SG_ 1274 P16_PCU_F_TMSOBCShutdownFault 2525;
BA_ "FaultZone" SG_ 1274 P16_PCU_F_TMSOBCShutdownFault "thermal management system";
BA_ "FaultAction" SG_ 1274 P16_PCU_F_TMSOBCShutdownFault "Check cooling system";
BA_ "FaultTrigger" SG_ 1274 P16_PCU_F_TMSOBCShutdownFault "Temperature Increases above 85C";
BA_ "FaultEffect" SG_ 1274 P16_PCU_F_TMSOBCShutdownFault "OBC disable";
BA_ "Priority" SG_ 1274 P16_PCU_F_TMSMotorShutdownFault 4;
BA_ "SPN" SG_ 1274 P16_PCU_F_TMSMotorShutdownFault 2528;
BA_ "FaultZone" SG_ 1274 P16_PCU_F_TMSMotorShutdownFault "thermal management system";
BA_ "FaultAction" SG_ 1274 P16_PCU_F_TMSMotorShutdownFault "Check cooling system";
BA_ "FaultTrigger" SG_ 1274 P16_PCU_F_TMSMotorShutdownFault "Temperature Increases above 150C";
BA_ "FaultEffect" SG_ 1274 P16_PCU_F_TMSMotorShutdownFault "vehicle stop";
BA_ "Priority" SG_ 1274 P16_PCU_F_TMSMCUShutdownFault 4;
BA_ "SPN" SG_ 1274 P16_PCU_F_TMSMCUShutdownFault 2527;
BA_ "FaultZone" SG_ 1274 P16_PCU_F_TMSMCUShutdownFault "thermal management system";
BA_ "FaultAction" SG_ 1274 P16_PCU_F_TMSMCUShutdownFault "Check cooling system";
BA_ "FaultTrigger" SG_ 1274 P16_PCU_F_TMSMCUShutdownFault "Temperature Increases above 95C";
BA_ "FaultEffect" SG_ 1274 P16_PCU_F_TMSMCUShutdownFault "vehicle stop";
BA_ "Priority" SG_ 1274 P16_PCU_F_TMSDCDCShutdownFault 3;
BA_ "SPN" SG_ 1274 P16_PCU_F_TMSDCDCShutdownFault 2526;
BA_ "FaultZone" SG_ 1274 P16_PCU_F_TMSDCDCShutdownFault "thermal management system";
BA_ "FaultAction" SG_ 1274 P16_PCU_F_TMSDCDCShutdownFault "Check cooling system";
BA_ "FaultTrigger" SG_ 1274 P16_PCU_F_TMSDCDCShutdownFault "Temperature Increases above 95C";
BA_ "FaultEffect" SG_ 1274 P16_PCU_F_TMSDCDCShutdownFault "DCDC disable and speed limit to 80km/h";
BA_ "FaultTrigger" SG_ 1274 P16_PCU_F_CoolerCompressorOverCu "Compare compressor current with a threshold";
BA_ "FaultAction" SG_ 1274 P16_PCU_F_CoolerCompressorOverCu "1- Check CC Wires



2- Check CC piping";
BA_ "FaultEffect" SG_ 1274 P16_PCU_F_CoolerCompressorOverCu "Cooling compressor disable";
BA_ "FaultZone" SG_ 1274 P16_PCU_F_CoolerCompressorOverCu "Cooler Compressor";
BA_ "Priority" SG_ 1274 P16_PCU_F_CoolerCompressorOverCu 1;
BA_ "SPN" SG_ 1274 P16_PCU_F_CoolerCompressorOverCu 2524;
BA_ "SystemSignalLongSymbol" SG_ 1274 P16_PCU_F_CoolerCompressorOverCu "P16_PCU_F_CoolerCompressorOverCurrentFault";
BA_ "Priority" SG_ 1274 P16_PCU_F_AirConditionerKeyMisma 1;
BA_ "SPN" SG_ 1274 P16_PCU_F_AirConditionerKeyMisma 2431;
BA_ "FaultZone" SG_ 1274 P16_PCU_F_AirConditionerKeyMisma "HVAC pannel";
BA_ "FaultEffect" SG_ 1274 P16_PCU_F_AirConditionerKeyMisma "Publish on CAN";
BA_ "FaultAction" SG_ 1274 P16_PCU_F_AirConditionerKeyMisma "1- Check  Wire



2- Check  Module";
BA_ "FaultTrigger" SG_ 1274 P16_PCU_F_AirConditionerKeyMisma "Check Fan status and AC key state";
BA_ "SystemSignalLongSymbol" SG_ 1274 P16_PCU_F_AirConditionerKeyMisma "P16_PCU_F_AirConditionerKeyMismatchFault";
BA_ "Priority" SG_ 1274 P16_PCU_F_EDUCoolantTemperatureS 1;
BA_ "SPN" SG_ 1274 P16_PCU_F_EDUCoolantTemperatureS 2430;
BA_ "FaultZone" SG_ 1274 P16_PCU_F_EDUCoolantTemperatureS "HPU cooling system";
BA_ "FaultEffect" SG_ 1274 P16_PCU_F_EDUCoolantTemperatureS "Publish on CAN";
BA_ "FaultAction" SG_ 1274 P16_PCU_F_EDUCoolantTemperatureS "Check HPU cooling system";
BA_ "FaultTrigger" SG_ 1274 P16_PCU_F_EDUCoolantTemperatureS "Check ADC range within [310 4090]";
BA_ "SystemSignalLongSymbol" SG_ 1274 P16_PCU_F_EDUCoolantTemperatureS "P16_PCU_F_EDUCoolantTemperatureSensorFault";
BA_ "Priority" SG_ 1274 P16_PCU_F_BatteryPackCoolantTemp 1;
BA_ "SPN" SG_ 1274 P16_PCU_F_BatteryPackCoolantTemp 2429;
BA_ "FaultZone" SG_ 1274 P16_PCU_F_BatteryPackCoolantTemp "Battery pack water temperature";
BA_ "FaultEffect" SG_ 1274 P16_PCU_F_BatteryPackCoolantTemp "Publish on CAN";
BA_ "FaultAction" SG_ 1274 P16_PCU_F_BatteryPackCoolantTemp "1- Check  Wire



2- Check  Module";
BA_ "FaultTrigger" SG_ 1274 P16_PCU_F_BatteryPackCoolantTemp "Check ADC range within [310 4090]";
BA_ "SystemSignalLongSymbol" SG_ 1274 P16_PCU_F_BatteryPackCoolantTemp "P16_PCU_F_BatteryPackCoolantTemperatureSensorFault";
BA_ "Priority" SG_ 1274 P16_PCU_F_EDUWaterPumpUpdatePara 2;
BA_ "SPN" SG_ 1274 P16_PCU_F_EDUWaterPumpUpdatePara 2427;
BA_ "FaultAction" SG_ 1274 P16_PCU_F_EDUWaterPumpUpdatePara "check pump";
BA_ "FaultEffect" SG_ 1274 P16_PCU_F_EDUWaterPumpUpdatePara "hpu pump disabled";
BA_ "FaultZone" SG_ 1274 P16_PCU_F_EDUWaterPumpUpdatePara "hpu pump";
BA_ "FaultTrigger" SG_ 1274 P16_PCU_F_EDUWaterPumpUpdatePara "Check CAN Parameter Range";
BA_ "SystemSignalLongSymbol" SG_ 1274 P16_PCU_F_EDUWaterPumpUpdatePara "P16_PCU_F_EDUWaterPumpUpdateParameterFault";
BA_ "Priority" SG_ 1274 P16_PCU_F_BatteryPackWaterPumpUp 2;
BA_ "SPN" SG_ 1274 P16_PCU_F_BatteryPackWaterPumpUp 2428;
BA_ "FaultAction" SG_ 1274 P16_PCU_F_BatteryPackWaterPumpUp "check pump";
BA_ "FaultZone" SG_ 1274 P16_PCU_F_BatteryPackWaterPumpUp "battery pack pump";
BA_ "FaultEffect" SG_ 1274 P16_PCU_F_BatteryPackWaterPumpUp "battery pack pump disabled";
BA_ "FaultTrigger" SG_ 1274 P16_PCU_F_BatteryPackWaterPumpUp "Check CAN Parameter Range";
BA_ "SystemSignalLongSymbol" SG_ 1274 P16_PCU_F_BatteryPackWaterPumpUp "P16_PCU_F_BatteryPackWaterPumpUpdateParameterFault";
BA_ "FaultTrigger" SG_ 1274 P16_PCU_F_BatteryPackHeaterHighV "Compare HV With Battery Pack Voltage";
BA_ "FaultAction" SG_ 1274 P16_PCU_F_BatteryPackHeaterHighV "1- Check battery heater HV Wires";
BA_ "FaultEffect" SG_ 1274 P16_PCU_F_BatteryPackHeaterHighV "Batetry heating disable";
BA_ "FaultZone" SG_ 1274 P16_PCU_F_BatteryPackHeaterHighV "battery heater";
BA_ "Priority" SG_ 1274 P16_PCU_F_BatteryPackHeaterHighV 2;
BA_ "SPN" SG_ 1274 P16_PCU_F_BatteryPackHeaterHighV 2426;
BA_ "SystemSignalLongSymbol" SG_ 1274 P16_PCU_F_BatteryPackHeaterHighV "P16_PCU_F_BatteryPackHeaterHighVoltageFault";
BA_ "FaultTrigger" SG_ 1274 P16_PCU_F_BatteryPackHeaterPower "Check power when request is bigger than zero";
BA_ "FaultAction" SG_ 1274 P16_PCU_F_BatteryPackHeaterPower "1- Check battery heater Connection";
BA_ "FaultEffect" SG_ 1274 P16_PCU_F_BatteryPackHeaterPower "Batetry heating disable";
BA_ "FaultZone" SG_ 1274 P16_PCU_F_BatteryPackHeaterPower "battery heater";
BA_ "Priority" SG_ 1274 P16_PCU_F_BatteryPackHeaterPower 2;
BA_ "SPN" SG_ 1274 P16_PCU_F_BatteryPackHeaterPower 2425;
BA_ "SystemSignalLongSymbol" SG_ 1274 P16_PCU_F_BatteryPackHeaterPower "P16_PCU_F_BatteryPackHeaterPowerUpFault";
BA_ "FaultTrigger" SG_ 1274 P16_PCU_F_BatteryPackHeaterShort "Check power when request is zero";
BA_ "FaultAction" SG_ 1274 P16_PCU_F_BatteryPackHeaterShort "1- Check battery heater Connection";
BA_ "FaultEffect" SG_ 1274 P16_PCU_F_BatteryPackHeaterShort "Batetry heating disable";
BA_ "FaultZone" SG_ 1274 P16_PCU_F_BatteryPackHeaterShort "battery heater";
BA_ "Priority" SG_ 1274 P16_PCU_F_BatteryPackHeaterShort 2;
BA_ "SPN" SG_ 1274 P16_PCU_F_BatteryPackHeaterShort 2424;
BA_ "SystemSignalLongSymbol" SG_ 1274 P16_PCU_F_BatteryPackHeaterShort "P16_PCU_F_BatteryPackHeaterShortCircuitFault";
BA_ "FaultTrigger" SG_ 1274 P16_PCU_F_CabinHeaterHighVoltage "Compare HV with battery pack voltage";
BA_ "FaultAction" SG_ 1274 P16_PCU_F_CabinHeaterHighVoltage "1- Check air heater HV Wires";
BA_ "FaultEffect" SG_ 1274 P16_PCU_F_CabinHeaterHighVoltage "Cabin heating disable";
BA_ "FaultZone" SG_ 1274 P16_PCU_F_CabinHeaterHighVoltage "Air heater";
BA_ "Priority" SG_ 1274 P16_PCU_F_CabinHeaterHighVoltage 2;
BA_ "SPN" SG_ 1274 P16_PCU_F_CabinHeaterHighVoltage 2423;
BA_ "SystemSignalLongSymbol" SG_ 1274 P16_PCU_F_CabinHeaterHighVoltage "P16_PCU_F_CabinHeaterHighVoltageFault";
BA_ "FaultTrigger" SG_ 1274 P16_PCU_F_CabinHeaterPowerUpFaul "Check power when request is bigger than zero";
BA_ "FaultAction" SG_ 1274 P16_PCU_F_CabinHeaterPowerUpFaul "1- Check air heater Connection";
BA_ "FaultEffect" SG_ 1274 P16_PCU_F_CabinHeaterPowerUpFaul "Cabin heating disable";
BA_ "FaultZone" SG_ 1274 P16_PCU_F_CabinHeaterPowerUpFaul "Air heater";
BA_ "Priority" SG_ 1274 P16_PCU_F_CabinHeaterPowerUpFaul 2;
BA_ "SPN" SG_ 1274 P16_PCU_F_CabinHeaterPowerUpFaul 2422;
BA_ "SystemSignalLongSymbol" SG_ 1274 P16_PCU_F_CabinHeaterPowerUpFaul "P16_PCU_F_CabinHeaterPowerUpFault";
BA_ "FaultTrigger" SG_ 1274 P16_PCU_F_CabinHeaterShortCircui "Check power when request is zero";
BA_ "FaultAction" SG_ 1274 P16_PCU_F_CabinHeaterShortCircui "1- Check air heater Connection";
BA_ "FaultEffect" SG_ 1274 P16_PCU_F_CabinHeaterShortCircui "Cabin heating disable";
BA_ "FaultZone" SG_ 1274 P16_PCU_F_CabinHeaterShortCircui "Air heater";
BA_ "Priority" SG_ 1274 P16_PCU_F_CabinHeaterShortCircui 2;
BA_ "SPN" SG_ 1274 P16_PCU_F_CabinHeaterShortCircui 2421;
BA_ "SystemSignalLongSymbol" SG_ 1274 P16_PCU_F_CabinHeaterShortCircui "P16_PCU_F_CabinHeaterShortCircuitFault";
BA_ "FaultTrigger" SG_ 1274 P16_PCU_F_CoolerCompressorHighVo "Compare HV with battery pack voltage";
BA_ "FaultAction" SG_ 1274 P16_PCU_F_CoolerCompressorHighVo "1- Check CC HV Wires";
BA_ "FaultEffect" SG_ 1274 P16_PCU_F_CoolerCompressorHighVo "Cooling compressor disable";
BA_ "FaultZone" SG_ 1274 P16_PCU_F_CoolerCompressorHighVo "Cooler Compressor";
BA_ "Priority" SG_ 1274 P16_PCU_F_CoolerCompressorHighVo 1;
BA_ "SPN" SG_ 1274 P16_PCU_F_CoolerCompressorHighVo 2420;
BA_ "SystemSignalLongSymbol" SG_ 1274 P16_PCU_F_CoolerCompressorHighVo "P16_PCU_F_CoolerCompressorHighVoltageFault";
BA_ "Priority" SG_ 1274 P16_PCU_F_EDUWaterPumpInternalFa 2;
BA_ "SPN" SG_ 1274 P16_PCU_F_EDUWaterPumpInternalFa 2327;
BA_ "FaultEffect" SG_ 1274 P16_PCU_F_EDUWaterPumpInternalFa "hpu pump disabled";
BA_ "FaultZone" SG_ 1274 P16_PCU_F_EDUWaterPumpInternalFa "hpu pump";
BA_ "FaultAction" SG_ 1274 P16_PCU_F_EDUWaterPumpInternalFa "1- check pump wiring



2- check pump module



3- check pump piping";
BA_ "FaultTrigger" SG_ 1274 P16_PCU_F_EDUWaterPumpInternalFa "Internal Fault";
BA_ "SystemSignalLongSymbol" SG_ 1274 P16_PCU_F_EDUWaterPumpInternalFa "P16_PCU_F_EDUWaterPumpInternalFault";
BA_ "Priority" SG_ 1274 P16_PCU_F_EDUWaterPumpCommunicat 1;
BA_ "SPN" SG_ 1274 P16_PCU_F_EDUWaterPumpCommunicat 2328;
BA_ "FaultTrigger" SG_ 1274 P16_PCU_F_EDUWaterPumpCommunicat "Abnormal CAN Message Cycle Time";
BA_ "FaultAction" SG_ 1274 P16_PCU_F_EDUWaterPumpCommunicat "check pump wiring";
BA_ "FaultEffect" SG_ 1274 P16_PCU_F_EDUWaterPumpCommunicat "hpu pump disabled";
BA_ "FaultZone" SG_ 1274 P16_PCU_F_EDUWaterPumpCommunicat "hpu pump";
BA_ "SystemSignalLongSymbol" SG_ 1274 P16_PCU_F_EDUWaterPumpCommunicat "P16_PCU_F_EDUWaterPumpCommunicationFault";
BA_ "FaultTrigger" SG_ 1274 P16_PCU_F_CoolerCompressorUpdate "Check CAN Parameter Range";
BA_ "FaultAction" SG_ 1274 P16_PCU_F_CoolerCompressorUpdate "1- Check CC Connection";
BA_ "FaultEffect" SG_ 1274 P16_PCU_F_CoolerCompressorUpdate "Cooling compressor disable";
BA_ "FaultZone" SG_ 1274 P16_PCU_F_CoolerCompressorUpdate "Cooler Compressor";
BA_ "Priority" SG_ 1274 P16_PCU_F_CoolerCompressorUpdate 1;
BA_ "SPN" SG_ 1274 P16_PCU_F_CoolerCompressorUpdate 2316;
BA_ "SystemSignalLongSymbol" SG_ 1274 P16_PCU_F_CoolerCompressorUpdate "P16_PCU_F_CoolerCompressorUpdateParameterFault";
BA_ "FaultTrigger" SG_ 1274 P16_PCU_F_CoolerCompressorSpeedF "Check power when request is bigger than zero";
BA_ "FaultAction" SG_ 1274 P16_PCU_F_CoolerCompressorSpeedF "1- Check CC Connection";
BA_ "FaultEffect" SG_ 1274 P16_PCU_F_CoolerCompressorSpeedF "Cooling compressor disable";
BA_ "FaultZone" SG_ 1274 P16_PCU_F_CoolerCompressorSpeedF "Cooler Compressor";
BA_ "Priority" SG_ 1274 P16_PCU_F_CoolerCompressorSpeedF 1;
BA_ "SPN" SG_ 1274 P16_PCU_F_CoolerCompressorSpeedF 2318;
BA_ "SystemSignalLongSymbol" SG_ 1274 P16_PCU_F_CoolerCompressorSpeedF "P16_PCU_F_CoolerCompressorSpeedFault";
BA_ "FaultTrigger" SG_ 1274 P16_PCU_F_CoolerCompressorShortC "Check power when request is zero";
BA_ "FaultAction" SG_ 1274 P16_PCU_F_CoolerCompressorShortC "1- Check CC Connection";
BA_ "FaultEffect" SG_ 1274 P16_PCU_F_CoolerCompressorShortC "Cooling compressor disable";
BA_ "FaultZone" SG_ 1274 P16_PCU_F_CoolerCompressorShortC "Cooler Compressor";
BA_ "Priority" SG_ 1274 P16_PCU_F_CoolerCompressorShortC 1;
BA_ "SPN" SG_ 1274 P16_PCU_F_CoolerCompressorShortC 2317;
BA_ "SystemSignalLongSymbol" SG_ 1274 P16_PCU_F_CoolerCompressorShortC "P16_PCU_F_CoolerCompressorShortCircuitFault";
BA_ "FaultTrigger" SG_ 1274 P16_PCU_F_CoolerCompressorIntern "Internal Fault";
BA_ "FaultAction" SG_ 1274 P16_PCU_F_CoolerCompressorIntern "1- CC Internal Failure";
BA_ "FaultEffect" SG_ 1274 P16_PCU_F_CoolerCompressorIntern "Cooling compressor disable";
BA_ "FaultZone" SG_ 1274 P16_PCU_F_CoolerCompressorIntern "Cooler Compressor";
BA_ "Priority" SG_ 1274 P16_PCU_F_CoolerCompressorIntern 1;
BA_ "SPN" SG_ 1274 P16_PCU_F_CoolerCompressorIntern 2314;
BA_ "SystemSignalLongSymbol" SG_ 1274 P16_PCU_F_CoolerCompressorIntern "P16_PCU_F_CoolerCompressorInternalFault";
BA_ "FaultTrigger" SG_ 1274 P16_PCU_F_CoolerCompressorCommun "Abnormal CAN Message Cycle Time";
BA_ "FaultAction" SG_ 1274 P16_PCU_F_CoolerCompressorCommun "1- Check CC Fuse



2- Check CC Wire



3- Check CC Module";
BA_ "FaultEffect" SG_ 1274 P16_PCU_F_CoolerCompressorCommun "Cooling compressor disable";
BA_ "FaultZone" SG_ 1274 P16_PCU_F_CoolerCompressorCommun "Cooler Compressor";
BA_ "Priority" SG_ 1274 P16_PCU_F_CoolerCompressorCommun 1;
BA_ "SPN" SG_ 1274 P16_PCU_F_CoolerCompressorCommun 2315;
BA_ "SystemSignalLongSymbol" SG_ 1274 P16_PCU_F_CoolerCompressorCommun "P16_PCU_F_CoolerCompressorCommunicationFault";
BA_ "FaultTrigger" SG_ 1274 P16_PCU_F_CabinCoolerValveFault "cabin cooler valve status is opposite to cabin cooler valve command";
BA_ "Priority" SG_ 1274 P16_PCU_F_CabinCoolerValveFault 2;
BA_ "SPN" SG_ 1274 P16_PCU_F_CabinCoolerValveFault 2325;
BA_ "FaultZone" SG_ 1274 P16_PCU_F_CabinCoolerValveFault "Cooler compressor



Cooler valve";
BA_ "FaultEffect" SG_ 1274 P16_PCU_F_CabinCoolerValveFault "Publish on CAN";
BA_ "FaultAction" SG_ 1274 P16_PCU_F_CabinCoolerValveFault "1- check valve



2- check cooler piping



3- check compressor";
BA_ "Priority" SG_ 1274 P16_PCU_F_BatteryPackWaterPumpIn 2;
BA_ "SPN" SG_ 1274 P16_PCU_F_BatteryPackWaterPumpIn 2329;
BA_ "FaultZone" SG_ 1274 P16_PCU_F_BatteryPackWaterPumpIn "battery pack pump";
BA_ "FaultEffect" SG_ 1274 P16_PCU_F_BatteryPackWaterPumpIn "battery pack pump disabled";
BA_ "FaultAction" SG_ 1274 P16_PCU_F_BatteryPackWaterPumpIn "1- check pump wiring



2- check pump module



3- check pump piping";
BA_ "FaultTrigger" SG_ 1274 P16_PCU_F_BatteryPackWaterPumpIn "Internal Fault";
BA_ "SystemSignalLongSymbol" SG_ 1274 P16_PCU_F_BatteryPackWaterPumpIn "P16_PCU_F_BatteryPackWaterPumpInternalFault";
BA_ "SPN" SG_ 1274 P16_PCU_F_BatteryPackWaterPumpCo 2330;
BA_ "FaultAction" SG_ 1274 P16_PCU_F_BatteryPackWaterPumpCo "check pump wiring";
BA_ "FaultZone" SG_ 1274 P16_PCU_F_BatteryPackWaterPumpCo "battery pack pump";
BA_ "FaultEffect" SG_ 1274 P16_PCU_F_BatteryPackWaterPumpCo "battery pack pump disabled";
BA_ "FaultTrigger" SG_ 1274 P16_PCU_F_BatteryPackWaterPumpCo "Abnormal CAN Message Cycle Time";
BA_ "SystemSignalLongSymbol" SG_ 1274 P16_PCU_F_BatteryPackWaterPumpCo "P16_PCU_F_BatteryPackWaterPumpCommunicationFault";
BA_ "FaultTrigger" SG_ 1274 P16_PCU_F_BatteryPackHeaterUpdat "Check CAN Parameter Range";
BA_ "FaultAction" SG_ 1274 P16_PCU_F_BatteryPackHeaterUpdat "1- Check battery heater Connection";
BA_ "FaultEffect" SG_ 1274 P16_PCU_F_BatteryPackHeaterUpdat "Batetry heating disable";
BA_ "FaultZone" SG_ 1274 P16_PCU_F_BatteryPackHeaterUpdat "battery heater";
BA_ "Priority" SG_ 1274 P16_PCU_F_BatteryPackHeaterUpdat 2;
BA_ "SPN" SG_ 1274 P16_PCU_F_BatteryPackHeaterUpdat 2324;
BA_ "SystemSignalLongSymbol" SG_ 1274 P16_PCU_F_BatteryPackHeaterUpdat "P16_PCU_F_BatteryPackHeaterUpdateParameterFault";
BA_ "FaultTrigger" SG_ 1274 P16_PCU_F_BatteryPackHeaterInter "Internal Fault";
BA_ "FaultAction" SG_ 1274 P16_PCU_F_BatteryPackHeaterInter "1- battery heater Internal Failure";
BA_ "FaultEffect" SG_ 1274 P16_PCU_F_BatteryPackHeaterInter "Batetry heating disable";
BA_ "FaultZone" SG_ 1274 P16_PCU_F_BatteryPackHeaterInter "battery heater";
BA_ "Priority" SG_ 1274 P16_PCU_F_BatteryPackHeaterInter 2;
BA_ "SPN" SG_ 1274 P16_PCU_F_BatteryPackHeaterInter 2322;
BA_ "SystemSignalLongSymbol" SG_ 1274 P16_PCU_F_BatteryPackHeaterInter "P16_PCU_F_BatteryPackHeaterInternalFault";
BA_ "FaultTrigger" SG_ 1274 P16_PCU_F_BatteryPackHeaterCommu "Abnormal CAN Message Cycle Time";
BA_ "FaultAction" SG_ 1274 P16_PCU_F_BatteryPackHeaterCommu "1- Check battery heater Fuse



2- Check battery heater Wire



3- Check battery heater Module";
BA_ "FaultEffect" SG_ 1274 P16_PCU_F_BatteryPackHeaterCommu "Batetry heating disable";
BA_ "FaultZone" SG_ 1274 P16_PCU_F_BatteryPackHeaterCommu "battery heater";
BA_ "Priority" SG_ 1274 P16_PCU_F_BatteryPackHeaterCommu 2;
BA_ "SPN" SG_ 1274 P16_PCU_F_BatteryPackHeaterCommu 2323;
BA_ "SystemSignalLongSymbol" SG_ 1274 P16_PCU_F_BatteryPackHeaterCommu "P16_PCU_F_BatteryPackHeaterCommunicationFault";
BA_ "Priority" SG_ 1274 P16_PCU_F_BatteryChillerValveFau 2;
BA_ "SPN" SG_ 1274 P16_PCU_F_BatteryChillerValveFau 2326;
BA_ "FaultZone" SG_ 1274 P16_PCU_F_BatteryChillerValveFau "battery chiller valve";
BA_ "FaultEffect" SG_ 1274 P16_PCU_F_BatteryChillerValveFau "Publish on CAN";
BA_ "FaultAction" SG_ 1274 P16_PCU_F_BatteryChillerValveFau "check battery chiller valve";
BA_ "FaultTrigger" SG_ 1274 P16_PCU_F_BatteryChillerValveFau "batter chiller valve status is opposite to batter chiller valve command";
BA_ "SystemSignalLongSymbol" SG_ 1274 P16_PCU_F_BatteryChillerValveFau "P16_PCU_F_BatteryChillerValveFault";
BA_ "FaultTrigger" SG_ 1274 P16_PCU_F_CabinHeaterUpdateParam "Check CAN Parameter Range";
BA_ "FaultAction" SG_ 1274 P16_PCU_F_CabinHeaterUpdateParam "1- Check air heater Connection";
BA_ "FaultEffect" SG_ 1274 P16_PCU_F_CabinHeaterUpdateParam "Cabin heating disable";
BA_ "FaultZone" SG_ 1274 P16_PCU_F_CabinHeaterUpdateParam "Air heater";
BA_ "Priority" SG_ 1274 P16_PCU_F_CabinHeaterUpdateParam 2;
BA_ "SPN" SG_ 1274 P16_PCU_F_CabinHeaterUpdateParam 2321;
BA_ "SystemSignalLongSymbol" SG_ 1274 P16_PCU_F_CabinHeaterUpdateParam "P16_PCU_F_CabinHeaterUpdateParameterFault";
BA_ "FaultTrigger" SG_ 1274 P16_PCU_F_CabinHeaterInternalFau "Internal Fault";
BA_ "FaultAction" SG_ 1274 P16_PCU_F_CabinHeaterInternalFau "1- Air heater Internal Failure";
BA_ "FaultEffect" SG_ 1274 P16_PCU_F_CabinHeaterInternalFau "Cabin heating disable";
BA_ "FaultZone" SG_ 1274 P16_PCU_F_CabinHeaterInternalFau "Air heater";
BA_ "Priority" SG_ 1274 P16_PCU_F_CabinHeaterInternalFau 2;
BA_ "SPN" SG_ 1274 P16_PCU_F_CabinHeaterInternalFau 2319;
BA_ "SystemSignalLongSymbol" SG_ 1274 P16_PCU_F_CabinHeaterInternalFau "P16_PCU_F_CabinHeaterInternalFault";
BA_ "FaultTrigger" SG_ 1274 P16_PCU_F_CabinHeaterCommunicati "Abnormal CAN Message Cycle Time";
BA_ "FaultEffect" SG_ 1274 P16_PCU_F_CabinHeaterCommunicati "Cabin heating disable";
BA_ "FaultZone" SG_ 1274 P16_PCU_F_CabinHeaterCommunicati "Air heater";
BA_ "FaultAction" SG_ 1274 P16_PCU_F_CabinHeaterCommunicati "1- Check Air heater fuse



2- Check Air heater wire



3- Check Air heater module";
BA_ "Priority" SG_ 1274 P16_PCU_F_CabinHeaterCommunicati 2;
BA_ "SPN" SG_ 1274 P16_PCU_F_CabinHeaterCommunicati 2320;
BA_ "SystemSignalLongSymbol" SG_ 1274 P16_PCU_F_CabinHeaterCommunicati "P16_PCU_F_CabinHeaterCommunicationFault";
BA_ "Priority" SG_ 1258 P15_PCU_F_AirbagSignalFault 1;
BA_ "SPN" SG_ 1258 P15_PCU_F_AirbagSignalFault 2978;
BA_ "FaultAction" SG_ 1258 P15_PCU_F_AirbagSignalFault "Check airbag";
BA_ "FaultEffect" SG_ 1258 P15_PCU_F_AirbagSignalFault "No effect";
BA_ "FaultTrigger" SG_ 1258 P15_PCU_F_AirbagSignalFault "Never triggered";
BA_ "FaultZone" SG_ 1258 P15_PCU_F_AirbagSignalFault "Airbag";
BA_ "Priority" SG_ 1258 P15_PCU_F_AirbagCrashFault 4;
BA_ "SPN" SG_ 1258 P15_PCU_F_AirbagCrashFault 2902;
BA_ "FaultZone" SG_ 1258 P15_PCU_F_AirbagCrashFault "Airbag";
BA_ "FaultEffect" SG_ 1258 P15_PCU_F_AirbagCrashFault "No effect";
BA_ "FaultAction" SG_ 1258 P15_PCU_F_AirbagCrashFault "Check airbag";
BA_ "FaultTrigger" SG_ 1258 P15_PCU_F_AirbagCrashFault "Never triggered";
BA_ "FaultTrigger" SG_ 1258 P15_PCU_F_HMICommunicationFault "Receiveng no CAN data from HMI for a specific period";
BA_ "FaultAction" SG_ 1258 P15_PCU_F_HMICommunicationFault "Check HMI and wiring";
BA_ "FaultEffect" SG_ 1258 P15_PCU_F_HMICommunicationFault "HMI disabled";
BA_ "FaultZone" SG_ 1258 P15_PCU_F_HMICommunicationFault "HMI";
BA_ "Priority" SG_ 1258 P15_PCU_F_HMICommunicationFault 2;
BA_ "SPN" SG_ 1258 P15_PCU_F_HMICommunicationFault 2419;
BA_ "Priority" SG_ 1242 P14_PCU_F_PCUCANTimeoutFault 1;
BA_ "SPN" SG_ 1242 P14_PCU_F_PCUCANTimeoutFault 2982;
BA_ "Priority" SG_ 1242 P14_PCU_F_EVSOCSlowOverLimitFaul 1;
BA_ "SPN" SG_ 1242 P14_PCU_F_EVSOCSlowOverLimitFaul 2979;
BA_ "FaultAction" SG_ 1242 P14_PCU_F_EVSOCSlowOverLimitFaul "Check charge plug wiring";
BA_ "FaultEffect" SG_ 1242 P14_PCU_F_EVSOCSlowOverLimitFaul "No effect";
BA_ "FaultTrigger" SG_ 1242 P14_PCU_F_EVSOCSlowOverLimitFaul "Charge mode is active while charge plug not detected.";
BA_ "FaultZone" SG_ 1242 P14_PCU_F_EVSOCSlowOverLimitFaul "Plug";
BA_ "SystemSignalLongSymbol" SG_ 1242 P14_PCU_F_EVSOCSlowOverLimitFaul "P14_PCU_F_EVSOCSlowOverLimitFault";
BA_ "Priority" SG_ 1242 P14_PCU_F_EVSOCFastOverLimitFaul 1;
BA_ "SPN" SG_ 1242 P14_PCU_F_EVSOCFastOverLimitFaul 2980;
BA_ "FaultAction" SG_ 1242 P14_PCU_F_EVSOCFastOverLimitFaul "Check charge plug wiring";
BA_ "FaultEffect" SG_ 1242 P14_PCU_F_EVSOCFastOverLimitFaul "No effect";
BA_ "FaultTrigger" SG_ 1242 P14_PCU_F_EVSOCFastOverLimitFaul "Charge mode is active while charge plug not detected.";
BA_ "FaultZone" SG_ 1242 P14_PCU_F_EVSOCFastOverLimitFaul "Plug";
BA_ "SystemSignalLongSymbol" SG_ 1242 P14_PCU_F_EVSOCFastOverLimitFaul "P14_PCU_F_EVSOCFastOverLimitFault";
BA_ "FaultTrigger" SG_ 1242 P14_PCU_F_EVPluggingFault "Charge mode is active while charge plug not detected.";
BA_ "FaultAction" SG_ 1242 P14_PCU_F_EVPluggingFault "Check charge plug wiring";
BA_ "FaultEffect" SG_ 1242 P14_PCU_F_EVPluggingFault "No effect";
BA_ "SPN" SG_ 1242 P14_PCU_F_EVPluggingFault 2300;
BA_ "FaultZone" SG_ 1242 P14_PCU_F_EVPluggingFault "Plug";
BA_ "Priority" SG_ 1242 P14_PCU_F_EVHVOpenFault 1;
BA_ "SPN" SG_ 1242 P14_PCU_F_EVHVOpenFault 2953;
BA_ "Priority" SG_ 1242 P14_PCU_F_MCUVINMismatchFault 1;
BA_ "SPN" SG_ 1242 P14_PCU_F_MCUVINMismatchFault 2904;
BA_ "FaultEffect" SG_ 1242 P14_PCU_F_EVAirbagCrashDetectedF "No effect";
BA_ "Priority" SG_ 1242 P14_PCU_F_EVAirbagCrashDetectedF 4;
BA_ "SPN" SG_ 1242 P14_PCU_F_EVAirbagCrashDetectedF 2481;
BA_ "FaultZone" SG_ 1242 P14_PCU_F_EVAirbagCrashDetectedF "Airbag";
BA_ "FaultAction" SG_ 1242 P14_PCU_F_EVAirbagCrashDetectedF "Check airbag";
BA_ "FaultTrigger" SG_ 1242 P14_PCU_F_EVAirbagCrashDetectedF "Never triggered";
BA_ "SystemSignalLongSymbol" SG_ 1242 P14_PCU_F_EVAirbagCrashDetectedF "P14_PCU_F_EVAirbagCrashDetectedFault";
BA_ "FaultEffect" SG_ 1242 P14_PCU_F_EVInPluggedFault "No effect";
BA_ "Priority" SG_ 1242 P14_PCU_F_EVInPluggedFault 1;
BA_ "SPN" SG_ 1242 P14_PCU_F_EVInPluggedFault 2480;
BA_ "FaultAction" SG_ 1242 P14_PCU_F_EVInPluggedFault "check plug wiring";
BA_ "FaultZone" SG_ 1242 P14_PCU_F_EVInPluggedFault "plug";
BA_ "FaultTrigger" SG_ 1242 P14_PCU_F_EVInPluggedFault "EV mode ready and one of slow or charge plug is connected.";
BA_ "FaultTrigger" SG_ 1242 P14_PCU_F_ProcessorMissingClockD "Internal Fault";
BA_ "FaultAction" SG_ 1242 P14_PCU_F_ProcessorMissingClockD "1- Check VCU Module";
BA_ "FaultEffect" SG_ 1242 P14_PCU_F_ProcessorMissingClockD "No effect";
BA_ "FaultZone" SG_ 1242 P14_PCU_F_ProcessorMissingClockD "VCU";
BA_ "Priority" SG_ 1242 P14_PCU_F_ProcessorMissingClockD 1;
BA_ "SPN" SG_ 1242 P14_PCU_F_ProcessorMissingClockD 2418;
BA_ "SystemSignalLongSymbol" SG_ 1242 P14_PCU_F_ProcessorMissingClockD "P14_PCU_F_ProcessorMissingClockDetectionFault";
BA_ "FaultTrigger" SG_ 1242 P14_PCU_F_ProcessorOverTemperatu "V > 110";
BA_ "FaultAction" SG_ 1242 P14_PCU_F_ProcessorOverTemperatu "1- Check VCU Module";
BA_ "FaultEffect" SG_ 1242 P14_PCU_F_ProcessorOverTemperatu "80km/h speed limit";
BA_ "FaultZone" SG_ 1242 P14_PCU_F_ProcessorOverTemperatu "VCU";
BA_ "Priority" SG_ 1242 P14_PCU_F_ProcessorOverTemperatu 1;
BA_ "SPN" SG_ 1242 P14_PCU_F_ProcessorOverTemperatu 2298;
BA_ "SystemSignalLongSymbol" SG_ 1242 P14_PCU_F_ProcessorOverTemperatu "P14_PCU_F_ProcessorOverTemperatureFault";
BA_ "FaultTrigger" SG_ 1242 P14_PCU_F_5VSupplyUnderVoltageFa "V < 3.4";
BA_ "FaultAction" SG_ 1242 P14_PCU_F_5VSupplyUnderVoltageFa "1- Check VCU Wires



2- VCU Internal Failure";
BA_ "FaultEffect" SG_ 1242 P14_PCU_F_5VSupplyUnderVoltageFa "80km/h speed limit";
BA_ "FaultZone" SG_ 1242 P14_PCU_F_5VSupplyUnderVoltageFa "VCU";
BA_ "Priority" SG_ 1242 P14_PCU_F_5VSupplyUnderVoltageFa 4;
BA_ "SPN" SG_ 1242 P14_PCU_F_5VSupplyUnderVoltageFa 2295;
BA_ "SystemSignalLongSymbol" SG_ 1242 P14_PCU_F_5VSupplyUnderVoltageFa "P14_PCU_F_5VSupplyUnderVoltageFault";
BA_ "FaultTrigger" SG_ 1242 P14_PCU_F_5VSupplyOverVoltageFau "V > 6.6";
BA_ "FaultAction" SG_ 1242 P14_PCU_F_5VSupplyOverVoltageFau "1- Check VCU Wires



2- VCU Internal Failure";
BA_ "FaultEffect" SG_ 1242 P14_PCU_F_5VSupplyOverVoltageFau "80km/h speed limit";
BA_ "FaultZone" SG_ 1242 P14_PCU_F_5VSupplyOverVoltageFau "VCU";
BA_ "Priority" SG_ 1242 P14_PCU_F_5VSupplyOverVoltageFau 4;
BA_ "SPN" SG_ 1242 P14_PCU_F_5VSupplyOverVoltageFau 2294;
BA_ "SystemSignalLongSymbol" SG_ 1242 P14_PCU_F_5VSupplyOverVoltageFau "P14_PCU_F_5VSupplyOverVoltageFault";
BA_ "FaultTrigger" SG_ 1242 P14_PCU_F_InputUnderVoltageFault "V < 9.5";
BA_ "FaultAction" SG_ 1242 P14_PCU_F_InputUnderVoltageFault "1- Check 12 Battery



2- Check Battery Fuse



3- Check Battery Wires



4- Check DCDC Fuse



5- DCDC Internal Failure



6- VCU Internal Failure";
BA_ "FaultEffect" SG_ 1242 P14_PCU_F_InputUnderVoltageFault "80km/h speed limit";
BA_ "FaultZone" SG_ 1242 P14_PCU_F_InputUnderVoltageFault "VCU";
BA_ "Priority" SG_ 1242 P14_PCU_F_InputUnderVoltageFault 3;
BA_ "SPN" SG_ 1242 P14_PCU_F_InputUnderVoltageFault 2297;
BA_ "FaultTrigger" SG_ 1242 P14_PCU_F_InputOverVoltageFault "V > 16";
BA_ "FaultAction" SG_ 1242 P14_PCU_F_InputOverVoltageFault "1- DCDC Internal Failure";
BA_ "FaultEffect" SG_ 1242 P14_PCU_F_InputOverVoltageFault "80km/h speed limit";
BA_ "FaultZone" SG_ 1242 P14_PCU_F_InputOverVoltageFault "VCU";
BA_ "Priority" SG_ 1242 P14_PCU_F_InputOverVoltageFault 3;
BA_ "SPN" SG_ 1242 P14_PCU_F_InputOverVoltageFault 2296;
BA_ "FaultTrigger" SG_ 1242 P14_PCU_F_EVStartSwitchFault "start switch is in an ambiguous state none of  (none of acc_input, ig_input and start_input states)";
BA_ "FaultAction" SG_ 1242 P14_PCU_F_EVStartSwitchFault "Check start switch";
BA_ "FaultZone" SG_ 1242 P14_PCU_F_EVStartSwitchFault "start switch";
BA_ "FaultEffect" SG_ 1242 P14_PCU_F_EVStartSwitchFault "No effect";
BA_ "Priority" SG_ 1242 P14_PCU_F_EVStartSwitchFault 1;
BA_ "SPN" SG_ 1242 P14_PCU_F_EVStartSwitchFault 2312;
BA_ "FaultTrigger" SG_ 1242 P14_PCU_F_EVSOCLowFault "Touching low battery soc (2%)";
BA_ "FaultAction" SG_ 1242 P14_PCU_F_EVSOCLowFault "Check battery pack";
BA_ "FaultEffect" SG_ 1242 P14_PCU_F_EVSOCLowFault "No effect";
BA_ "SPN" SG_ 1242 P14_PCU_F_EVSOCLowFault 2305;
BA_ "FaultZone" SG_ 1242 P14_PCU_F_EVSOCLowFault "BMS";
BA_ "FaultTrigger" SG_ 1242 P14_PCU_F_EVSOCLimitFault "Touching high battery soc (100%)";
BA_ "FaultAction" SG_ 1242 P14_PCU_F_EVSOCLimitFault "Check battery pack";
BA_ "FaultEffect" SG_ 1242 P14_PCU_F_EVSOCLimitFault "No effect";
BA_ "SPN" SG_ 1242 P14_PCU_F_EVSOCLimitFault 2306;
BA_ "FaultZone" SG_ 1242 P14_PCU_F_EVSOCLimitFault "BMS";
BA_ "FaultAction" SG_ 1242 P14_PCU_F_EVPrechargeTimeoutFaul "Check motor drive wiring";
BA_ "FaultTrigger" SG_ 1242 P14_PCU_F_EVPrechargeTimeoutFaul "Precharge relay timeout (more than 2s)";
BA_ "FaultEffect" SG_ 1242 P14_PCU_F_EVPrechargeTimeoutFaul "No effect";
BA_ "SPN" SG_ 1242 P14_PCU_F_EVPrechargeTimeoutFaul 2308;
BA_ "FaultZone" SG_ 1242 P14_PCU_F_EVPrechargeTimeoutFaul "MCU";
BA_ "SystemSignalLongSymbol" SG_ 1242 P14_PCU_F_EVPrechargeTimeoutFaul "P14_PCU_F_EVPrechargeTimeoutFault";
BA_ "FaultTrigger" SG_ 1242 P14_PCU_F_EVDCUNotReadyFault "Not ready status from DCU";
BA_ "FaultZone" SG_ 1242 P14_PCU_F_EVDCUNotReadyFault "DCU";
BA_ "FaultAction" SG_ 1242 P14_PCU_F_EVDCUNotReadyFault "Check DCU and wiring";
BA_ "FaultEffect" SG_ 1242 P14_PCU_F_EVDCUNotReadyFault "No effect";
BA_ "SPN" SG_ 1242 P14_PCU_F_EVDCUNotReadyFault 2303;
BA_ "FaultZone" SG_ 1242 P14_PCU_F_EVDCDCNotReadyFault "DCDC";
BA_ "FaultTrigger" SG_ 1242 P14_PCU_F_EVDCDCNotReadyFault "Not ready status from DCDC";
BA_ "FaultAction" SG_ 1242 P14_PCU_F_EVDCDCNotReadyFault "Check DCDC and wiring";
BA_ "FaultEffect" SG_ 1242 P14_PCU_F_EVDCDCNotReadyFault "No effect";
BA_ "SPN" SG_ 1242 P14_PCU_F_EVDCDCNotReadyFault 2304;
BA_ "FaultEffect" SG_ 1242 P14_PCU_F_EVBMSOpenContactorFaul "No effect";
BA_ "Priority" SG_ 1242 P14_PCU_F_EVBMSOpenContactorFaul 1;
BA_ "SPN" SG_ 1242 P14_PCU_F_EVBMSOpenContactorFaul 2313;
BA_ "FaultZone" SG_ 1242 P14_PCU_F_EVBMSOpenContactorFaul "battery pack contactors";
BA_ "FaultAction" SG_ 1242 P14_PCU_F_EVBMSOpenContactorFaul "Check contactors";
BA_ "FaultTrigger" SG_ 1242 P14_PCU_F_EVBMSOpenContactorFaul "In ready EV mode, one of negative or pre-charge contactors is open.";
BA_ "SystemSignalLongSymbol" SG_ 1242 P14_PCU_F_EVBMSOpenContactorFaul "P14_PCU_F_EVBMSOpenContactorFault";
BA_ "FaultEffect" SG_ 1242 P14_PCU_F_EVChargeStopFault "No effect";
BA_ "Priority" SG_ 1242 P14_PCU_F_EVChargeStopFault 1;
BA_ "SPN" SG_ 1242 P14_PCU_F_EVChargeStopFault 2310;
BA_ "FaultTrigger" SG_ 1242 P14_PCU_F_EVBMSNotReadyFault "Not ready status from BMS";
BA_ "FaultAction" SG_ 1242 P14_PCU_F_EVBMSNotReadyFault "Check BMS



Check battery pack wiring";
BA_ "FaultZone" SG_ 1242 P14_PCU_F_EVBMSNotReadyFault "BMS";
BA_ "FaultEffect" SG_ 1242 P14_PCU_F_EVBMSNotReadyFault "No effect";
BA_ "SPN" SG_ 1242 P14_PCU_F_EVBMSNotReadyFault 2302;
BA_ "Priority" SG_ 1226 P13_PCU_F_OBCOverCurrentFault 2;
BA_ "SPN" SG_ 1226 P13_PCU_F_OBCOverCurrentFault 2947;
BA_ "FaultTrigger" SG_ 1226 P13_PCU_F_BMSModeFault "when command from CAN does not comply with command from IO.";
BA_ "FaultEffect" SG_ 1226 P13_PCU_F_BMSModeFault "Publish on CAN";
BA_ "FaultZone" SG_ 1226 P13_PCU_F_BMSModeFault "BMS";
BA_ "Priority" SG_ 1226 P13_PCU_F_BMSModeFault 1;
BA_ "SPN" SG_ 1226 P13_PCU_F_BMSModeFault 2488;
BA_ "FaultTrigger" SG_ 1226 P13_PCU_F_OBCHighVoltageFault "Compare HV with battery pack voltage";
BA_ "FaultAction" SG_ 1226 P13_PCU_F_OBCHighVoltageFault "1- Check obc HV Wires";
BA_ "FaultEffect" SG_ 1226 P13_PCU_F_OBCHighVoltageFault "AC charge Failure";
BA_ "FaultZone" SG_ 1226 P13_PCU_F_OBCHighVoltageFault "OBC";
BA_ "Priority" SG_ 1226 P13_PCU_F_OBCHighVoltageFault 2;
BA_ "SPN" SG_ 1226 P13_PCU_F_OBCHighVoltageFault 2417;
BA_ "FaultTrigger" SG_ 1226 P13_PCU_F_OBCShortCircuitFault "Check power when request is zero";
BA_ "FaultAction" SG_ 1226 P13_PCU_F_OBCShortCircuitFault "1- Check obc Connection";
BA_ "FaultEffect" SG_ 1226 P13_PCU_F_OBCShortCircuitFault "AC charge Failure";
BA_ "FaultZone" SG_ 1226 P13_PCU_F_OBCShortCircuitFault "OBC";
BA_ "Priority" SG_ 1226 P13_PCU_F_OBCShortCircuitFault 2;
BA_ "SPN" SG_ 1226 P13_PCU_F_OBCShortCircuitFault 2416;
BA_ "FaultAction" SG_ 1226 P13_PCU_F_MCUHighVoltageFault "1- Check MCU HV Wires";
BA_ "FaultTrigger" SG_ 1226 P13_PCU_F_MCUHighVoltageFault "Compare HV With Battery Pack Voltage";
BA_ "FaultEffect" SG_ 1226 P13_PCU_F_MCUHighVoltageFault "Power off depended on EV speed";
BA_ "FaultZone" SG_ 1226 P13_PCU_F_MCUHighVoltageFault "MCU";
BA_ "Priority" SG_ 1226 P13_PCU_F_MCUHighVoltageFault 1;
BA_ "SPN" SG_ 1226 P13_PCU_F_MCUHighVoltageFault 2415;
BA_ "FaultTrigger" SG_ 1226 P13_PCU_F_OBCUpdateParameterFaul "Check CAN parameter range";
BA_ "FaultAction" SG_ 1226 P13_PCU_F_OBCUpdateParameterFaul "1- Check obc Connection";
BA_ "FaultEffect" SG_ 1226 P13_PCU_F_OBCUpdateParameterFaul "AC charge Failure";
BA_ "FaultZone" SG_ 1226 P13_PCU_F_OBCUpdateParameterFaul "OBC";
BA_ "Priority" SG_ 1226 P13_PCU_F_OBCUpdateParameterFaul 2;
BA_ "SPN" SG_ 1226 P13_PCU_F_OBCUpdateParameterFaul 2293;
BA_ "SystemSignalLongSymbol" SG_ 1226 P13_PCU_F_OBCUpdateParameterFaul "P13_PCU_F_OBCUpdateParameterFault";
BA_ "FaultTrigger" SG_ 1226 P13_PCU_F_OBCInternalFault "Internal Fault";
BA_ "FaultAction" SG_ 1226 P13_PCU_F_OBCInternalFault "1- OBC internal failure";
BA_ "FaultEffect" SG_ 1226 P13_PCU_F_OBCInternalFault "AC charge Failure";
BA_ "FaultZone" SG_ 1226 P13_PCU_F_OBCInternalFault "OBC";
BA_ "Priority" SG_ 1226 P13_PCU_F_OBCInternalFault 2;
BA_ "SPN" SG_ 1226 P13_PCU_F_OBCInternalFault 2291;
BA_ "FaultTrigger" SG_ 1226 P13_PCU_F_OBCCommunicationFault "Abnormal CAN message cycle time";
BA_ "FaultAction" SG_ 1226 P13_PCU_F_OBCCommunicationFault "1- Check obc  Fuse



2- Check obc  Wire



3- Check obc  Module";
BA_ "FaultEffect" SG_ 1226 P13_PCU_F_OBCCommunicationFault "AC charge Failure";
BA_ "FaultZone" SG_ 1226 P13_PCU_F_OBCCommunicationFault "OBC";
BA_ "Priority" SG_ 1226 P13_PCU_F_OBCCommunicationFault 2;
BA_ "SPN" SG_ 1226 P13_PCU_F_OBCCommunicationFault 2292;
BA_ "FaultTrigger" SG_ 1226 P13_PCU_F_MCUUpdateParameterFaul "Check CAN Parameter Range";
BA_ "FaultAction" SG_ 1226 P13_PCU_F_MCUUpdateParameterFaul "1- Check MCU Connection";
BA_ "FaultEffect" SG_ 1226 P13_PCU_F_MCUUpdateParameterFaul "Power off depended on EV speed";
BA_ "FaultZone" SG_ 1226 P13_PCU_F_MCUUpdateParameterFaul "MCU";
BA_ "Priority" SG_ 1226 P13_PCU_F_MCUUpdateParameterFaul 3;
BA_ "SPN" SG_ 1226 P13_PCU_F_MCUUpdateParameterFaul 2290;
BA_ "SystemSignalLongSymbol" SG_ 1226 P13_PCU_F_MCUUpdateParameterFaul "P13_PCU_F_MCUUpdateParameterFault";
BA_ "FaultTrigger" SG_ 1226 P13_PCU_F_MCUInternalFault "Internal Fault";
BA_ "FaultAction" SG_ 1226 P13_PCU_F_MCUInternalFault "1-  Drive Internal Failure";
BA_ "FaultEffect" SG_ 1226 P13_PCU_F_MCUInternalFault "Power off depended on EV speed";
BA_ "FaultZone" SG_ 1226 P13_PCU_F_MCUInternalFault "MCU";
BA_ "Priority" SG_ 1226 P13_PCU_F_MCUInternalFault 3;
BA_ "SPN" SG_ 1226 P13_PCU_F_MCUInternalFault 2288;
BA_ "FaultTrigger" SG_ 1226 P13_PCU_F_MCUCommunicationFault "Abnormal CAN Message Cycle Time";
BA_ "FaultAction" SG_ 1226 P13_PCU_F_MCUCommunicationFault "1- Check MCU Fuse



2- Check MCU Wire



3- Check MCU Module";
BA_ "FaultEffect" SG_ 1226 P13_PCU_F_MCUCommunicationFault "Power off depended on EV speed";
BA_ "FaultZone" SG_ 1226 P13_PCU_F_MCUCommunicationFault "MCU";
BA_ "Priority" SG_ 1226 P13_PCU_F_MCUCommunicationFault 3;
BA_ "SPN" SG_ 1226 P13_PCU_F_MCUCommunicationFault 2289;
BA_ "FaultTrigger" SG_ 1226 P13_PCU_F_DCDCUpdateParameterFau "Check CAN Parameter Range";
BA_ "FaultAction" SG_ 1226 P13_PCU_F_DCDCUpdateParameterFau "1- Check DCDC Connection";
BA_ "FaultEffect" SG_ 1226 P13_PCU_F_DCDCUpdateParameterFau "dcdc disable and speed limit to 80km/h";
BA_ "FaultZone" SG_ 1226 P13_PCU_F_DCDCUpdateParameterFau "DCDC";
BA_ "Priority" SG_ 1226 P13_PCU_F_DCDCUpdateParameterFau 3;
BA_ "SPN" SG_ 1226 P13_PCU_F_DCDCUpdateParameterFau 2284;
BA_ "SystemSignalLongSymbol" SG_ 1226 P13_PCU_F_DCDCUpdateParameterFau "P13_PCU_F_DCDCUpdateParameterFault";
BA_ "FaultTrigger" SG_ 1226 P13_PCU_F_DCDCOverTemperatureFau "Temperature Bigger Than DCDC Shutdown Temperature";
BA_ "FaultAction" SG_ 1226 P13_PCU_F_DCDCOverTemperatureFau "1- Check DCDC Cooling System



2- Internal Failur";
BA_ "FaultEffect" SG_ 1226 P13_PCU_F_DCDCOverTemperatureFau "dcdc disable and speed limit to 80km/h";
BA_ "FaultZone" SG_ 1226 P13_PCU_F_DCDCOverTemperatureFau "DCDC";
BA_ "Priority" SG_ 1226 P13_PCU_F_DCDCOverTemperatureFau 3;
BA_ "SPN" SG_ 1226 P13_PCU_F_DCDCOverTemperatureFau 2286;
BA_ "SystemSignalLongSymbol" SG_ 1226 P13_PCU_F_DCDCOverTemperatureFau "P13_PCU_F_DCDCOverTemperatureFault";
BA_ "FaultTrigger" SG_ 1226 P13_PCU_F_DCDCLVUnderVoltageFaul "LV Lower Than 9V";
BA_ "FaultAction" SG_ 1226 P13_PCU_F_DCDCLVUnderVoltageFaul "1- Check Battery Voltage



2- Check LV Wires";
BA_ "FaultEffect" SG_ 1226 P13_PCU_F_DCDCLVUnderVoltageFaul "dcdc disable and speed limit to 80km/h";
BA_ "FaultZone" SG_ 1226 P13_PCU_F_DCDCLVUnderVoltageFaul "DCDC";
BA_ "Priority" SG_ 1226 P13_PCU_F_DCDCLVUnderVoltageFaul 3;
BA_ "SPN" SG_ 1226 P13_PCU_F_DCDCLVUnderVoltageFaul 2287;
BA_ "SystemSignalLongSymbol" SG_ 1226 P13_PCU_F_DCDCLVUnderVoltageFaul "P13_PCU_F_DCDCLVUnderVoltageFault";
BA_ "FaultTrigger" SG_ 1226 P13_PCU_F_DCDCInternalFault "Internal Fault";
BA_ "FaultAction" SG_ 1226 P13_PCU_F_DCDCInternalFault "1- DCDC Internal Failure";
BA_ "FaultEffect" SG_ 1226 P13_PCU_F_DCDCInternalFault "dcdc disable and speed limit to 80km/h";
BA_ "FaultZone" SG_ 1226 P13_PCU_F_DCDCInternalFault "DCDC";
BA_ "Priority" SG_ 1226 P13_PCU_F_DCDCInternalFault 3;
BA_ "SPN" SG_ 1226 P13_PCU_F_DCDCInternalFault 2282;
BA_ "FaultTrigger" SG_ 1226 P13_PCU_F_DCDCHighVoltageFault "Compare HV With Battery Pack Voltage";
BA_ "FaultAction" SG_ 1226 P13_PCU_F_DCDCHighVoltageFault "1- Check DCDC HV Wires";
BA_ "FaultEffect" SG_ 1226 P13_PCU_F_DCDCHighVoltageFault "dcdc disable and speed limit to 80km/h";
BA_ "FaultZone" SG_ 1226 P13_PCU_F_DCDCHighVoltageFault "DCDC";
BA_ "Priority" SG_ 1226 P13_PCU_F_DCDCHighVoltageFault 3;
BA_ "SPN" SG_ 1226 P13_PCU_F_DCDCHighVoltageFault 2285;
BA_ "FaultTrigger" SG_ 1226 P13_PCU_F_DCDCCommunicationFault "Abnormal CAN Message Cycle Time";
BA_ "FaultAction" SG_ 1226 P13_PCU_F_DCDCCommunicationFault "1- Check DCDC Fuse



2- Check DCDC LV Wires";
BA_ "FaultEffect" SG_ 1226 P13_PCU_F_DCDCCommunicationFault "dcdc disable and speed limit to 80km/h";
BA_ "FaultZone" SG_ 1226 P13_PCU_F_DCDCCommunicationFault "DCDC";
BA_ "Priority" SG_ 1226 P13_PCU_F_DCDCCommunicationFault 3;
BA_ "SPN" SG_ 1226 P13_PCU_F_DCDCCommunicationFault 2283;
BA_ "FaultTrigger" SG_ 1226 P13_PCU_F_BMSUpdateParameterFaul "Check CAN Parameter Range";
BA_ "FaultAction" SG_ 1226 P13_PCU_F_BMSUpdateParameterFaul "1- Check BMS Connection";
BA_ "FaultEffect" SG_ 1226 P13_PCU_F_BMSUpdateParameterFaul "Publish on CAN";
BA_ "FaultZone" SG_ 1226 P13_PCU_F_BMSUpdateParameterFaul "BMS";
BA_ "Priority" SG_ 1226 P13_PCU_F_BMSUpdateParameterFaul 1;
BA_ "SPN" SG_ 1226 P13_PCU_F_BMSUpdateParameterFaul 2269;
BA_ "SystemSignalLongSymbol" SG_ 1226 P13_PCU_F_BMSUpdateParameterFaul "P13_PCU_F_BMSUpdateParameterFault";
BA_ "FaultTrigger" SG_ 1226 P13_PCU_F_BMSInternalFault "Check BMS Fault";
BA_ "FaultAction" SG_ 1226 P13_PCU_F_BMSInternalFault "1- Check BMS Wires



2- BMS Internal Failure";
BA_ "FaultEffect" SG_ 1226 P13_PCU_F_BMSInternalFault "BMS is disabled";
BA_ "FaultZone" SG_ 1226 P13_PCU_F_BMSInternalFault "BMS";
BA_ "Priority" SG_ 1226 P13_PCU_F_BMSInternalFault 3;
BA_ "SPN" SG_ 1226 P13_PCU_F_BMSInternalFault 2267;
BA_ "FaultTrigger" SG_ 1226 P13_PCU_F_BMSCommunicationFault "Abnormal CAN Message Cycle Time";
BA_ "FaultAction" SG_ 1226 P13_PCU_F_BMSCommunicationFault "1- Check BMS Fuse



2- Check Wires



3- Internal Failure";
BA_ "FaultEffect" SG_ 1226 P13_PCU_F_BMSCommunicationFault "BMS is disabled";
BA_ "FaultZone" SG_ 1226 P13_PCU_F_BMSCommunicationFault "BMS";
BA_ "Priority" SG_ 1226 P13_PCU_F_BMSCommunicationFault 3;
BA_ "SPN" SG_ 1226 P13_PCU_F_BMSCommunicationFault 2268;
BA_ "FaultTrigger" SG_ 1226 P13_PCU_F_NegativeContactorWeldi "contactor is close while VCU expects it to be open and vice versa";
BA_ "FaultAction" SG_ 1226 P13_PCU_F_NegativeContactorWeldi "1- Check K3 Contactor";
BA_ "FaultEffect" SG_ 1226 P13_PCU_F_NegativeContactorWeldi "Power up Failure";
BA_ "FaultZone" SG_ 1226 P13_PCU_F_NegativeContactorWeldi "BMS and PDU";
BA_ "Priority" SG_ 1226 P13_PCU_F_NegativeContactorWeldi 1;
BA_ "SPN" SG_ 1226 P13_PCU_F_NegativeContactorWeldi 2281;
BA_ "SystemSignalLongSymbol" SG_ 1226 P13_PCU_F_NegativeContactorWeldi "P13_PCU_F_NegativeContactorWeldingFault";
BA_ "FaultTrigger" SG_ 1226 P13_PCU_F_NegativeContactorMatch "VCU Contactor Command and BMS Response Incompatible";
BA_ "FaultAction" SG_ 1226 P13_PCU_F_NegativeContactorMatch "1- Check K3 Contactor";
BA_ "FaultEffect" SG_ 1226 P13_PCU_F_NegativeContactorMatch "Power up Failure";
BA_ "FaultZone" SG_ 1226 P13_PCU_F_NegativeContactorMatch "BMS and PDU";
BA_ "Priority" SG_ 1226 P13_PCU_F_NegativeContactorMatch 1;
BA_ "SPN" SG_ 1226 P13_PCU_F_NegativeContactorMatch 2279;
BA_ "SystemSignalLongSymbol" SG_ 1226 P13_PCU_F_NegativeContactorMatch "P13_PCU_F_NegativeContactorMatchingFault";
BA_ "FaultTrigger" SG_ 1226 P13_PCU_F_PositiveContactorWeldi "contactor is close while VCU expects it to be open and vice versa";
BA_ "FaultAction" SG_ 1226 P13_PCU_F_PositiveContactorWeldi "1- Check K2 Contactor";
BA_ "FaultEffect" SG_ 1226 P13_PCU_F_PositiveContactorWeldi "Power up Failure";
BA_ "FaultZone" SG_ 1226 P13_PCU_F_PositiveContactorWeldi "BMS and PDU";
BA_ "Priority" SG_ 1226 P13_PCU_F_PositiveContactorWeldi 1;
BA_ "SPN" SG_ 1226 P13_PCU_F_PositiveContactorWeldi 2277;
BA_ "SystemSignalLongSymbol" SG_ 1226 P13_PCU_F_PositiveContactorWeldi "P13_PCU_F_PositiveContactorWeldingFault";
BA_ "FaultTrigger" SG_ 1226 P13_PCU_F_PositiveContactorMatch "VCU Contactor Command and BMS Response Incompatible";
BA_ "FaultAction" SG_ 1226 P13_PCU_F_PositiveContactorMatch "1- Check K2 Contactor";
BA_ "FaultEffect" SG_ 1226 P13_PCU_F_PositiveContactorMatch "Power up Failure";
BA_ "FaultZone" SG_ 1226 P13_PCU_F_PositiveContactorMatch "BMS and PDU";
BA_ "Priority" SG_ 1226 P13_PCU_F_PositiveContactorMatch 1;
BA_ "SPN" SG_ 1226 P13_PCU_F_PositiveContactorMatch 2275;
BA_ "SystemSignalLongSymbol" SG_ 1226 P13_PCU_F_PositiveContactorMatch "P13_PCU_F_PositiveContactorMatchingFault";
BA_ "FaultTrigger" SG_ 1226 P13_PCU_F_PrechargeContactorWeld "contactor is close while VCU expects it to be open and vice versa";
BA_ "FaultAction" SG_ 1226 P13_PCU_F_PrechargeContactorWeld "1- Check K1 Contactor";
BA_ "FaultEffect" SG_ 1226 P13_PCU_F_PrechargeContactorWeld "Power up Failure";
BA_ "FaultZone" SG_ 1226 P13_PCU_F_PrechargeContactorWeld "BMS and PDU";
BA_ "Priority" SG_ 1226 P13_PCU_F_PrechargeContactorWeld 1;
BA_ "SPN" SG_ 1226 P13_PCU_F_PrechargeContactorWeld 2273;
BA_ "SystemSignalLongSymbol" SG_ 1226 P13_PCU_F_PrechargeContactorWeld "P13_PCU_F_PrechargeContactorWeldingFault";
BA_ "FaultTrigger" SG_ 1226 P13_PCU_F_PrechargeContactorMatc "VCU Contactor Command and BMS Response Incompatible";
BA_ "FaultAction" SG_ 1226 P13_PCU_F_PrechargeContactorMatc "1- Check K1 Contactor";
BA_ "FaultEffect" SG_ 1226 P13_PCU_F_PrechargeContactorMatc "Power up Failure";
BA_ "FaultZone" SG_ 1226 P13_PCU_F_PrechargeContactorMatc "BMS and PDU";
BA_ "Priority" SG_ 1226 P13_PCU_F_PrechargeContactorMatc 1;
BA_ "SPN" SG_ 1226 P13_PCU_F_PrechargeContactorMatc 2271;
BA_ "SystemSignalLongSymbol" SG_ 1226 P13_PCU_F_PrechargeContactorMatc "P13_PCU_F_PrechargeContactorMatchingFault";
BA_ "Priority" SG_ 1210 P12_PCU_F_VacuumPumpPowerFault 3;
BA_ "SPN" SG_ 1210 P12_PCU_F_VacuumPumpPowerFault 2954;
BA_ "Priority" SG_ 1210 P12_PCU_F_EPSInternalFault 3;
BA_ "SPN" SG_ 1210 P12_PCU_F_EPSInternalFault 2906;
BA_ "FaultZone" SG_ 1210 P12_PCU_F_EPSInternalFault "EPS";
BA_ "FaultEffect" SG_ 1210 P12_PCU_F_EPSInternalFault "TCS Disable";
BA_ "FaultAction" SG_ 1210 P12_PCU_F_EPSInternalFault "Check EPS Module";
BA_ "FaultTrigger" SG_ 1210 P12_PCU_F_EPSInternalFault "Internal Fault";
BA_ "FaultTrigger" SG_ 1210 P12_PCU_F_BrakePressureInvalidFa "Both channels are faulty (Max or Min violation, short or mismatch)";
BA_ "FaultAction" SG_ 1210 P12_PCU_F_BrakePressureInvalidFa "1- Check Brake Pedal Wires



2- Check VCU 5V



3- Check VCU Analog Input Channel



4- Internal Failure";
BA_ "FaultEffect" SG_ 1210 P12_PCU_F_BrakePressureInvalidFa "Cruise control and creep disabled.";
BA_ "FaultZone" SG_ 1210 P12_PCU_F_BrakePressureInvalidFa "Brake Pedal";
BA_ "Priority" SG_ 1210 P12_PCU_F_BrakePressureInvalidFa 1;
BA_ "SPN" SG_ 1210 P12_PCU_F_BrakePressureInvalidFa 2901;
BA_ "SystemSignalLongSymbol" SG_ 1210 P12_PCU_F_BrakePressureInvalidFa "P12_PCU_F_BrakePressureInvalidFault";
BA_ "Priority" SG_ 1210 P12_PCU_F_AcceleratorPedalPositi 2;
BA_ "SPN" SG_ 1210 P12_PCU_F_AcceleratorPedalPositi 2900;
BA_ "FaultZone" SG_ 1210 P12_PCU_F_AcceleratorPedalPositi "Throttle Pedal";
BA_ "FaultEffect" SG_ 1210 P12_PCU_F_AcceleratorPedalPositi "cruise control disabled";
BA_ "FaultAction" SG_ 1210 P12_PCU_F_AcceleratorPedalPositi "1- Check Throttle Pedal Wires



2- Check VCU 5V



3- Check VCU Analog Input Channel



4- Internal Failure";
BA_ "FaultTrigger" SG_ 1210 P12_PCU_F_AcceleratorPedalPositi "Both channels are faulty (Max or Min violation, short or mismatch)";
BA_ "SystemSignalLongSymbol" SG_ 1210 P12_PCU_F_AcceleratorPedalPositi "P12_PCU_F_AcceleratorPedalPositionBothChannelFault";
BA_ "Priority" SG_ 1210 P12_PCU_F_ESCCommunicationFault 3;
BA_ "SPN" SG_ 1210 P12_PCU_F_ESCCommunicationFault 2529;
BA_ "FaultZone" SG_ 1210 P12_PCU_F_ESCCommunicationFault "ESP";
BA_ "FaultEffect" SG_ 1210 P12_PCU_F_ESCCommunicationFault "TCS Disable";
BA_ "FaultAction" SG_ 1210 P12_PCU_F_ESCCommunicationFault "Check ESP Module";
BA_ "FaultTrigger" SG_ 1210 P12_PCU_F_ESCCommunicationFault "Abnormal CAN Message Cycle Time";
BA_ "SPN" SG_ 1210 P12_PCU_F_EPSCommunicationFault 2530;
BA_ "FaultZone" SG_ 1210 P12_PCU_F_EPSCommunicationFault "EPS";
BA_ "FaultEffect" SG_ 1210 P12_PCU_F_EPSCommunicationFault "TCS Disable";
BA_ "FaultAction" SG_ 1210 P12_PCU_F_EPSCommunicationFault "Check EPS Module";
BA_ "FaultTrigger" SG_ 1210 P12_PCU_F_EPSCommunicationFault "Abnormal CAN Message Cycle Time";
BA_ "FaultTrigger" SG_ 1210 P12_PCU_F_BrakeStopLightFault "Pedal staus and stop light status are inconsistent.";
BA_ "FaultAction" SG_ 1210 P12_PCU_F_BrakeStopLightFault "Check Brake microswitch";
BA_ "FaultEffect" SG_ 1210 P12_PCU_F_BrakeStopLightFault "No action";
BA_ "FaultZone" SG_ 1210 P12_PCU_F_BrakeStopLightFault "Brake Pedal";
BA_ "Priority" SG_ 1210 P12_PCU_F_BrakeStopLightFault 1;
BA_ "SPN" SG_ 1210 P12_PCU_F_BrakeStopLightFault 2487;
BA_ "Priority" SG_ 1210 P12_PCU_F_SASUpdateParameterFaul 3;
BA_ "SPN" SG_ 1210 P12_PCU_F_SASUpdateParameterFaul 2413;
BA_ "FaultEffect" SG_ 1210 P12_PCU_F_SASUpdateParameterFaul "TCS Disable";
BA_ "FaultZone" SG_ 1210 P12_PCU_F_SASUpdateParameterFaul "steering";
BA_ "FaultAction" SG_ 1210 P12_PCU_F_SASUpdateParameterFaul "Check steering system";
BA_ "FaultTrigger" SG_ 1210 P12_PCU_F_SASUpdateParameterFaul "Internal Fault";
BA_ "SystemSignalLongSymbol" SG_ 1210 P12_PCU_F_SASUpdateParameterFaul "P12_PCU_F_SASUpdateParameterFault";
BA_ "Priority" SG_ 1210 P12_PCU_F_SASInternalFault 3;
BA_ "SPN" SG_ 1210 P12_PCU_F_SASInternalFault 2411;
BA_ "FaultEffect" SG_ 1210 P12_PCU_F_SASInternalFault "TCS Disable";
BA_ "FaultZone" SG_ 1210 P12_PCU_F_SASInternalFault "steering";
BA_ "FaultAction" SG_ 1210 P12_PCU_F_SASInternalFault "Check steering system";
BA_ "FaultTrigger" SG_ 1210 P12_PCU_F_SASInternalFault "Check CAN Parameter Range";
BA_ "Priority" SG_ 1210 P12_PCU_F_SASCommunicationFault 3;
BA_ "SPN" SG_ 1210 P12_PCU_F_SASCommunicationFault 2412;
BA_ "FaultZone" SG_ 1210 P12_PCU_F_SASCommunicationFault "steering";
BA_ "FaultEffect" SG_ 1210 P12_PCU_F_SASCommunicationFault "TCS Disable";
BA_ "FaultAction" SG_ 1210 P12_PCU_F_SASCommunicationFault "Check steering system";
BA_ "FaultTrigger" SG_ 1210 P12_PCU_F_SASCommunicationFault "Abnormal CAN Message Cycle Time";
BA_ "Priority" SG_ 1210 P12_PCU_F_CruiseKeyOpenWireFault 2;
BA_ "SPN" SG_ 1210 P12_PCU_F_CruiseKeyOpenWireFault 2414;
BA_ "FaultZone" SG_ 1210 P12_PCU_F_CruiseKeyOpenWireFault "Cruise key";
BA_ "FaultEffect" SG_ 1210 P12_PCU_F_CruiseKeyOpenWireFault "Cruise control will be disabled";
BA_ "FaultAction" SG_ 1210 P12_PCU_F_CruiseKeyOpenWireFault "1- Check  Wire



2- Check  Module";
BA_ "FaultTrigger" SG_ 1210 P12_PCU_F_CruiseKeyOpenWireFault "Check ADC range between [700 3550]";
BA_ "FaultTrigger" SG_ 1210 P12_PCU_F_ABSRearRightSpeedFault "Compare Sensor Value With a Specific Value 300 km/h";
BA_ "FaultAction" SG_ 1210 P12_PCU_F_ABSRearRightSpeedFault "1- Check Rear Right Wheel Speed Sensor



2- ABS Internal Failure";
BA_ "FaultEffect" SG_ 1210 P12_PCU_F_ABSRearRightSpeedFault "TCS Disable";
BA_ "FaultZone" SG_ 1210 P12_PCU_F_ABSRearRightSpeedFault "ABS";
BA_ "Priority" SG_ 1210 P12_PCU_F_ABSRearRightSpeedFault 3;
BA_ "SPN" SG_ 1210 P12_PCU_F_ABSRearRightSpeedFault 2410;
BA_ "FaultTrigger" SG_ 1210 P12_PCU_F_ABSRearLeftSpeedFault "Compare Sensor Value With a Specific Value 300 km/h";
BA_ "FaultAction" SG_ 1210 P12_PCU_F_ABSRearLeftSpeedFault "1- Check Rear Left Wheel Speed Sensor



2- ABS Internal Failure";
BA_ "FaultEffect" SG_ 1210 P12_PCU_F_ABSRearLeftSpeedFault "TCS Disable";
BA_ "FaultZone" SG_ 1210 P12_PCU_F_ABSRearLeftSpeedFault "ABS";
BA_ "Priority" SG_ 1210 P12_PCU_F_ABSRearLeftSpeedFault 3;
BA_ "SPN" SG_ 1210 P12_PCU_F_ABSRearLeftSpeedFault 2409;
BA_ "FaultTrigger" SG_ 1210 P12_PCU_F_ABSFrontRightSpeedFaul "Compare Sensor Value With a Specific Value 300 km/h";
BA_ "FaultAction" SG_ 1210 P12_PCU_F_ABSFrontRightSpeedFaul "1- Check Front Right Wheel Speed Sensor



2- ABS Internal Failure";
BA_ "FaultEffect" SG_ 1210 P12_PCU_F_ABSFrontRightSpeedFaul "TCS Disable";
BA_ "FaultZone" SG_ 1210 P12_PCU_F_ABSFrontRightSpeedFaul "ABS";
BA_ "Priority" SG_ 1210 P12_PCU_F_ABSFrontRightSpeedFaul 3;
BA_ "SPN" SG_ 1210 P12_PCU_F_ABSFrontRightSpeedFaul 2408;
BA_ "SystemSignalLongSymbol" SG_ 1210 P12_PCU_F_ABSFrontRightSpeedFaul "P12_PCU_F_ABSFrontRightSpeedFault";
BA_ "FaultTrigger" SG_ 1210 P12_PCU_F_ABSFrontLeftSpeedFault "Compare Sensor Value With a Specific Value 300 km/h";
BA_ "FaultAction" SG_ 1210 P12_PCU_F_ABSFrontLeftSpeedFault "1- Check Front Left Wheel Speed Sensor



2- ABS Internal Failure";
BA_ "FaultEffect" SG_ 1210 P12_PCU_F_ABSFrontLeftSpeedFault "TCS Disable";
BA_ "FaultZone" SG_ 1210 P12_PCU_F_ABSFrontLeftSpeedFault "ABS";
BA_ "Priority" SG_ 1210 P12_PCU_F_ABSFrontLeftSpeedFault 3;
BA_ "SPN" SG_ 1210 P12_PCU_F_ABSFrontLeftSpeedFault 2407;
BA_ "FaultTrigger" SG_ 1210 P12_PCU_F_ABSCommunicationFault "Abnormal CAN Message Cycle Time";
BA_ "FaultAction" SG_ 1210 P12_PCU_F_ABSCommunicationFault "1- Check ABS Fuse



3- Check ABS Wires



2- Internal Failure";
BA_ "FaultEffect" SG_ 1210 P12_PCU_F_ABSCommunicationFault "TCS Disable";
BA_ "FaultZone" SG_ 1210 P12_PCU_F_ABSCommunicationFault "ABS";
BA_ "Priority" SG_ 1210 P12_PCU_F_ABSCommunicationFault 3;
BA_ "SPN" SG_ 1210 P12_PCU_F_ABSCommunicationFault 2406;
BA_ "FaultTrigger" SG_ 1210 P12_PCU_F_BrakePedalMicroSwitchF "Receiving off status whem brake pedal is pressed more than a minimum threshold.";
BA_ "FaultAction" SG_ 1210 P12_PCU_F_BrakePedalMicroSwitchF "Check Brake microswitch";
BA_ "FaultZone" SG_ 1210 P12_PCU_F_BrakePedalMicroSwitchF "Brake Pedal";
BA_ "FaultEffect" SG_ 1210 P12_PCU_F_BrakePedalMicroSwitchF "speed limit (120) activated";
BA_ "Priority" SG_ 1210 P12_PCU_F_BrakePedalMicroSwitchF 1;
BA_ "SPN" SG_ 1210 P12_PCU_F_BrakePedalMicroSwitchF 2405;
BA_ "SystemSignalLongSymbol" SG_ 1210 P12_PCU_F_BrakePedalMicroSwitchF "P12_PCU_F_BrakePedalMicroSwitchFault";
BA_ "FaultTrigger" SG_ 1210 P12_PCU_F_AcceleratorPedalP_0000 "Supply voltage gets out of [4.8 5.2] range";
BA_ "FaultAction" SG_ 1210 P12_PCU_F_AcceleratorPedalP_0000 "1- Check Throttle Pedal Wires



2- Check VCU 5V



3- Check VCU Analog Input Channel



4- Internal Failure";
BA_ "FaultEffect" SG_ 1210 P12_PCU_F_AcceleratorPedalP_0000 "Channel2 disabled";
BA_ "FaultZone" SG_ 1210 P12_PCU_F_AcceleratorPedalP_0000 "Throttle Pedal";
BA_ "Priority" SG_ 1210 P12_PCU_F_AcceleratorPedalP_0000 3;
BA_ "SPN" SG_ 1210 P12_PCU_F_AcceleratorPedalP_0000 2398;
BA_ "SystemSignalLongSymbol" SG_ 1210 P12_PCU_F_AcceleratorPedalP_0000 "P12_PCU_F_AcceleratorPedalPositionVCC2OutOfRangeFault";
BA_ "FaultTrigger" SG_ 1210 P12_PCU_F_AcceleratorPedalP_0001 "Supply voltage gets out of [4.8 5.2] range";
BA_ "FaultAction" SG_ 1210 P12_PCU_F_AcceleratorPedalP_0001 "1- Check Throttle Pedal Wires



2- Check VCU 5V



3- Check VCU Analog Input Channel



4- Internal Failure";
BA_ "FaultEffect" SG_ 1210 P12_PCU_F_AcceleratorPedalP_0001 "Channel1 disabled";
BA_ "FaultZone" SG_ 1210 P12_PCU_F_AcceleratorPedalP_0001 "Throttle Pedal";
BA_ "Priority" SG_ 1210 P12_PCU_F_AcceleratorPedalP_0001 3;
BA_ "SPN" SG_ 1210 P12_PCU_F_AcceleratorPedalP_0001 2397;
BA_ "SystemSignalLongSymbol" SG_ 1210 P12_PCU_F_AcceleratorPedalP_0001 "P12_PCU_F_AcceleratorPedalPositionVCC1OutOfRangeFault";
BA_ "FaultTrigger" SG_ 1210 P12_PCU_F_AcceleratorPedalP_0002 "If two channels voltages are identical, the fault is set.";
BA_ "FaultAction" SG_ 1210 P12_PCU_F_AcceleratorPedalP_0002 "1- Check Throttle Pedal Wires";
BA_ "FaultEffect" SG_ 1210 P12_PCU_F_AcceleratorPedalP_0002 "Both channels are disabled";
BA_ "FaultZone" SG_ 1210 P12_PCU_F_AcceleratorPedalP_0002 "Throttle Pedal";
BA_ "Priority" SG_ 1210 P12_PCU_F_AcceleratorPedalP_0002 4;
BA_ "SPN" SG_ 1210 P12_PCU_F_AcceleratorPedalP_0002 2399;
BA_ "SystemSignalLongSymbol" SG_ 1210 P12_PCU_F_AcceleratorPedalP_0002 "P12_PCU_F_AcceleratorPedalPositionChannelsShortCircuitFault";
BA_ "Priority" SG_ 1210 P12_PCU_F_AcceleratorPedalP_0003 3;
BA_ "SPN" SG_ 1210 P12_PCU_F_AcceleratorPedalP_0003 2396;
BA_ "FaultZone" SG_ 1210 P12_PCU_F_AcceleratorPedalP_0003 "Throttle Pedal";
BA_ "FaultEffect" SG_ 1210 P12_PCU_F_AcceleratorPedalP_0003 "Throttle channel2 gets disabled";
BA_ "FaultAction" SG_ 1210 P12_PCU_F_AcceleratorPedalP_0003 "1- Check Throttle Pedal Wires



2- Check VCU 5V



3- Check VCU Analog Input Channel



4- Internal Failure";
BA_ "FaultTrigger" SG_ 1210 P12_PCU_F_AcceleratorPedalP_0003 "Compare Throttle Value Channel 2 Witth Up Threshold= 4.8V";
BA_ "SystemSignalLongSymbol" SG_ 1210 P12_PCU_F_AcceleratorPedalP_0003 "P12_PCU_F_AcceleratorPedalPositionChannel2MaxRangeFault";
BA_ "Priority" SG_ 1210 P12_PCU_F_AcceleratorPedalP_0004 3;
BA_ "SPN" SG_ 1210 P12_PCU_F_AcceleratorPedalP_0004 2395;
BA_ "FaultZone" SG_ 1210 P12_PCU_F_AcceleratorPedalP_0004 "Throttle Pedal";
BA_ "FaultEffect" SG_ 1210 P12_PCU_F_AcceleratorPedalP_0004 "Throttle channel1 gets disabled";
BA_ "FaultAction" SG_ 1210 P12_PCU_F_AcceleratorPedalP_0004 "1- Check Throttle Pedal Wires



2- Check VCU 5V



3- Check VCU Analog Input Channel



4- Internal Failure";
BA_ "FaultTrigger" SG_ 1210 P12_PCU_F_AcceleratorPedalP_0004 "Compare Throttle Value Channel 1 Witth Down Threshold= 0.2V";
BA_ "SystemSignalLongSymbol" SG_ 1210 P12_PCU_F_AcceleratorPedalP_0004 "P12_PCU_F_AcceleratorPedalPositionChannel1MaxRangeFault";
BA_ "Priority" SG_ 1210 P12_PCU_F_VacuumPumpSensorMalfun 3;
BA_ "SPN" SG_ 1210 P12_PCU_F_VacuumPumpSensorMalfun 2264;
BA_ "FaultZone" SG_ 1210 P12_PCU_F_VacuumPumpSensorMalfun "vacuum pump";
BA_ "FaultEffect" SG_ 1210 P12_PCU_F_VacuumPumpSensorMalfun "vacuum pump disabled



speed limit to 40km/h



cruise control disabled



100% retard";
BA_ "FaultAction" SG_ 1210 P12_PCU_F_VacuumPumpSensorMalfun "check vacuum pump";
BA_ "FaultTrigger" SG_ 1210 P12_PCU_F_VacuumPumpSensorMalfun "detection by recognizing a pin status sequence on a digital inpu";
BA_ "SystemSignalLongSymbol" SG_ 1210 P12_PCU_F_VacuumPumpSensorMalfun "P12_PCU_F_VacuumPumpSensorMalfunctionFault";
BA_ "Priority" SG_ 1210 P12_PCU_F_VacuumPumpCurrentAbnor 3;
BA_ "SPN" SG_ 1210 P12_PCU_F_VacuumPumpCurrentAbnor 2265;
BA_ "FaultZone" SG_ 1210 P12_PCU_F_VacuumPumpCurrentAbnor "vacuum pump";
BA_ "FaultEffect" SG_ 1210 P12_PCU_F_VacuumPumpCurrentAbnor "vacuum pump disabled



speed limit to 40km/h



cruise control disabled



100% retard";
BA_ "FaultAction" SG_ 1210 P12_PCU_F_VacuumPumpCurrentAbnor "check vacuum pump";
BA_ "FaultTrigger" SG_ 1210 P12_PCU_F_VacuumPumpCurrentAbnor "detection by recognizing a pin status sequence on a digital inpu";
BA_ "SystemSignalLongSymbol" SG_ 1210 P12_PCU_F_VacuumPumpCurrentAbnor "P12_PCU_F_VacuumPumpCurrentAbnormalFault";
BA_ "Priority" SG_ 1210 P12_PCU_F_VacuumPumpPowerAbnorma 3;
BA_ "SPN" SG_ 1210 P12_PCU_F_VacuumPumpPowerAbnorma 2266;
BA_ "FaultZone" SG_ 1210 P12_PCU_F_VacuumPumpPowerAbnorma "vacuum pump";
BA_ "FaultEffect" SG_ 1210 P12_PCU_F_VacuumPumpPowerAbnorma "vacuum pump disabled



speed limit to 40km/h



cruise control disabled



100% retard";
BA_ "FaultAction" SG_ 1210 P12_PCU_F_VacuumPumpPowerAbnorma "check vacuum pump";
BA_ "FaultTrigger" SG_ 1210 P12_PCU_F_VacuumPumpPowerAbnorma "detection by recognizing a pin status sequence on a digital inpu";
BA_ "SystemSignalLongSymbol" SG_ 1210 P12_PCU_F_VacuumPumpPowerAbnorma "P12_PCU_F_VacuumPumpPowerAbnormalFault";
BA_ "Priority" SG_ 1210 P12_PCU_F_VacuumPumpMajorFault 1;
BA_ "SPN" SG_ 1210 P12_PCU_F_VacuumPumpMajorFault 2263;
BA_ "FaultZone" SG_ 1210 P12_PCU_F_VacuumPumpMajorFault "vacuum pump";
BA_ "FaultEffect" SG_ 1210 P12_PCU_F_VacuumPumpMajorFault "vacuum pump disabled



speed limit to 40km/h



cruise control disabled



100% retard";
BA_ "FaultAction" SG_ 1210 P12_PCU_F_VacuumPumpMajorFault "check vacuum pump";
BA_ "FaultTrigger" SG_ 1210 P12_PCU_F_VacuumPumpMajorFault "detection by recognizing a pin status sequence on a digital inpu";
BA_ "FaultTrigger" SG_ 1210 P12_PCU_F_AcceleratorPedalP_0005 "Compare Channel 1 & 2 percentage and set fault if the result is above 10%";
BA_ "FaultAction" SG_ 1210 P12_PCU_F_AcceleratorPedalP_0005 "1- Check Throttle Pedal Wires



2- Check VCU 5V



3- Check VCU Analog Input Channel



4- Internal Failure";
BA_ "FaultEffect" SG_ 1210 P12_PCU_F_AcceleratorPedalP_0005 "Both channels are disabled";
BA_ "FaultZone" SG_ 1210 P12_PCU_F_AcceleratorPedalP_0005 "Throttle Pedal";
BA_ "Priority" SG_ 1210 P12_PCU_F_AcceleratorPedalP_0005 4;
BA_ "SPN" SG_ 1210 P12_PCU_F_AcceleratorPedalP_0005 2256;
BA_ "SystemSignalLongSymbol" SG_ 1210 P12_PCU_F_AcceleratorPedalP_0005 "P12_PCU_F_AcceleratorPedalPositionChannelsMismatchFault";
BA_ "Priority" SG_ 1210 P12_PCU_F_AcceleratorPedalP_0006 3;
BA_ "SPN" SG_ 1210 P12_PCU_F_AcceleratorPedalP_0006 2255;
BA_ "FaultZone" SG_ 1210 P12_PCU_F_AcceleratorPedalP_0006 "Throttle Pedal";
BA_ "FaultEffect" SG_ 1210 P12_PCU_F_AcceleratorPedalP_0006 "Throttle channel2 gets disabled";
BA_ "FaultAction" SG_ 1210 P12_PCU_F_AcceleratorPedalP_0006 "1- Check Throttle Pedal Wires



2- Check VCU 5V



3- Check VCU Analog Input Channel



4- Internal Failure";
BA_ "FaultTrigger" SG_ 1210 P12_PCU_F_AcceleratorPedalP_0006 "Compare Throttle Value Channel 1 Witth Up Threshold= 4.8V";
BA_ "SystemSignalLongSymbol" SG_ 1210 P12_PCU_F_AcceleratorPedalP_0006 "P12_PCU_F_AcceleratorPedalPositionChannel2MinRangeFault";
BA_ "Priority" SG_ 1210 P12_PCU_F_AcceleratorPedalP_0007 3;
BA_ "SPN" SG_ 1210 P12_PCU_F_AcceleratorPedalP_0007 2254;
BA_ "FaultZone" SG_ 1210 P12_PCU_F_AcceleratorPedalP_0007 "Throttle Pedal";
BA_ "FaultEffect" SG_ 1210 P12_PCU_F_AcceleratorPedalP_0007 "Throttle channel1 gets disabled";
BA_ "FaultAction" SG_ 1210 P12_PCU_F_AcceleratorPedalP_0007 "1- Check Throttle Pedal Wires



2- Check VCU 5V



3- Check VCU Analog Input Channel



4- Internal Failure";
BA_ "FaultTrigger" SG_ 1210 P12_PCU_F_AcceleratorPedalP_0007 "Compare Throttle Value Channel 1 Witth Down Threshold= 0.2V";
BA_ "SystemSignalLongSymbol" SG_ 1210 P12_PCU_F_AcceleratorPedalP_0007 "P12_PCU_F_AcceleratorPedalPositionChannel1MinRangeFault";
BA_ "Priority" SG_ 1210 P12_PCU_F_NDRUpdateParameterFaul 3;
BA_ "SPN" SG_ 1210 P12_PCU_F_NDRUpdateParameterFaul 2261;
BA_ "FaultZone" SG_ 1210 P12_PCU_F_NDRUpdateParameterFaul "NDR Module";
BA_ "FaultEffect" SG_ 1210 P12_PCU_F_NDRUpdateParameterFaul "Motion disable and EV to park Mode";
BA_ "FaultAction" SG_ 1210 P12_PCU_F_NDRUpdateParameterFaul "1- Check  Wire



2- Check  Module";
BA_ "FaultTrigger" SG_ 1210 P12_PCU_F_NDRUpdateParameterFaul "Internal Fault";
BA_ "SystemSignalLongSymbol" SG_ 1210 P12_PCU_F_NDRUpdateParameterFaul "P12_PCU_F_NDRUpdateParameterFault";
BA_ "SPN" SG_ 1210 P12_PCU_F_NDRInternalFault 2260;
BA_ "FaultZone" SG_ 1210 P12_PCU_F_NDRInternalFault "NDR Module";
BA_ "FaultEffect" SG_ 1210 P12_PCU_F_NDRInternalFault "Motion disable and EV to park Mode";
BA_ "FaultAction" SG_ 1210 P12_PCU_F_NDRInternalFault "1- Check  Wire



2- Check  Module";
BA_ "FaultTrigger" SG_ 1210 P12_PCU_F_NDRInternalFault "Check CAN Parameter Range";
BA_ "Priority" SG_ 1210 P12_PCU_F_NDRCommunicationFault 3;
BA_ "SPN" SG_ 1210 P12_PCU_F_NDRCommunicationFault 2262;
BA_ "FaultZone" SG_ 1210 P12_PCU_F_NDRCommunicationFault "NDR Module";
BA_ "FaultEffect" SG_ 1210 P12_PCU_F_NDRCommunicationFault "Motion disable and EV to park Mode";
BA_ "FaultAction" SG_ 1210 P12_PCU_F_NDRCommunicationFault "1- Check  Wire



2- Check  Module";
BA_ "FaultTrigger" SG_ 1210 P12_PCU_F_NDRCommunicationFault "Abnormal CAN Message Cycle Time";
BA_ "SPN" SG_ 1466 P11_PCU_S_BrakePedalReadyToWork 2962;
BA_ "SPN" SG_ 1466 P11_PCU_S_AcceleratorPedalPositi 2965;
BA_ "SystemSignalLongSymbol" SG_ 1466 P11_PCU_S_AcceleratorPedalPositi "P11_PCU_S_AcceleratorPedalPositionChannel2ReadyToWork";
BA_ "SPN" SG_ 1466 P11_PCU_S_AcceleratorPedalP_0000 2964;
BA_ "SystemSignalLongSymbol" SG_ 1466 P11_PCU_S_AcceleratorPedalP_0000 "P11_PCU_S_AcceleratorPedalPositionChannel1ReadyToWork";
BA_ "SPN" SG_ 1466 P11_PCU_S_VehicleReadyState 2956;
BA_ "SPN" SG_ 1466 P11_PCU_S_EDUWaterPumpReadyToWor 2252;
BA_ "SystemSignalLongSymbol" SG_ 1466 P11_PCU_S_EDUWaterPumpReadyToWor "P11_PCU_S_EDUWaterPumpReadyToWork";
BA_ "SPN" SG_ 1466 P11_PCU_S_BatteryPackWaterPumpRe 2253;
BA_ "SystemSignalLongSymbol" SG_ 1466 P11_PCU_S_BatteryPackWaterPumpRe "P11_PCU_S_BatteryPackWaterPumpReadyToWork";
BA_ "SPN" SG_ 1466 P11_PCU_S_NDRReadyToWork 2251;
BA_ "SPN" SG_ 1466 P11_PCU_S_OBCReadyToWork 2250;
BA_ "SPN" SG_ 1466 P11_PCU_S_MCUReadyToWork 2249;
BA_ "SPN" SG_ 1466 P11_PCU_S_DCDCReadyToWork 2248;
BA_ "SPN" SG_ 1466 P11_PCU_S_CoolerCompressorReadyT 2247;
BA_ "SystemSignalLongSymbol" SG_ 1466 P11_PCU_S_CoolerCompressorReadyT "P11_PCU_S_CoolerCompressorReadyToWork";
BA_ "SPN" SG_ 1466 P11_PCU_S_CabinHeaterReadyToWork 2246;
BA_ "SPN" SG_ 1466 P11_PCU_S_BMSReadyToWork 2245;
BA_ "SPN" SG_ 1450 P10_PCU_D_PedalSupplyChannel2 2534;
BA_ "SPN" SG_ 1450 P10_PCU_D_PedalSupplyChannel1 2533;
BA_ "SPN" SG_ 1450 P10_PCU_D_3V3SupplyVoltage 2535;
BA_ "SPN" SG_ 1450 P10_PCU_D_5VSupplyVoltage 2244;
BA_ "SPN" SG_ 1450 P10_PCU_D_InputVoltage 2243;
BA_ "GenSigStartValue" SG_ 1450 P10_PCU_D_ProcessorTemperature 40;
BA_ "SPN" SG_ 1450 P10_PCU_D_ProcessorTemperature 2242;
BA_ "SPN" SG_ 1434 P09_PCU_S_BatteryChillerValveSta 2972;
BA_ "SystemSignalLongSymbol" SG_ 1434 P09_PCU_S_BatteryChillerValveSta "P09_PCU_S_BatteryChillerValveStatus";
BA_ "SPN" SG_ 1434 P09_PCU_S_CabinCoolerValveStatus 2971;
BA_ "SPN" SG_ 1434 P09_PCU_F_CabinCoolerValveMismat 2235;
BA_ "SystemSignalLongSymbol" SG_ 1434 P09_PCU_F_CabinCoolerValveMismat "P09_PCU_F_CabinCoolerValveMismatchFault";
BA_ "SPN" SG_ 1434 P09_PCU_S_OBDFanCommand 2969;
BA_ "SPN" SG_ 1434 P09_PCU_F_EDUCoolantTemperatureO 2394;
BA_ "SystemSignalLongSymbol" SG_ 1434 P09_PCU_F_EDUCoolantTemperatureO "P09_PCU_F_EDUCoolantTemperatureOpenCircuitFault";
BA_ "GenSigStartValue" SG_ 1434 P09_PCU_D_EDUCoolantTemperature 40;
BA_ "SPN" SG_ 1434 P09_PCU_D_EDUCoolantTemperature 2241;
BA_ "GenSigStartValue" SG_ 1434 P09_PCU_D_BatteryPackCoolantTemp 40;
BA_ "SPN" SG_ 1434 P09_PCU_D_BatteryPackCoolantTemp 2240;
BA_ "SystemSignalLongSymbol" SG_ 1434 P09_PCU_D_BatteryPackCoolantTemp "P09_PCU_D_BatteryPackCoolantTemperature";
BA_ "SPN" SG_ 1434 P09_PCU_F_EDUCoolantTemperatureS 2239;
BA_ "SystemSignalLongSymbol" SG_ 1434 P09_PCU_F_EDUCoolantTemperatureS "P09_PCU_F_EDUCoolantTemperatureShortCircuitFault";
BA_ "SPN" SG_ 1434 P09_PCU_F_BatteryPackCoolantTemp 2236;
BA_ "SystemSignalLongSymbol" SG_ 1434 P09_PCU_F_BatteryPackCoolantTemp "P09_PCU_F_BatteryPackCoolantTemperatureOpenCircuitFault";
BA_ "SPN" SG_ 1434 P09_PCU_F_BatteryPackCoolan_0000 2237;
BA_ "SystemSignalLongSymbol" SG_ 1434 P09_PCU_F_BatteryPackCoolan_0000 "P09_PCU_F_BatteryPackCoolantTemperatureShortCircuitFault";
BA_ "SPN" SG_ 1434 P09_PCU_S_CabinCoolerValveComman 2227;
BA_ "SystemSignalLongSymbol" SG_ 1434 P09_PCU_S_CabinCoolerValveComman "P09_PCU_S_CabinCoolerValveCommand";
BA_ "SPN" SG_ 1434 P09_PCU_S_BatteryChillerValveCom 2228;
BA_ "SystemSignalLongSymbol" SG_ 1434 P09_PCU_S_BatteryChillerValveCom "P09_PCU_S_BatteryChillerValveCommand";
BA_ "SPN" SG_ 1434 P09_PCU_F_BatteryChillerValveMis 2974;
BA_ "SystemSignalLongSymbol" SG_ 1434 P09_PCU_F_BatteryChillerValveMis "P09_PCU_F_BatteryChillerValveMismatchFault";
BA_ "SPN" SG_ 1434 P09_PCU_S_FanCommandState 2219;
BA_ "SPN" SG_ 1594 P08_PCU_D_BrakePedalPercent 2216;
BA_ "SPN" SG_ 1402 P07_PCU_D_AcceleratorPedalPositi 2213;
BA_ "SystemSignalLongSymbol" SG_ 1402 P07_PCU_D_AcceleratorPedalPositi "P07_PCU_D_AcceleratorPedalPositionChannel2Percent";
BA_ "SPN" SG_ 1402 P07_PCU_D_AcceleratorPedalP_0000 2212;
BA_ "SystemSignalLongSymbol" SG_ 1402 P07_PCU_D_AcceleratorPedalP_0000 "P07_PCU_D_AcceleratorPedalPositionChannel1Percent";
BA_ "SPN" SG_ 1402 P07_PCU_D_AcceleratorPedalP_0001 2211;
BA_ "SystemSignalLongSymbol" SG_ 1402 P07_PCU_D_AcceleratorPedalP_0001 "P07_PCU_D_AcceleratorPedalPositionPercent";
BA_ "SPN" SG_ 1386 P06_PCU_D_BatteryPackPower 2976;
BA_ "GenSigStartValue" SG_ 1386 P06_PCU_D_BatteryPackPower 100;
BA_ "SPN" SG_ 1386 P06_PCU_D_BatteryPackCycle 2975;
BA_ "SPN" SG_ 1386 P06_PCU_D_VehicleSpeed 2210;
BA_ "SPN" SG_ 1370 P05_PCU_S_BatteryPackHeaterHVILS 2958;
BA_ "SystemSignalLongSymbol" SG_ 1370 P05_PCU_S_BatteryPackHeaterHVILS "P05_PCU_S_BatteryPackHeaterHVILState";
BA_ "SPN" SG_ 1370 P05_PCU_S_CoolerCompressorHVILSt 2959;
BA_ "SystemSignalLongSymbol" SG_ 1370 P05_PCU_S_CoolerCompressorHVILSt "P05_PCU_S_CoolerCompressorHVILState";
BA_ "SPN" SG_ 1370 P05_PCU_S_CoolingActuatorPowerSt 2944;
BA_ "SystemSignalLongSymbol" SG_ 1370 P05_PCU_S_CoolingActuatorPowerSt "P05_PCU_S_CoolingActuatorPowerStatus";
BA_ "SPN" SG_ 1370 P05_PCU_S_VacuumPumpPowerStatus 2943;
BA_ "SPN" SG_ 1370 P05_PCU_S_StartSwitchState 2946;
BA_ "SPN" SG_ 1370 P05_PCU_S_FanHighAndLowSpeedStat 2945;
BA_ "SystemSignalLongSymbol" SG_ 1370 P05_PCU_S_FanHighAndLowSpeedStat "P05_PCU_S_FanHighAndLowSpeedStatus";
BA_ "SPN" SG_ 1370 P05_PCU_D_EDUCoolantTemperatureA 2209;
BA_ "SystemSignalLongSymbol" SG_ 1370 P05_PCU_D_EDUCoolantTemperatureA "P05_PCU_D_EDUCoolantTemperatureADCRaw";
BA_ "SPN" SG_ 1354 P04_PCU_D_BatteryCoolantTemperat 2208;
BA_ "SystemSignalLongSymbol" SG_ 1354 P04_PCU_D_BatteryCoolantTemperat "P04_PCU_D_BatteryCoolantTemperatureADCRaw";
BA_ "SPN" SG_ 1354 P04_PCU_D_AcceleratorPedalPositi 2207;
BA_ "SystemSignalLongSymbol" SG_ 1354 P04_PCU_D_AcceleratorPedalPositi "P04_PCU_D_AcceleratorPedalPositionChannel1ADCRaw";
BA_ "SPN" SG_ 1354 P04_PCU_D_AcceleratorPedalP_0000 2206;
BA_ "SystemSignalLongSymbol" SG_ 1354 P04_PCU_D_AcceleratorPedalP_0000 "P04_PCU_D_AcceleratorPedalPositionChannel2ADCRaw";
BA_ "SPN" SG_ 1338 P03_PCU_D_CruiseKeyADCRaw 2203;
BA_ "SPN" SG_ 1322 P02_PCU_S_PressureSwitchFanHighS 2532;
BA_ "SystemSignalLongSymbol" SG_ 1322 P02_PCU_S_PressureSwitchFanHighS "P02_PCU_S_PressureSwitchFanHighSpeedState";
BA_ "SPN" SG_ 1322 P02_PCU_S_VehiclePowerUpRelaySta 2531;
BA_ "SystemSignalLongSymbol" SG_ 1322 P02_PCU_S_VehiclePowerUpRelaySta "P02_PCU_S_VehiclePowerUpRelayStatus";
BA_ "SPN" SG_ 1322 P02_PCU_D_AirConditionerTemperat 2202;
BA_ "SystemSignalLongSymbol" SG_ 1322 P02_PCU_D_AirConditionerTemperat "P02_PCU_D_AirConditionerTemperatureKnobADCRaw";
BA_ "SPN" SG_ 1322 P02_PCU_S_VacuumPumpPWMState 2189;
BA_ "SPN" SG_ 1322 P02_PCU_S_BlowerFanSelectorState 2190;
BA_ "SPN" SG_ 1322 P02_PCU_S_FastChargeRelayStatus 2191;
BA_ "SPN" SG_ 1322 P02_PCU_S_ESCKeyState 2192;
BA_ "SPN" SG_ 1322 P02_PCU_S_BrakeMicroSwitchState 2193;
BA_ "SPN" SG_ 1322 P02_PCU_S_BrakeStopPedalState 2194;
BA_ "SPN" SG_ 1322 P02_PCU_S_ACCState 2195;
BA_ "SPN" SG_ 1322 P02_PCU_S_IgnitionState 2196;
BA_ "SPN" SG_ 1322 P02_PCU_S_OBCPlugState 2197;
BA_ "SPN" SG_ 1322 P02_PCU_S_CabinCoolerValveStatus 2198;
BA_ "SPN" SG_ 1322 P02_PCU_S_BatteryChillerValveSta 2199;
BA_ "SystemSignalLongSymbol" SG_ 1322 P02_PCU_S_BatteryChillerValveSta "P02_PCU_S_BatteryChillerValveStatus";
BA_ "SPN" SG_ 1322 P02_PCU_S_PressureSwitchState 2200;
BA_ "SPN" SG_ 1322 P02_PCU_S_AirConditionerKeyState 2188;
BA_ "SPN" SG_ 1322 P02_PCU_S_BatteryPackSlowChargeW 2187;
BA_ "SystemSignalLongSymbol" SG_ 1322 P02_PCU_S_BatteryPackSlowChargeW "P02_PCU_S_BatteryPackSlowChargeWakeUpCommand";
BA_ "SPN" SG_ 1322 P02_PCU_S_BatteryPackQuickCharge 2186;
BA_ "SystemSignalLongSymbol" SG_ 1322 P02_PCU_S_BatteryPackQuickCharge "P02_PCU_S_BatteryPackQuickChargeWakeUpCommand";
BA_ "SPN" SG_ 1322 P02_PCU_S_BatteryPackKeyOnStatus 2185;
BA_ "SPN" SG_ 1322 P02_PCU_S_ReverseLightCommand 2184;
BA_ "SPN" SG_ 1322 P02_PCU_S_BatteryChillerValveCom 2183;
BA_ "SystemSignalLongSymbol" SG_ 1322 P02_PCU_S_BatteryChillerValveCom "P02_PCU_S_BatteryChillerValveCommand";
BA_ "SPN" SG_ 1322 P02_PCU_S_BlowerFanRelayPowerCom 2182;
BA_ "SystemSignalLongSymbol" SG_ 1322 P02_PCU_S_BlowerFanRelayPowerCom "P02_PCU_S_BlowerFanRelayPowerCommand";
BA_ "SPN" SG_ 1322 P02_PCU_S_FanHighSpeedRelayComma 2181;
BA_ "SystemSignalLongSymbol" SG_ 1322 P02_PCU_S_FanHighSpeedRelayComma "P02_PCU_S_FanHighSpeedRelayCommand";
BA_ "SPN" SG_ 1322 P02_PCU_S_HMIPowerCommand 2180;
BA_ "SPN" SG_ 1322 P02_PCU_S_CabinCoolerValvePowerC 2179;
BA_ "SystemSignalLongSymbol" SG_ 1322 P02_PCU_S_CabinCoolerValvePowerC "P02_PCU_S_CabinCoolerValvePowerCommand";
BA_ "SPN" SG_ 1322 P02_PCU_S_EDUPumpCommand 2178;
BA_ "SPN" SG_ 1322 P02_PCU_S_BatteryPackWaterPumpPo 2177;
BA_ "SystemSignalLongSymbol" SG_ 1322 P02_PCU_S_BatteryPackWaterPumpPo "P02_PCU_S_BatteryPackWaterPumpPowerCommand";
BA_ "SPN" SG_ 1322 P02_PCU_S_VacuumPumpCommand 2176;
BA_ "SPN" SG_ 1322 P02_PCU_S_FanLowSpeedRelayComman 2175;
BA_ "SystemSignalLongSymbol" SG_ 1322 P02_PCU_S_FanLowSpeedRelayComman "P02_PCU_S_FanLowSpeedRelayCommand";
BA_ "SPN" SG_ 1322 P02_PCU_S_KL15DCDCCommand 2174;
BA_ "SPN" SG_ 1322 P02_PCU_S_KL15FastChargeCommand 2173;
BA_ "SPN" SG_ 1322 P02_PCU_S_KL15MCUCommand 2172;
BA_ "SPN" SG_ 1306 P01_PCU_D_VIN4 2171;
BA_ "SPN" SG_ 1306 P01_PCU_D_VIN3 2170;
BA_ "SPN" SG_ 1306 P01_PCU_D_VIN2 2169;
BA_ "SPN" SG_ 1306 P01_PCU_D_VIN1 2168;
BA_ "SPN" SG_ 1306 P01_PCU_D_VIN0 2167;
BA_ "SPN" SG_ 1306 P01_PCU_D_VINIndex 2166;
BA_ "SPN" SG_ 1290 P00_PCU_S_OBDPermissionState 2163;
BA_ "SPN" SG_ 1290 P00_PCU_S_ActualGearState 2165;
BA_ "SPN" SG_ 1290 P00_PCU_D_VehicleSpeed 2162;
BA_ "SPN" SG_ 1290 P00_PCU_S_VehicleModeState 2160;
BA_ "SPN" SG_ 1290 P00_PCU_S_SystemModeState 2161;
VAL_ 1802 P35_PCU_S_VacuumPumpDisableState 1 "Active" 0 "Inactive" ;
VAL_ 1802 P35_PCU_S_TCSDisableState 1 "Active" 0 "Inactive" ;
VAL_ 1802 P35_PCU_S_SpeedLimit80kmState 1 "Active" 0 "Inactive" ;
VAL_ 1802 P35_PCU_S_SpeedLimit40kmState 1 "Active" 0 "Inactive" ;
VAL_ 1802 P35_PCU_S_SpeedLimit120kmState 1 "Active" 0 "Inactive" ;
VAL_ 1802 P35_PCU_S_SpeedLimit0kmState 1 "Active" 0 "Inactive" ;
VAL_ 1802 P35_PCU_S_RetardDisableState 1 "Active" 0 "Inactive" ;
VAL_ 1802 P35_PCU_S_DriveBodyPermissionSta 1 "Active" 0 "Inactive" ;
VAL_ 1802 P35_PCU_S_CruiseDisableState 1 "Active" 0 "Inactive" ;
VAL_ 1802 P35_PCU_S_CreepDisableState 1 "Active" 0 "Inactive" ;
VAL_ 1770 P34_PCU_S_PowerSavingState 1 "Off" 0 "On" ;
VAL_ 1770 P34_PCU_S_FlasherEnableState 3 "Fault" 2 "SNA" 1 "Enable" 0 "Disable" ;
VAL_ 1770 P34_PCU_S_DCDCEnableStatus 3 "Fault" 2 "SNA" 1 "Enable" 0 "Disable" ;
VAL_ 1770 P34_PCU_S_BrakeLightState 3 "Fault" 2 "SNA" 1 "Active" 0 "Inactive" ;
VAL_ 1082 P33_PCU_S_DCLState 2 "Normal" 1 "Low" 0 "Invalid" ;
VAL_ 1082 P33_PCU_S_CCLState 2 "Normal" 1 "Low" 0 "Invalid" ;
VAL_ 1082 P33_PCU_S_BatteryTempUniformityS 2 "Uniform" 1 "Non uniform" 0 "Invalid" ;
VAL_ 1082 P33_PCU_S_CompressorDeceleration 1 "Active" 0 "Inactive" ;
VAL_ 1066 P31_PCU_S_CruiseState 2 "Standby (idle)" 1 "Active" 0 "Off" ;
VAL_ 1034 P29_PCU_S_CruiseButtonOnState 1 "On" 0 "Off" ;
VAL_ 1034 P29_PCU_S_CruiseButtonOffState 1 "On" 0 "Off" ;
VAL_ 1034 P29_PCU_S_CruiseButtonIncreaseSt 1 "On" 0 "Off" ;
VAL_ 1034 P29_PCU_S_CruiseButtonDecreaseSt 1 "On" 0 "Off" ;
VAL_ 1034 P29_PCU_S_HillHoldActiveState 1 "Active" 0 "Inactive" ;
VAL_ 1034 P29_PCU_S_RetardActiveState 1 "Active" 0 "Inactive" ;
VAL_ 1034 P29_PCU_S_CruiseActiveState 1 "Active" 0 "Inactive" ;
VAL_ 1034 P29_PCU_S_CreepModeActiveState 1 "Active" 0 "Inactive" ;
VAL_ 1034 P29_PCU_S_AcceleratorModeActiveS 1 "Active" 0 "Inactive" ;
VAL_ 1034 P29_PCU_S_TCSActiveState 1 "Active" 0 "Inactive" ;
VAL_ 1578 P32_PCU_F_EEPROMCellCycleTimeout 1 "Fault" 0 "No fault" ;
VAL_ 1578 P32_PCU_F_EEPROMMCUIDTimeoutFaul 1 "Fault" 0 "No fault" ;
VAL_ 1578 P32_PCU_F_DOLFault 1 "Fault" 0 "No fault" ;
VAL_ 1578 P32_PCU_F_FanLowSpeedAbnormalFau 1 "Fault" 0 "No fault" ;
VAL_ 1578 P32_PCU_F_FanHighSpeedAbnormalFa 1 "Fault" 0 "No fault" ;
VAL_ 1578 P32_PCU_F_CabinCoolerValveOpenWi 1 "Fault" 0 "No fault" ;
VAL_ 1578 P32_PCU_F_BatteryChillerValveOpe 1 "Fault" 0 "No fault" ;
VAL_ 1578 P32_PCU_F_FanHighSpeedAbnormalPr 1 "Fault" 0 "No fault" ;
VAL_ 1578 P32_PCU_F_PressureSwitchAbnormal 1 "Fault" 0 "No fault" ;
VAL_ 1578 P32_PCU_F_PressureSwitchHardware 1 "Fault" 0 "No fault" ;
VAL_ 1578 P32_PCU_F_CabinCoolerValveShortC 1 "Fault" 0 "No fault" ;
VAL_ 1578 P32_PCU_F_BatteryChillerValveSho 1 "Fault" 0 "No fault" ;
VAL_ 1578 P32_PCU_F_FlashTimeoutFault 1 "Fault" 0 "No fault" ;
VAL_ 1578 P32_PCU_F_EEPROMODOTimeoutFault 1 "Fault" 0 "No fault" ;
VAL_ 1578 P32_PCU_F_CANFDTxFIFOFullFault 1 "Fault" 0 "No fault" ;
VAL_ 1578 P32_PCU_F_CANFDTxBusOffFault 1 "Fault" 0 "No fault" ;
VAL_ 1578 P32_PCU_F_CANFDTxBusPassiveFault 1 "Fault" 0 "No fault" ;
VAL_ 1578 P32_PCU_F_CANFDRxBusPassiveFault 1 "Fault" 0 "No fault" ;
VAL_ 1578 P32_PCU_F_DiSpiTemperatureShutDo 1 "Fault" 0 "No fault" ;
VAL_ 1578 P32_PCU_F_DiSpiCheckFault 1 "Fault" 0 "No fault" ;
VAL_ 1578 P32_PCU_F_DiSpiTemperatureWarnin 1 "Warning" 0 "No fault" ;
VAL_ 1578 P32_PCU_F_DiSpiOverVoltageFault 1 "Fault" 0 "No fault" ;
VAL_ 1578 P32_PCU_F_DiSpiUnderVoltageFault 1 "Fault" 0 "No fault" ;
VAL_ 1578 P32_PCU_F_DiSpiParityFault 1 "Fault" 0 "No fault" ;
VAL_ 1578 P32_PCU_F_DiSpiFault 1 "Fault" 0 "No fault" ;
VAL_ 1514 P26_PCU_S_RegenState 1 "On" 0 "Off" ;
VAL_ 1514 P26_PCU_S_RegenSOCDerateState 1 "Derated" 0 "Normal" ;
VAL_ 1514 P26_PCU_S_RegenMotorDerateState 1 "Derated" 0 "Normal" ;
VAL_ 1514 P26_PCU_S_RegenMCUDerateState 1 "Derated" 0 "Normal" ;
VAL_ 1514 P26_PCU_S_RegenBatteryDerateStat 1 "Derated" 0 "Normal" ;
VAL_ 1514 P26_PCU_S_HillholdPermissionStat 1 "Permitted" 0 "Denied" ;
VAL_ 1514 P26_PCU_S_ESCTorqueLimitActiveSt 1 "Active" 0 "Inactive" ;
VAL_ 1514 P26_PCU_S_DriveProcessorTempDera 1 "Derated" 0 "Normal" ;
VAL_ 1514 P26_PCU_S_DriveMotorDerateState 1 "Derated" 0 "Normal" ;
VAL_ 1514 P26_PCU_S_DriveMCUDerateState 1 "Derated" 0 "Normal" ;
VAL_ 1514 P26_PCU_S_DriveLVVoltageDerateSt 1 "Derated" 0 "Normal" ;
VAL_ 1514 P26_PCU_S_DriveBatteryDerateStat 1 "Derated" 0 "Normal" ;
VAL_ 1514 P26_PCU_S_DriveSOCDerateState 1 "Derated" 0 "Normal" ;
VAL_ 1514 P26_PCU_S_TCSPermissionState 1 "Permitted" 0 "Denied" ;
VAL_ 1514 P26_PCU_S_DrivePermissionState 1 "Permitted" 0 "Denied" ;
VAL_ 1514 P26_PCU_S_CreepPermissionState 1 "Permitted" 0 "Denied" ;
VAL_ 1514 P26_PCU_S_CruisePermissionState 1 "Permitted" 0 "Denied" ;
VAL_ 1514 P26_PCU_S_RetardPermissionState 1 "Permitted" 0 "Denied" ;
VAL_ 1514 P26_PCU_S_DriveDerateState 1 "Derated" 0 "Normal" ;
VAL_ 1514 P26_PCU_S_RegenDerateState 1 "Derated" 0 "Normal" ;
VAL_ 1194 P20_PCU_S_BatteryPackHeatingRequ 1 "Active" 0 "Inactive" ;
VAL_ 1194 P20_PCU_S_BatteryPackCoolantTemp 2 "Water in line heater " 1 "Battery pack coolant" 0 "Invalid" ;
VAL_ 1194 P20_PCU_S_BatteryPackMinTemperat 11 "Hyper cold" 10 "Super cold" 9 "Over cold" 8 "Cold" 7 "Cool" 6 "Hyper hot" 5 "Super hot" 4 "Over hot" 3 "Hot" 2 "Warm" 1 "Normal" 0 "Invalid" ;
VAL_ 1194 P20_PCU_S_BatteryPackTMSModeStat 14 "Safe shut down" 13 "Safe derate" 12 "Safe" 11 "Emergency shut down" 10 "Emergency derate" 9 "Emergency alarm" 7 "heating" 6 "Cooling high shut down" 5 "Cooling high derate" 4 "Cooling high" 2 "Cooling low" 0 "Idle" ;
VAL_ 1194 P20_PCU_S_BatteryPackCoolan_0000 11 "Hyper cold" 10 "Super cold" 9 "Over cold" 8 "Cold" 7 "Cool" 6 "Hyper hot" 5 "Super hot" 4 "Over hot" 3 "Hot" 2 "Warm" 1 "Normal" 0 "Invalid" ;
VAL_ 1194 P20_PCU_S_BatteryPackMaxTemperat 11 "Hyper cold" 10 "Super cold" 9 "Over cold" 8 "Cold" 7 "Cool" 6 "Hyper hot" 5 "Super hot" 4 "Over hot" 3 "Hot" 2 "Warm" 1 "Normal" 0 "Invalid" ;
VAL_ 1178 P19_PCU_S_DrivingModeState 1 "Sport" 0 "Eco" ;
VAL_ 1178 P19_PCU_S_OBCTemperatureState 11 "Hyper cold" 10 "Super cold" 9 "Over cold" 8 "Cold" 7 "Cool" 6 "Hyper hot" 5 "Super hot" 4 "Over hot" 3 "Hot" 2 "Warm" 1 "Normal" 0 "Invalid" ;
VAL_ 1178 P19_PCU_S_EDUDeviceMaximumPumpRe 5 "OBC" 4 "Coolant" 3 "DCDC" 2 "MCU" 1 "Motor" 0 "Invalid" ;
VAL_ 1178 P19_PCU_S_EDUTMSModeState 1 "Cooling" 14 "Safe shut down" 13 "Safe derate" 12 "Safe" 11 "Emergency shut down" 10 "Emergency derate" 9 "Emergency alarm" 6 "Cooling high shut down" 5 "Cooling high derate" 4 "Cooling high" 3 "Cooling medium" 2 "Cooling low" 0 "TMS idle" ;
VAL_ 1178 P19_PCU_S_MCUTemperatureState 11 "Hyper cold" 10 "Super cold" 9 "Over cold" 8 "Cold" 7 "Cool" 6 "Hyper hot" 5 "Super hot" 4 "Over hot" 3 "Hot" 2 "Warm" 1 "Normal" 0 "Invalid" ;
VAL_ 1162 P18_PCU_S_MotorTemperatureState 11 "Hyper cold" 10 "Super cold" 9 "Over cold" 8 "Cold" 7 "Cool" 6 "Hyper hot" 5 "Super hot" 4 "Over hot" 3 "Hot" 2 "Warm" 1 "Normal" 0 "Invalid" ;
VAL_ 1162 P18_PCU_S_DCDCTemperatureState 11 "Hyper cold" 10 "Super cold" 9 "Over cold" 8 "Cold" 7 "Cool" 6 "Hyper hot" 5 "Super hot" 4 "Over hot" 3 "Hot" 2 "Warm" 1 "Normal" 0 "Invalid" ;
VAL_ 1162 P18_PCU_S_CabinTMSModeState 8 "Heating with dehumidification (demist)" 7 "Heating" 1 "Cooling" 0 "Idle" ;
VAL_ 1162 P18_PCU_S_CabinCoolerValveComman 1 "Open" 0 "Closed" ;
VAL_ 1162 P18_PCU_S_BatteryPackHeaterEnabl 1 "On" 0 "Off" ;
VAL_ 1162 P18_PCU_S_BatteryChillerValveCom 1 "Open" 0 "Closed" ;
VAL_ 1146 P17_PCU_S_FanCommandState 2 "High" 1 "Low" 0 "Off" ;
VAL_ 1114 P24_PCU_F_OBCOverTemperatureFaul 3 "Reserved" 2 "Reserved" 1 "Fault" 0 "No fault" ;
VAL_ 1114 P24_PCU_F_MotorOverTemperatureWa 1 "Fault" 0 "No fault" ;
VAL_ 1114 P24_PCU_F_MotorOverTemperatureFa 1 "Fault" 0 "No fault" ;
VAL_ 1114 P24_PCU_F_MCUOverTemperatureWarn 1 "Fault" 0 "No fault" ;
VAL_ 1114 P24_PCU_F_MCUOverTemperatureFaul 1 "Fault" 0 "No fault" ;
VAL_ 1114 P24_PCU_F_DCDCOverTemperatureFau 1 "Fault" 0 "No fault" ;
VAL_ 1114 P24_PCU_F_BMSUnderTemperatureFau 3 "Reserved" 2 "Reserved" 1 "Fault" 0 "No fault" ;
VAL_ 1114 P24_PCU_F_BMSOverTemperatureFaul 3 "Reserved" 2 "Reserved" 1 "Fault" 0 "No fault" ;
VAL_ 1114 P24_PCU_S_BlowerFanSelectorState 1 "On" 0 "Off" ;
VAL_ 1482 P21_PCU_S_OBCReadyToWorkState 1 "Ready" 0 "Not ready" ;
VAL_ 1482 P21_PCU_S_MotorReadyToWorkState 1 "Ready" 0 "Not ready" ;
VAL_ 1482 P21_PCU_S_EDUWaterPumpReadyToWor 1 "Ready" 0 "Not ready" ;
VAL_ 1482 P21_PCU_S_DCDCReadyToWorkState 1 "Ready" 0 "Not ready" ;
VAL_ 1482 P21_PCU_S_CoolerCompressorReadyT 1 "Ready" 0 "Not ready" ;
VAL_ 1482 P21_PCU_S_CabinHeaterReadyToWork 1 "Ready" 0 "Not ready" ;
VAL_ 1482 P21_PCU_S_CabinCoolerValveReadyT 1 "Ready" 0 "Not ready" ;
VAL_ 1482 P21_PCU_S_BatteryPackWaterPumpRe 1 "Ready" 0 "Not ready" ;
VAL_ 1482 P21_PCU_S_BMSReadyToWorkState 1 "Ready" 0 "Not ready" ;
VAL_ 1482 P21_PCU_S_BatteryPackHeaterReady 1 "Ready" 0 "Not ready" ;
VAL_ 1482 P21_PCU_S_BatteryChillerValveRea 1 "Ready" 0 "Not ready" ;
VAL_ 1482 P21_PCU_S_OBCModeState 5 "Sleep" 4 "Fault" 3 "Heat" 2 "Charge" 1 "Standby" 0 "Initial value" ;
VAL_ 1482 P21_PCU_S_FastChargeModeState 7 "SNA" 6 "Error" 5 "Stop" 4 "Charging" 3 "Precharge" 2 "Isolation" 1 "Cable check" 0 "Initialize" ;
VAL_ 1482 P21_PCU_S_BMSModeState 7 "SNA" 4 "Error" 3 "Slow charge" 2 "Fast charge" 1 "Discharge" 0 "Power up" ;
VAL_ 1274 P16_PCU_F_TMSBatteryPackTemperat 1 "Fault" 0 "No fault" ;
VAL_ 1274 P16_PCU_F_EDUWaterPumpNoLoadingF 1 "Fault" 0 "No fault" ;
VAL_ 1274 P16_PCU_F_BatteryPackWaterPumpNo 1 "Fault" 0 "No fault" ;
VAL_ 1274 P16_PCU_F_TMSCoolingActuatorPowe 1 "Fault" 0 "No fault" ;
VAL_ 1274 P16_PCU_F_CoolerCompressorHVILFa 1 "Fault" 0 "No fault" ;
VAL_ 1274 P16_PCU_F_BatteryPackHeaterHVILF 1 "Fault" 0 "No fault" ;
VAL_ 1274 P16_PCU_F_BothPumpCommunicationF 1 "Fault" 0 "No fault" ;
VAL_ 1274 P16_PCU_F_BatteryPackHeaterOverC 1 "Fault" 0 "No fault" ;
VAL_ 1274 P16_PCU_F_TMSOBCShutdownFault 1 "Fault" 0 "No fault" ;
VAL_ 1274 P16_PCU_F_TMSMotorShutdownFault 1 "Fault" 0 "No fault" ;
VAL_ 1274 P16_PCU_F_TMSMCUShutdownFault 1 "Fault" 0 "No fault" ;
VAL_ 1274 P16_PCU_F_TMSDCDCShutdownFault 1 "Fault" 0 "No fault" ;
VAL_ 1274 P16_PCU_F_CoolerCompressorOverCu 1 "Fault" 0 "No fault" ;
VAL_ 1274 P16_PCU_F_AirConditionerKeyMisma 1 "Fault" 0 "No fault" ;
VAL_ 1274 P16_PCU_F_EDUCoolantTemperatureS 1 "Fault" 0 "No fault" ;
VAL_ 1274 P16_PCU_F_BatteryPackCoolantTemp 1 "Fault" 0 "No fault" ;
VAL_ 1274 P16_PCU_F_EDUWaterPumpUpdatePara 1 "Fault" 0 "No fault" ;
VAL_ 1274 P16_PCU_F_BatteryPackWaterPumpUp 1 "Fault" 0 "No fault" ;
VAL_ 1274 P16_PCU_F_BatteryPackHeaterHighV 1 "Fault" 0 "No fault" ;
VAL_ 1274 P16_PCU_F_BatteryPackHeaterPower 1 "Fault" 0 "No fault" ;
VAL_ 1274 P16_PCU_F_BatteryPackHeaterShort 1 "Fault" 0 "No fault" ;
VAL_ 1274 P16_PCU_F_CabinHeaterHighVoltage 1 "Fault" 0 "No fault" ;
VAL_ 1274 P16_PCU_F_CabinHeaterPowerUpFaul 1 "Fault" 0 "No fault" ;
VAL_ 1274 P16_PCU_F_CabinHeaterShortCircui 1 "Fault" 0 "No fault" ;
VAL_ 1274 P16_PCU_F_CoolerCompressorHighVo 1 "Fault" 0 "No fault" ;
VAL_ 1274 P16_PCU_F_EDUWaterPumpInternalFa 1 "Fault" 0 "No fault" ;
VAL_ 1274 P16_PCU_F_EDUWaterPumpCommunicat 1 "Fault" 0 "No fault" ;
VAL_ 1274 P16_PCU_F_CoolerCompressorUpdate 1 "Fault" 0 "No fault" ;
VAL_ 1274 P16_PCU_F_CoolerCompressorSpeedF 1 "Fault" 0 "No fault" ;
VAL_ 1274 P16_PCU_F_CoolerCompressorShortC 1 "Fault" 0 "No fault" ;
VAL_ 1274 P16_PCU_F_CoolerCompressorIntern 1 "Fault" 0 "No fault" ;
VAL_ 1274 P16_PCU_F_CoolerCompressorCommun 1 "Fault" 0 "No fault" ;
VAL_ 1274 P16_PCU_F_CabinCoolerValveFault 1 "Fault" 0 "No fault" ;
VAL_ 1274 P16_PCU_F_BatteryPackWaterPumpIn 1 "Fault" 0 "No fault" ;
VAL_ 1274 P16_PCU_F_BatteryPackWaterPumpCo 1 "Fault" 0 "No fault" ;
VAL_ 1274 P16_PCU_F_BatteryPackHeaterUpdat 1 "Fault" 0 "No fault" ;
VAL_ 1274 P16_PCU_F_BatteryPackHeaterInter 1 "Fault" 0 "No fault" ;
VAL_ 1274 P16_PCU_F_BatteryPackHeaterCommu 1 "Fault" 0 "No fault" ;
VAL_ 1274 P16_PCU_F_BatteryChillerValveFau 1 "Fault" 0 "No fault" ;
VAL_ 1274 P16_PCU_F_CabinHeaterUpdateParam 1 "Fault" 0 "No fault" ;
VAL_ 1274 P16_PCU_F_CabinHeaterInternalFau 1 "Fault" 0 "No fault" ;
VAL_ 1274 P16_PCU_F_CabinHeaterCommunicati 1 "Fault" 0 "No fault" ;
VAL_ 1258 P15_PCU_F_AirbagSignalFault 1 "Fault" 0 "No fault" ;
VAL_ 1258 P15_PCU_F_AirbagCrashFault 1 "Fault" 0 "No fault" ;
VAL_ 1258 P15_PCU_F_HMICommunicationFault 1 "Fault" 0 "No fault" ;
VAL_ 1242 P14_PCU_F_PCUCANTimeoutFault 1 "Fault" 0 "No fault" ;
VAL_ 1242 P14_PCU_F_EVSOCSlowOverLimitFaul 1 "Fault" 0 "No fault" ;
VAL_ 1242 P14_PCU_F_EVSOCFastOverLimitFaul 1 "Fault" 0 "No fault" ;
VAL_ 1242 P14_PCU_F_EVPluggingFault 1 "Fault" 0 "No fault" ;
VAL_ 1242 P14_PCU_F_EVHVOpenFault 1 "Fault" 0 "No fault" ;
VAL_ 1242 P14_PCU_F_MCUVINMismatchFault 1 "Fault" 0 "No fault" ;
VAL_ 1242 P14_PCU_F_EVAirbagCrashDetectedF 1 "Fault" 0 "No fault" ;
VAL_ 1242 P14_PCU_F_EVInPluggedFault 1 "Fault" 0 "No fault" ;
VAL_ 1242 P14_PCU_F_ProcessorMissingClockD 1 "Fault" 0 "No fault" ;
VAL_ 1242 P14_PCU_F_ProcessorOverTemperatu 1 "Fault" 0 "No fault" ;
VAL_ 1242 P14_PCU_F_5VSupplyUnderVoltageFa 1 "Fault" 0 "No fault" ;
VAL_ 1242 P14_PCU_F_5VSupplyOverVoltageFau 1 "Fault" 0 "No fault" ;
VAL_ 1242 P14_PCU_F_InputUnderVoltageFault 1 "Fault" 0 "No fault" ;
VAL_ 1242 P14_PCU_F_InputOverVoltageFault 1 "Fault" 0 "No fault" ;
VAL_ 1242 P14_PCU_F_EVStartSwitchFault 1 "Fault" 0 "No fault" ;
VAL_ 1242 P14_PCU_F_EVSOCLowFault 1 "Fault" 0 "No fault" ;
VAL_ 1242 P14_PCU_F_EVSOCLimitFault 1 "Fault" 0 "No fault" ;
VAL_ 1242 P14_PCU_F_EVPrechargeTimeoutFaul 1 "Fault" 0 "No fault" ;
VAL_ 1242 P14_PCU_F_EVDCUNotReadyFault 1 "Fault" 0 "No fault" ;
VAL_ 1242 P14_PCU_F_EVDCDCNotReadyFault 1 "Fault" 0 "No fault" ;
VAL_ 1242 P14_PCU_F_EVBMSOpenContactorFaul 1 "Fault" 0 "No fault" ;
VAL_ 1242 P14_PCU_F_EVChargeStopFault 1 "Fault" 0 "No fault" ;
VAL_ 1242 P14_PCU_F_EVBMSNotReadyFault 1 "Fault" 0 "No fault" ;
VAL_ 1226 P13_PCU_F_OBCOverCurrentFault 1 "Fault" 0 "No fault" ;
VAL_ 1226 P13_PCU_F_BMSModeFault 1 "Fault" 0 "No fault" ;
VAL_ 1226 P13_PCU_F_OBCHighVoltageFault 1 "Fault" 0 "No fault" ;
VAL_ 1226 P13_PCU_F_OBCShortCircuitFault 1 "Fault" 0 "No fault" ;
VAL_ 1226 P13_PCU_F_MCUHighVoltageFault 1 "Fault" 0 "No fault" ;
VAL_ 1226 P13_PCU_F_OBCUpdateParameterFaul 1 "Fault" 0 "No fault" ;
VAL_ 1226 P13_PCU_F_OBCInternalFault 1 "Fault" 0 "No fault" ;
VAL_ 1226 P13_PCU_F_OBCCommunicationFault 1 "Fault" 0 "No fault" ;
VAL_ 1226 P13_PCU_F_MCUUpdateParameterFaul 1 "Fault" 0 "No fault" ;
VAL_ 1226 P13_PCU_F_MCUInternalFault 1 "Fault" 0 "No fault" ;
VAL_ 1226 P13_PCU_F_MCUCommunicationFault 1 "Fault" 0 "No fault" ;
VAL_ 1226 P13_PCU_F_DCDCUpdateParameterFau 1 "Fault" 0 "No fault" ;
VAL_ 1226 P13_PCU_F_DCDCOverTemperatureFau 1 "Fault" 0 "No fault" ;
VAL_ 1226 P13_PCU_F_DCDCLVUnderVoltageFaul 1 "Fault" 0 "No fault" ;
VAL_ 1226 P13_PCU_F_DCDCInternalFault 1 "Fault" 0 "No fault" ;
VAL_ 1226 P13_PCU_F_DCDCHighVoltageFault 1 "Fault" 0 "No fault" ;
VAL_ 1226 P13_PCU_F_DCDCCommunicationFault 1 "Fault" 0 "No fault" ;
VAL_ 1226 P13_PCU_F_BMSUpdateParameterFaul 1 "Fault" 0 "No fault" ;
VAL_ 1226 P13_PCU_F_BMSInternalFault 1 "Fault" 0 "No fault" ;
VAL_ 1226 P13_PCU_F_BMSCommunicationFault 1 "Fault" 0 "No fault" ;
VAL_ 1226 P13_PCU_F_NegativeContactorWeldi 1 "Fault" 0 "No fault" ;
VAL_ 1226 P13_PCU_F_NegativeContactorMatch 1 "Fault" 0 "No fault" ;
VAL_ 1226 P13_PCU_F_PositiveContactorWeldi 1 "Fault" 0 "No fault" ;
VAL_ 1226 P13_PCU_F_PositiveContactorMatch 1 "Fault" 0 "No fault" ;
VAL_ 1226 P13_PCU_F_PrechargeContactorWeld 1 "Fault" 0 "No fault" ;
VAL_ 1226 P13_PCU_F_PrechargeContactorMatc 1 "Fault" 0 "No fault" ;
VAL_ 1210 P12_PCU_F_VacuumPumpPowerFault 1 "Fault" 0 "No fault" ;
VAL_ 1210 P12_PCU_F_EPSInternalFault 1 "Fault" 0 "No fault" ;
VAL_ 1210 P12_PCU_F_BrakePressureInvalidFa 1 "Fault" 0 "No fault" ;
VAL_ 1210 P12_PCU_F_AcceleratorPedalPositi 1 "Fault" 0 "No fault" ;
VAL_ 1210 P12_PCU_F_ESCCommunicationFault 1 "Fault" 0 "No fault" ;
VAL_ 1210 P12_PCU_F_EPSCommunicationFault 1 "Fault" 0 "No fault" ;
VAL_ 1210 P12_PCU_F_BrakeStopLightFault 1 "Fault" 0 "No fault" ;
VAL_ 1210 P12_PCU_F_SASUpdateParameterFaul 1 "Fault" 0 "No fault" ;
VAL_ 1210 P12_PCU_F_SASInternalFault 1 "Fault" 0 "No fault" ;
VAL_ 1210 P12_PCU_F_SASCommunicationFault 1 "Fault" 0 "No fault" ;
VAL_ 1210 P12_PCU_F_CruiseKeyOpenWireFault 1 "Fault" 0 "No fault" ;
VAL_ 1210 P12_PCU_F_ABSRearRightSpeedFault 1 "Fault" 0 "No fault" ;
VAL_ 1210 P12_PCU_F_ABSRearLeftSpeedFault 1 "Fault" 0 "No fault" ;
VAL_ 1210 P12_PCU_F_ABSFrontRightSpeedFaul 1 "Fault" 0 "No fault" ;
VAL_ 1210 P12_PCU_F_ABSFrontLeftSpeedFault 1 "Fault" 0 "No fault" ;
VAL_ 1210 P12_PCU_F_ABSCommunicationFault 1 "Fault" 0 "No fault" ;
VAL_ 1210 P12_PCU_F_BrakePedalMicroSwitchF 1 "Fault" 0 "No fault" ;
VAL_ 1210 P12_PCU_F_AcceleratorPedalP_0000 1 "Fault" 0 "No fault" ;
VAL_ 1210 P12_PCU_F_AcceleratorPedalP_0001 1 "Fault" 0 "No fault" ;
VAL_ 1210 P12_PCU_F_AcceleratorPedalP_0002 1 "Fault" 0 "No fault" ;
VAL_ 1210 P12_PCU_F_AcceleratorPedalP_0003 1 "Fault" 0 "No fault" ;
VAL_ 1210 P12_PCU_F_AcceleratorPedalP_0004 1 "Fault" 0 "No fault" ;
VAL_ 1210 P12_PCU_F_VacuumPumpSensorMalfun 1 "Fault" 0 "No fault" ;
VAL_ 1210 P12_PCU_F_VacuumPumpCurrentAbnor 1 "Fault" 0 "No fault" ;
VAL_ 1210 P12_PCU_F_VacuumPumpPowerAbnorma 1 "Fault" 0 "No fault" ;
VAL_ 1210 P12_PCU_F_VacuumPumpMajorFault 1 "Fault" 0 "No fault" ;
VAL_ 1210 P12_PCU_F_AcceleratorPedalP_0005 1 "Fault" 0 "No fault" ;
VAL_ 1210 P12_PCU_F_AcceleratorPedalP_0006 1 "Fault" 0 "No fault" ;
VAL_ 1210 P12_PCU_F_AcceleratorPedalP_0007 1 "Fault" 0 "No fault" ;
VAL_ 1210 P12_PCU_F_NDRUpdateParameterFaul 1 "Fault" 0 "No fault" ;
VAL_ 1210 P12_PCU_F_NDRInternalFault 1 "Fault" 0 "No fault" ;
VAL_ 1210 P12_PCU_F_NDRCommunicationFault 1 "Fault" 0 "No fault" ;
VAL_ 1466 P11_PCU_S_BrakePedalReadyToWork 1 "Ready" 0 "Not ready" ;
VAL_ 1466 P11_PCU_S_AcceleratorPedalPositi 1 "Ready" 0 "Not ready" ;
VAL_ 1466 P11_PCU_S_AcceleratorPedalP_0000 1 "Ready" 0 "Not ready" ;
VAL_ 1466 P11_PCU_S_VehicleReadyState 1 "Ready" 0 "Not ready" ;
VAL_ 1466 P11_PCU_S_EDUWaterPumpReadyToWor 1 "Ready" 0 "Not ready" ;
VAL_ 1466 P11_PCU_S_BatteryPackWaterPumpRe 1 "Ready" 0 "Not ready" ;
VAL_ 1466 P11_PCU_S_NDRReadyToWork 1 "Ready" 0 "Not ready" ;
VAL_ 1466 P11_PCU_S_OBCReadyToWork 1 "Ready" 0 "Not ready" ;
VAL_ 1466 P11_PCU_S_MCUReadyToWork 1 "Ready" 0 "Not ready" ;
VAL_ 1466 P11_PCU_S_DCDCReadyToWork 1 "Ready" 0 "Not ready" ;
VAL_ 1466 P11_PCU_S_CoolerCompressorReadyT 1 "Ready" 0 "Not ready" ;
VAL_ 1466 P11_PCU_S_CabinHeaterReadyToWork 1 "Ready" 0 "Not ready" ;
VAL_ 1466 P11_PCU_S_BMSReadyToWork 1 "Ready" 0 "Not ready" ;
VAL_ 1434 P09_PCU_S_BatteryChillerValveSta 1 "On" 0 "Off" ;
VAL_ 1434 P09_PCU_S_CabinCoolerValveStatus 1 "On" 0 "Off" ;
VAL_ 1434 P09_PCU_F_CabinCoolerValveMismat 1 "Fault" 0 "No fault" ;
VAL_ 1434 P09_PCU_S_OBDFanCommand 255 "Invalid" 2 "High" 1 "Low" 0 "Off" ;
VAL_ 1434 P09_PCU_F_EDUCoolantTemperatureO 1 "Fault" 0 "No fault" ;
VAL_ 1434 P09_PCU_F_EDUCoolantTemperatureS 1 "Fault" 0 "No fault" ;
VAL_ 1434 P09_PCU_F_BatteryPackCoolantTemp 1 "Fault" 0 "No fault" ;
VAL_ 1434 P09_PCU_F_BatteryPackCoolan_0000 1 "Fault" 0 "No fault" ;
VAL_ 1434 P09_PCU_S_CabinCoolerValveComman 1 "On" 0 "Off" ;
VAL_ 1434 P09_PCU_S_BatteryChillerValveCom 1 "On" 0 "Off" ;
VAL_ 1434 P09_PCU_F_BatteryChillerValveMis 1 "Fault" 0 "No fault" ;
VAL_ 1434 P09_PCU_S_FanCommandState 3 "Invalid" 2 "High" 1 "Low" 0 "Off" ;
VAL_ 1386 P06_PCU_D_BatteryPackCycle 65535 "Unavailable" ;
VAL_ 1386 P06_PCU_D_VehicleSpeed 255 "Unavailable" ;
VAL_ 1370 P05_PCU_S_BatteryPackHeaterHVILS 1 "Disconnect" 0 "Connect" ;
VAL_ 1370 P05_PCU_S_CoolerCompressorHVILSt 1 "Disconnect" 0 "Connect" ;
VAL_ 1370 P05_PCU_S_CoolingActuatorPowerSt 1 "On" 0 "Off" ;
VAL_ 1370 P05_PCU_S_VacuumPumpPowerStatus 1 "On" 0 "Off" ;
VAL_ 1370 P05_PCU_S_StartSwitchState 1 "Off" 0 "On" ;
VAL_ 1370 P05_PCU_S_FanHighAndLowSpeedStat 1 "On" 0 "Off" ;
VAL_ 1322 P02_PCU_S_PressureSwitchFanHighS 1 "Active" 0 "Inactive" ;
VAL_ 1322 P02_PCU_S_VehiclePowerUpRelaySta 1 "Active" 0 "Inactive" ;
VAL_ 1322 P02_PCU_S_VacuumPumpPWMState 1 "On" 0 "Off" ;
VAL_ 1322 P02_PCU_S_BlowerFanSelectorState 1 "Off" 0 "On" ;
VAL_ 1322 P02_PCU_S_FastChargeRelayStatus 1 "Active" 0 "Inactive" ;
VAL_ 1322 P02_PCU_S_ESCKeyState 1 "Released" 0 "Pressed" ;
VAL_ 1322 P02_PCU_S_BrakeMicroSwitchState 1 "Released" 0 "Pressed" ;
VAL_ 1322 P02_PCU_S_BrakeStopPedalState 1 "Pressed or regen active" 0 "Released and brake light off" ;
VAL_ 1322 P02_PCU_S_ACCState 1 "Inactive" 0 "Active" ;
VAL_ 1322 P02_PCU_S_IgnitionState 1 "Inactive" 0 "Active" ;
VAL_ 1322 P02_PCU_S_OBCPlugState 1 "Plugged" 0 "Unplugged" ;
VAL_ 1322 P02_PCU_S_CabinCoolerValveStatus 1 "Active" 0 "Inactive" ;
VAL_ 1322 P02_PCU_S_BatteryChillerValveSta 1 "Active" 0 "Inactive" ;
VAL_ 1322 P02_PCU_S_PressureSwitchState 1 "Normal" 0 "High/Low triggered" ;
VAL_ 1322 P02_PCU_S_AirConditionerKeyState 1 "On" 0 "Off" ;
VAL_ 1322 P02_PCU_S_BatteryPackSlowChargeW 1 "Active" 0 "Inactive" ;
VAL_ 1322 P02_PCU_S_BatteryPackQuickCharge 1 "Active" 0 "Inactive" ;
VAL_ 1322 P02_PCU_S_BatteryPackKeyOnStatus 1 "Active" 0 "Inactive" ;
VAL_ 1322 P02_PCU_S_ReverseLightCommand 1 "Active" 0 "Inactive" ;
VAL_ 1322 P02_PCU_S_BatteryChillerValveCom 1 "Active" 0 "Inactive" ;
VAL_ 1322 P02_PCU_S_BlowerFanRelayPowerCom 1 "Active" 0 "Inactive" ;
VAL_ 1322 P02_PCU_S_FanHighSpeedRelayComma 1 "Active" 0 "Inactive" ;
VAL_ 1322 P02_PCU_S_HMIPowerCommand 1 "Active" 0 "Inactive" ;
VAL_ 1322 P02_PCU_S_CabinCoolerValvePowerC 1 "Active" 0 "Inactive" ;
VAL_ 1322 P02_PCU_S_EDUPumpCommand 1 "Active" 0 "Inactive" ;
VAL_ 1322 P02_PCU_S_BatteryPackWaterPumpPo 1 "Active" 0 "Inactive" ;
VAL_ 1322 P02_PCU_S_VacuumPumpCommand 1 "Active" 0 "Inactive" ;
VAL_ 1322 P02_PCU_S_FanLowSpeedRelayComman 1 "Active" 0 "Inactive" ;
VAL_ 1322 P02_PCU_S_KL15DCDCCommand 1 "Active" 0 "Inactive" ;
VAL_ 1322 P02_PCU_S_KL15FastChargeCommand 1 "Active" 0 "Inactive" ;
VAL_ 1322 P02_PCU_S_KL15MCUCommand 1 "Active" 0 "Inactive" ;
VAL_ 1290 P00_PCU_S_OBDPermissionState 1 "Active" 0 "Inactive" ;
VAL_ 1290 P00_PCU_S_ActualGearState 15 "Invalid" 10 "None" 4 "S" 3 "R" 2 "D" 1 "N" 0 "P" ;
VAL_ 1290 P00_PCU_D_VehicleSpeed 254 "Invalid" 255 "Unavailable" ;
VAL_ 1290 P00_PCU_S_VehicleModeState 5 "Slow charge" 4 "Fast charge" 3 "Ready" 2 "Change over" 1 "Precharge" 0 "Off" ;
VAL_ 1290 P00_PCU_S_SystemModeState 9 "SNA" 8 "Safe" 7 "Secure shutdown" 6 "Degraded" 5 "OBD" 4 "Operational" 3 "Pre operational" 2 "Warmup" 1 "Configuration" 0 "Initialization" ;
